VERSION ""

NS_ :

BS_:

BU_: WCM4 WCM3 WCM2 WCM VPM VLM VKM VICM VECM VDM VCU_RTOS_ETH VCU_ENTRY_ETH VCU_AGVM_ETH VCU UVM UPM TIM TEST_TOOL_1 TCP_ETH TCP TCM TCCM SRR_SRR_ETH SRR_SRR SRR_SLR_ETH SRR_SLR SRR_RR SRR_RF_ETH SRR_RF SRR_LR_CR SRR_LF_ETH SRR_LF SIB SDM SCL SBZA_R SBZA_L SBM SAM_RR SAM_RF SAM_LR SAM_LF SAM_BH SADS RadioLow_ETH RadioLow RSI_RTOS_ETH RSI RDCM PTM PLCM PFCM PDR_ETH PDR PCM PA ODS2 ODS NVM MTCM_R MTCM_L MSM_RR MSM_P MSM_LR MSM_D MSB2 MSB1 MRCM_R MRCM_L MFC LRR_RR_ETH LRR_LR_ETH LRR_CF_ETH LRR LRL_CF_ETH LIB_48V LIB1 IPC_INT IPC_GP IPC ICS_Info ICCM HVAC_FP_R HVAC_FP_F HUD_CAN HDLM FPI_RTOS_ETH FPI FOPM FCM_LC FCM EPSb EPS_1 EPSRAb EPSRAa EPS EOCM_HC_Superset EOCM_HCP2 EOCM ELM ECP_X1 ECP_S2 ECP_S ECP_MC ECP_H3 ECP_H2 ECP_H1 ECP_E ECM EBCM DMS DEFC DCM CSM_ETH CSM_AV CSM CGM_OTA_ETH CGM BSM_MH BSM_HEV BSM BCM ARS ARB APA AOS AMP ALC AHS AHL_AFL ADIMb ADIMa ACP2_MCU

BO_ 219 FCODP_BrstGrp_Prtctd_Consecuti10: 64 ACP2_MCU
 SG_ FCODPB8P_FVLBTk8CrvAuth : 3|16@0- (9.77e-07,0) [-0.0320143|0.0320134] "1/m" EOCM,EOCM_HCP2,EOCM_HC_Superset,HDLM
 SG_ FCODPB8P_FVLBTk8ClrAuth : 5|2@0+ (1,0) [0|3] "" EOCM,EOCM_HCP2,EOCM_HC_Superset,HDLM
 SG_ FCODPB8P_BrstID : 7|2@0+ (1,0) [0|3] "" EOCM,EOCM_HCP2,EOCM_HC_Superset,HDLM
 SG_ FCODPB8P_FVLBTk8CrvDrvtAuth : 19|16@0- (3.73e-09,0) [-0.000122225|0.000122221] "1/m^2" EOCM,EOCM_HCP2,EOCM_HC_Superset,HDLM
 SG_ FCODPB8P_FVLBTk8FPSABCQOvrAuth : 35|7@0+ (1,0) [0|127] "%" EOCM,EOCM_HCP2,EOCM_HC_Superset,HDLM
 SG_ FCODPB8P_FVLBTk8FPSAQAuth : 44|7@0+ (1,0) [0|127] "%" EOCM,EOCM_HCP2,EOCM_HC_Superset,HDLM
 SG_ FCODPB8P_FVLBTk8FPSBQAuth : 53|7@0+ (1,0) [0|127] "%" EOCM,EOCM_HCP2,EOCM_HC_Superset,HDLM
 SG_ FCODPB8P_FVLBTk8FPSCQAuth : 62|7@0+ (1,0) [0|127] "%" EOCM,EOCM_HCP2,EOCM_HC_Superset,HDLM
 SG_ FCODPB8P_FVLBTk8HdgAuth : 71|10@0- (0.000977,0) [-0.500224|0.499247] "" EOCM,EOCM_HCP2,EOCM_HC_Superset,HDLM
 SG_ FCODPB8P_FVLBTk8OfstAuth : 77|13@0- (0.003906,0) [-15.999|15.9951] "m" EOCM,EOCM_HCP2,EOCM_HC_Superset,HDLM
 SG_ FCODPB8P_FVLBTk8PstnTypAuth : 80|4@0+ (1,0) [0|12] "" EOCM,EOCM_HCP2,EOCM_HC_Superset,HDLM
 SG_ FCODPB8P_FVLBTk8TypAuth : 90|3@0+ (1,0) [0|7] "" EOCM,EOCM_HCP2,EOCM_HC_Superset,HDLM
 SG_ FCODPB8P_FVLBTk8QltyAuth : 92|2@0+ (1,0) [0|3] "" EOCM,EOCM_HCP2,EOCM_HC_Superset,HDLM
 SG_ FCODPB8P_FVLBTk8VSLgDistAuth : 96|7@0+ (1,0) [0|127] "m" EOCM,EOCM_HCP2,EOCM_HC_Superset,HDLM
 SG_ FCODPB8P_FVLBTk8VRLgDistAuth : 103|7@0+ (1,0) [0|127] "m" EOCM,EOCM_HCP2,EOCM_HC_Superset,HDLM
 SG_ FCODPB8P_FVLBTk8WdthAuth : 105|6@0+ (0.01,0) [0|0.63] "m" EOCM,EOCM_HCP2,EOCM_HC_Superset,HDLM
 SG_ FCODPB8P_FVVOTk8CICOPotAuth : 113|6@0+ (2,0) [0|126] "%" EOCM,EOCM_HCP2,EOCM_HC_Superset,HDLM
 SG_ FCODPB8P_FVVOTk8BrkLgtStsAuth : 115|2@0+ (1,0) [0|3] "" EOCM,EOCM_HCP2,EOCM_HC_Superset,HDLM
 SG_ FCODPB8P_FVVOTk8DynPrpAuth : 121|3@0+ (1,0) [0|6] "" EOCM,EOCM_HCP2,EOCM_HC_Superset,HDLM
 SG_ FCODPB8P_FVVOTk8CnfdStsAuth : 123|2@0+ (1,0) [0|3] "" EOCM,EOCM_HCP2,EOCM_HC_Superset,HDLM
 SG_ FCODPB8P_FVVOTk8HdgAngAuth : 133|11@0- (0.002,0) [-2.048|2.046] "rad" EOCM,EOCM_HCP2,EOCM_HC_Superset,HDLM
 SG_ FCODPB8P_FVVOTk8DynPrpStsAuth : 134|1@0+ (1,0) [0|1] "" EOCM,EOCM_HCP2,EOCM_HC_Superset,HDLM
 SG_ FCODPB8P_FVVOTk8HdgAngCAuth : 138|13@0- (0.002,0) [-8.192|8.19] "rad" EOCM,EOCM_HCP2,EOCM_HC_Superset,HDLM
 SG_ FCODPB8P_FVVOTk8IDAuth : 157|6@0+ (1,0) [0|63] "" EOCM,EOCM_HCP2,EOCM_HC_Superset,HDLM
 SG_ FCODPB8P_FVVOTk8PoILAAuth : 162|9@0- (0.125,0) [-32|31.875] "m/s^2" EOCM,EOCM_HCP2,EOCM_HC_Superset,HDLM
 SG_ FCODPB8P_FVVOTk8MStsAuth : 164|2@0+ (1,0) [0|3] "" EOCM,EOCM_HCP2,EOCM_HC_Superset,HDLM
 SG_ FCODPB8P_FVVOTk8LnAsmtAuth : 167|3@0+ (1,0) [0|5] "" EOCM,EOCM_HCP2,EOCM_HC_Superset,HDLM
 SG_ FCODPB8P_FVVOTk8PoILgAAuth : 169|9@0- (0.125,0) [-32|31.875] "m/s^2" EOCM,EOCM_HCP2,EOCM_HC_Superset,HDLM
 SG_ FCODPB8P_FVVOTk8PoILgPsAuth : 176|11@0+ (0.125,0) [0|255.875] "m" EOCM,EOCM_HCP2,EOCM_HC_Superset,HDLM
 SG_ FCODPB8P_FVVOTk8PoILgPsCAuth : 197|15@0+ (0.01,0) [0|327.67] "m^2" EOCM,EOCM_HCP2,EOCM_HC_Superset,HDLM
 SG_ FCODPB8P_FVVOTk8PoILgVAuth : 214|11@0- (0.125,0) [-128|127.875] "m/s" EOCM,EOCM_HCP2,EOCM_HC_Superset,HDLM
 SG_ FCODPB8P_FVVOTk8PoILgVCAuth : 219|10@0+ (0.125,0) [0|127.875] "(m/s)^2" EOCM,EOCM_HCP2,EOCM_HC_Superset,HDLM
 SG_ FCODPB8P_FVVOTk8PoILPsAuth : 225|10@0- (0.125,0) [-64|63.875] "m" EOCM,EOCM_HCP2,EOCM_HC_Superset,HDLM
 SG_ FCODPB8P_FVVOTk8PoILPsCAuth : 247|14@0+ (0.01,0) [0|163.83] "m^2" EOCM,EOCM_HCP2,EOCM_HC_Superset,HDLM
 SG_ FCODPB8P_FVVOTk8PoILVAuth : 249|9@0- (0.125,0) [-32|31.875] "m/s" EOCM,EOCM_HCP2,EOCM_HC_Superset,HDLM
 SG_ FCODPB8P_FVVOTk8PoILVCAuth : 256|10@0+ (0.125,0) [0|127.875] "(m/s)^2" EOCM,EOCM_HCP2,EOCM_HC_Superset,HDLM
 SG_ FCODPB8P_FVVOTk8PoIWAuth : 278|7@0+ (0.125,0) [0|15.875] "m" EOCM,EOCM_HCP2,EOCM_HC_Superset,HDLM
 SG_ FCODPB8P_FVVOTk9BrkLgtStsAuth : 280|2@0+ (1,0) [0|3] "" EOCM,EOCM_HCP2,EOCM_HC_Superset,HDLM
 SG_ FCODPB8P_FVVOTk8TypCnfdAuth : 282|2@0+ (1,0) [0|3] "" EOCM,EOCM_HCP2,EOCM_HC_Superset,HDLM
 SG_ FCODPB8P_FVVOTk8TypAuth : 284|2@0+ (1,0) [0|3] "" EOCM,EOCM_HCP2,EOCM_HC_Superset,HDLM
 SG_ FCODPB8P_FVVOTk8TSLgtStsAuth : 287|3@0+ (1,0) [0|4] "" EOCM,EOCM_HCP2,EOCM_HC_Superset,HDLM
 SG_ FCODPB8P_FVVOTk9CnfdStsAuth : 288|2@0+ (1,0) [0|3] "" EOCM,EOCM_HCP2,EOCM_HC_Superset,HDLM
 SG_ FCODPB8P_FVVOTk9CICOPotAuth : 294|6@0+ (2,0) [0|126] "%" EOCM,EOCM_HCP2,EOCM_HC_Superset,HDLM
 SG_ FCODPB8P_FVVOTk9HdgAngAuth : 298|11@0- (0.002,0) [-2.048|2.046] "rad" EOCM,EOCM_HCP2,EOCM_HC_Superset,HDLM
 SG_ FCODPB8P_FVVOTk9DynPrpStsAuth : 299|1@0+ (1,0) [0|1] "" EOCM,EOCM_HCP2,EOCM_HC_Superset,HDLM
 SG_ FCODPB8P_FVVOTk9DynPrpAuth : 302|3@0+ (1,0) [0|6] "" EOCM,EOCM_HCP2,EOCM_HC_Superset,HDLM
 SG_ FCODPB8P_FVVOTk9HdgAngCAuth : 319|13@0- (0.002,0) [-8.192|8.19] "rad" EOCM,EOCM_HCP2,EOCM_HC_Superset,HDLM
 SG_ FCODPB8P_FVVOTk9IDAuth : 322|6@0+ (1,0) [0|63] "" EOCM,EOCM_HCP2,EOCM_HC_Superset,HDLM
 SG_ FCODPB8P_FVVOTk9MStsAuth : 329|2@0+ (1,0) [0|3] "" EOCM,EOCM_HCP2,EOCM_HC_Superset,HDLM
 SG_ FCODPB8P_FVVOTk9LnAsmtAuth : 332|3@0+ (1,0) [0|5] "" EOCM,EOCM_HCP2,EOCM_HC_Superset,HDLM
 SG_ FCODPB8P_FVVOTk9PoILAAuth : 343|9@0- (0.125,0) [-32|31.875] "m/s^2" EOCM,EOCM_HCP2,EOCM_HC_Superset,HDLM
 SG_ FCODPB8P_FVVOTk9PoILgAAuth : 350|9@0- (0.125,0) [-32|31.875] "m/s^2" EOCM,EOCM_HCP2,EOCM_HC_Superset,HDLM
 SG_ FCODPB8P_FVVOTk9PoILgPsAuth : 357|11@0+ (0.125,0) [0|255.875] "m" EOCM,EOCM_HCP2,EOCM_HC_Superset,HDLM
 SG_ FCODPB8P_FVVOTk9PoILgPsCAuth : 362|15@0+ (0.01,0) [0|327.67] "m^2" EOCM,EOCM_HCP2,EOCM_HC_Superset,HDLM
 SG_ FCODPB8P_FVVOTk9PoILgVAuth : 379|11@0- (0.125,0) [-128|127.875] "m/s" EOCM,EOCM_HCP2,EOCM_HC_Superset,HDLM
 SG_ FCODPB8P_FVVOTk9PoILgVCAuth : 384|10@0+ (0.125,0) [0|127.875] "(m/s)^2" EOCM,EOCM_HCP2,EOCM_HC_Superset,HDLM
 SG_ FCODPB8P_FVVOTk9PoILPsAuth : 406|10@0- (0.125,0) [-64|63.875] "m" EOCM,EOCM_HCP2,EOCM_HC_Superset,HDLM
 SG_ FCODPB8P_FVVOTk9PoILPsCAuth : 412|14@0+ (0.01,0) [0|163.83] "m^2" EOCM,EOCM_HCP2,EOCM_HC_Superset,HDLM
 SG_ FCODPB8P_FVVOTk9PoILVAuth : 430|9@0- (0.125,0) [-32|31.875] "m/s" EOCM,EOCM_HCP2,EOCM_HC_Superset,HDLM
 SG_ FCODPB8P_FVVOTk9PoILVCAuth : 437|10@0+ (0.125,0) [0|127.875] "(m/s)^2" EOCM,EOCM_HCP2,EOCM_HC_Superset,HDLM
 SG_ FCODPB8P_FVVOTk9PoIWAuth : 443|7@0+ (0.125,0) [0|15.875] "m" EOCM,EOCM_HCP2,EOCM_HC_Superset,HDLM
 SG_ FCODPB8P_FVVOTk9TypAuth : 449|2@0+ (1,0) [0|3] "" EOCM,EOCM_HCP2,EOCM_HC_Superset,HDLM
 SG_ FCODPB8P_FVVOTk9TSLgtStsAuth : 452|3@0+ (1,0) [0|4] "" EOCM,EOCM_HCP2,EOCM_HC_Superset,HDLM
 SG_ FCODPB8P_Filler : 457|28@0+ (1,0) [0|2.68435e+008] "" EOCM,EOCM_HCP2,EOCM_HC_Superset,HDLM
 SG_ FrwdVsnVehObjTk8DatIntegCkd : 459|2@0+ (1,0) [0|2] "" EOCM,EOCM_HCP2,EOCM_HC_Superset,HDLM
 SG_ FrwdVsnLnBdryTk8DatIntegCkd : 461|2@0+ (1,0) [0|2] "" EOCM,EOCM_HCP2,EOCM_HC_Superset,HDLM
 SG_ FCODPB8P_FVVOTk9TypCnfdAuth : 463|2@0+ (1,0) [0|3] "" EOCM,EOCM_HCP2,EOCM_HC_Superset,HDLM
 SG_ FCODPB8P_FillerExtnd : 493|19@0+ (1,0) [0|524287] "" EOCM,EOCM_HCP2,EOCM_HC_Superset,HDLM

BO_ 237 FCODP_BrstGrp_Prtctd_Consecuti11: 48 ACP2_MCU
 SG_ FCODPB9P_FVCIPthVehAlrtNwAuth : 0|1@0+ (1,0) [0|1] "" EOCM,EOCM_HCP2,EOCM_HC_Superset,HDLM
 SG_ FCODPB9P_FVCIPthVehAhdNwAuth : 1|1@0+ (1,0) [0|1] "" EOCM,EOCM_HCP2,EOCM_HC_Superset,HDLM
 SG_ FCODPB9P_FrwdDistIndDgrdAuth : 2|1@0+ (1,0) [0|1] "" EOCM,EOCM_HCP2,EOCM_HC_Superset,HDLM
 SG_ FCODPB9P_FrwdClsnAlrtDgrdAuth : 3|1@0+ (1,0) [0|1] "" EOCM,EOCM_HCP2,EOCM_HC_Superset,HDLM
 SG_ FCODPB9P_ClsnImntBrkgDgrdAuth : 4|1@0+ (1,0) [0|1] "" EOCM,EOCM_HCP2,EOCM_HC_Superset,HDLM
 SG_ FCODPB9P_AdpCruzCtlDgrdAuth : 5|1@0+ (1,0) [0|1] "" EOCM,EOCM_HCP2,EOCM_HC_Superset,HDLM
 SG_ FCODPB9P_BrstID : 7|2@0+ (1,0) [0|3] "" EOCM,EOCM_HCP2,EOCM_HC_Superset,HDLM
 SG_ FCODPB9P_FVL1DrivableCnfdAuth : 11|7@0+ (1,0) [0|127] "%" EOCM,EOCM_HCP2,EOCM_HC_Superset,HDLM
 SG_ FCODPB9P_FVHTPNtfyNwAuth : 12|1@0+ (1,0) [0|1] "" EOCM,EOCM_HCP2,EOCM_HC_Superset,HDLM
 SG_ FCODPB9P_FVHTPBrkNwAuth : 13|1@0+ (1,0) [0|1] "" EOCM,EOCM_HCP2,EOCM_HC_Superset,HDLM
 SG_ FCODPB9P_FVHTPAlrtNwAuth : 14|1@0+ (1,0) [0|1] "" EOCM,EOCM_HCP2,EOCM_HC_Superset,HDLM
 SG_ FCODPB9P_FVCIPthVehBrkNwAuth : 15|1@0+ (1,0) [0|1] "" EOCM,EOCM_HCP2,EOCM_HC_Superset,HDLM
 SG_ FCODPB9P_FVL2DrivableCnfdAuth : 20|7@0+ (1,0) [0|127] "%" EOCM,EOCM_HCP2,EOCM_HC_Superset,HDLM
 SG_ FCODPB9P_FVL3DrivableCnfdAuth : 29|7@0+ (1,0) [0|127] "%" EOCM,EOCM_HCP2,EOCM_HC_Superset,HDLM
 SG_ FCODPB9P_FVL4DrivableCnfdAuth : 38|7@0+ (1,0) [0|127] "%" EOCM,EOCM_HCP2,EOCM_HC_Superset,HDLM
 SG_ FCODPB9P_FVLFTk1FPCrvCoefAuth : 40|16@0- (9.77e-07,0) [-0.0320143|0.0320134] "1/m" EOCM,EOCM_HCP2,EOCM_HC_Superset,HDLM
 SG_ FCODPB9P_FVL5DrivableCnfdAuth : 47|7@0+ (1,0) [0|127] "%" EOCM,EOCM_HCP2,EOCM_HC_Superset,HDLM
 SG_ FCODPB9P_FVLFTk1FPCrvDrvtCAuth : 56|16@0- (3.73e-09,0) [-0.000122225|0.000122221] "1/m^2" EOCM,EOCM_HCP2,EOCM_HC_Superset,HDLM
 SG_ FCODPB9P_FVLFTk1FPHdgCoefAuth : 72|10@0- (0.000977,0) [-0.500224|0.499247] "rad" EOCM,EOCM_HCP2,EOCM_HC_Superset,HDLM
 SG_ FCODPB9P_FVLFTk1FPOfstCoefAuth : 94|12@0- (0.003906,0) [-7.99949|7.99558] "m" EOCM,EOCM_HCP2,EOCM_HC_Superset,HDLM
 SG_ FCODPB9P_FVLFTk1FPSegQltyAuth : 98|7@0+ (1,0) [0|127] "%" EOCM,EOCM_HCP2,EOCM_HC_Superset,HDLM
 SG_ FCODPB9P_FVLFTk1FPVRLgDistAuth : 107|7@0+ (1,0) [0|127] "m" EOCM,EOCM_HCP2,EOCM_HC_Superset,HDLM
 SG_ FCODPB9P_FVLFTk1FPVSLgDistAuth : 116|7@0+ (1,0) [0|127] "m" EOCM,EOCM_HCP2,EOCM_HC_Superset,HDLM
 SG_ FCODPB9P_FVLFTk2FPCrvCoefAuth : 123|16@0- (9.77e-07,0) [-0.0320143|0.0320134] "1/m" EOCM,EOCM_HCP2,EOCM_HC_Superset,HDLM
 SG_ FCODPB9P_FVLFTk1TypAuth : 125|2@0+ (1,0) [0|3] "" EOCM,EOCM_HCP2,EOCM_HC_Superset,HDLM
 SG_ FCODPB9P_FVLFTk2FPCrvDrvtCAuth : 139|16@0- (3.73e-09,0) [-0.000122225|0.000122221] "1/m^2" EOCM,EOCM_HCP2,EOCM_HC_Superset,HDLM
 SG_ FCODPB9P_FVLFTk2FPHdgCoefAuth : 155|10@0- (0.000977,0) [-0.500224|0.499247] "rad" EOCM,EOCM_HCP2,EOCM_HC_Superset,HDLM
 SG_ FCODPB9P_FVLFTk2FPOfstCoefAuth : 161|12@0- (0.003906,0) [-7.99949|7.99558] "m" EOCM,EOCM_HCP2,EOCM_HC_Superset,HDLM
 SG_ FCODPB9P_FVLFTk2FPSegQltyAuth : 181|7@0+ (1,0) [0|127] "%" EOCM,EOCM_HCP2,EOCM_HC_Superset,HDLM
 SG_ FCODPB9P_FVLFTk2FPVRLgDistAuth : 190|7@0+ (1,0) [0|127] "m" EOCM,EOCM_HCP2,EOCM_HC_Superset,HDLM
 SG_ FCODPB9P_FVLFTk2TypAuth : 192|2@0+ (1,0) [0|3] "" EOCM,EOCM_HCP2,EOCM_HC_Superset,HDLM
 SG_ FCODPB9P_FVLFTk2FPVSLgDistAuth : 199|7@0+ (1,0) [0|127] "m" EOCM,EOCM_HCP2,EOCM_HC_Superset,HDLM
 SG_ FCODPB9P_FVLFTk3FPCrvCoefAuth : 206|16@0- (9.77e-07,0) [-0.0320143|0.0320134] "1/m" EOCM,EOCM_HCP2,EOCM_HC_Superset,HDLM
 SG_ FCODPB9P_FVLFTk3FPCrvDrvtCAuth : 222|16@0- (3.73e-09,0) [-0.000122225|0.000122221] "1/m^2" EOCM,EOCM_HCP2,EOCM_HC_Superset,HDLM
 SG_ FCODPB9P_FVLFTk3FPHdgCoefAuth : 238|10@0- (0.000977,0) [-0.500224|0.499247] "rad" EOCM,EOCM_HCP2,EOCM_HC_Superset,HDLM
 SG_ FCODPB9P_FVLFTk3FPOfstCoefAuth : 244|12@0- (0.003906,0) [-7.99949|7.99558] "m" EOCM,EOCM_HCP2,EOCM_HC_Superset,HDLM
 SG_ FCODPB9P_FVLFTk3FPSegQltyAuth : 248|7@0+ (1,0) [0|127] "%" EOCM,EOCM_HCP2,EOCM_HC_Superset,HDLM
 SG_ FCODPB9P_FVLFTk3FPVRLgDistAuth : 257|7@0+ (1,0) [0|127] "m" EOCM,EOCM_HCP2,EOCM_HC_Superset,HDLM
 SG_ FCODPB9P_FVLFTk3FPVSLgDistAuth : 266|7@0+ (1,0) [0|127] "m" EOCM,EOCM_HCP2,EOCM_HC_Superset,HDLM
 SG_ FCODPB9P_FVLFTk4FPCrvCoefAuth : 273|16@0- (9.77e-07,0) [-0.0320143|0.0320134] "1/m" EOCM,EOCM_HCP2,EOCM_HC_Superset,HDLM
 SG_ FCODPB9P_FVLFTk3TypAuth : 275|2@0+ (1,0) [0|3] "" EOCM,EOCM_HCP2,EOCM_HC_Superset,HDLM
 SG_ FCODPB9P_FVLFTk4FPCrvDrvtCAuth : 289|16@0- (3.73e-09,0) [-0.000122225|0.000122221] "1/m^2" EOCM,EOCM_HCP2,EOCM_HC_Superset,HDLM
 SG_ FCODPB9P_FVLFTk4FPHdgCoefAuth : 305|10@0- (0.000977,0) [-0.500224|0.499247] "rad" EOCM,EOCM_HCP2,EOCM_HC_Superset,HDLM
 SG_ FCODPB9P_FVLFTk4FPOfstCoefAuth : 327|12@0- (0.003906,0) [-7.99949|7.99558] "m" EOCM,EOCM_HCP2,EOCM_HC_Superset,HDLM
 SG_ FCODPB9P_FVLFTk4FPSegQltyAuth : 331|7@0+ (1,0) [0|127] "%" EOCM,EOCM_HCP2,EOCM_HC_Superset,HDLM
 SG_ FCODPB9P_FVLFTk4FPVRLgDistAuth : 340|7@0+ (1,0) [0|127] "m" EOCM,EOCM_HCP2,EOCM_HC_Superset,HDLM
 SG_ FCODPB9P_FVLFTk4FPVSLgDistAuth : 349|7@0+ (1,0) [0|127] "m" EOCM,EOCM_HCP2,EOCM_HC_Superset,HDLM
 SG_ FCODPB9P_PedtrnClsnBrkgDgrdAuth : 352|1@0+ (1,0) [0|1] "" EOCM,EOCM_HCP2,EOCM_HC_Superset,HDLM
 SG_ FCODPB9P_PedtrnClsnAlrtDgrdAuth : 353|1@0+ (1,0) [0|1] "" EOCM,EOCM_HCP2,EOCM_HC_Superset,HDLM
 SG_ FCODPB9P_LnKeepAsstDgrdAuth : 354|1@0+ (1,0) [0|1] "" EOCM,EOCM_HCP2,EOCM_HC_Superset,HDLM
 SG_ FCODPB9P_LnCntrDgrdAuth : 355|1@0+ (1,0) [0|1] "" EOCM,EOCM_HCP2,EOCM_HC_Superset,HDLM
 SG_ FCODPB9P_IntsctClsnMtgnDgrdAuth : 356|1@0+ (1,0) [0|1] "" EOCM,EOCM_HCP2,EOCM_HC_Superset,HDLM
 SG_ FCODPB9P_FVLFTk4TypAuth : 358|2@0+ (1,0) [0|3] "" EOCM,EOCM_HCP2,EOCM_HC_Superset,HDLM
 SG_ FCODPB9P_Filler : 360|17@0+ (1,0) [0|131071] "" EOCM,EOCM_HCP2,EOCM_HC_Superset,HDLM
 SG_ FrwdVsnVehObjTk9DatIntegCkd : 362|2@0+ (1,0) [0|2] "" EOCM,EOCM_HCP2,EOCM_HC_Superset,HDLM
 SG_ FrwdVsnLnBdryTk9DatIntegCkd : 364|2@0+ (1,0) [0|2] "" EOCM,EOCM_HCP2,EOCM_HC_Superset,HDLM
 SG_ FCODPB9P_FVHTPPrfllNwAuth : 365|1@0+ (1,0) [0|1] "" EOCM,EOCM_HCP2,EOCM_HC_Superset,HDLM
 SG_ FCODPB9P_FVCIPthVehPrfllNwAuth : 366|1@0+ (1,0) [0|1] "" EOCM,EOCM_HCP2,EOCM_HC_Superset,HDLM
 SG_ FCODPB9P_PedtrnNtfnDgrdAuth : 367|1@0+ (1,0) [0|1] "" EOCM,EOCM_HCP2,EOCM_HC_Superset,HDLM

BO_ 218 FCODP_BrstGrp_Prtctd_Consecuti12: 64 ACP2_MCU
 SG_ FCODPB10P_FVVOTk10PoI2LgPsAuth : 3|11@0+ (0.125,0) [0|255.875] "m" EOCM,EOCM_HCP2,EOCM_HC_Superset,HDLM
 SG_ FCODPB10P_FVVOTk10PoI1PsVisAuth : 5|2@0+ (1,0) [0|2] "" EOCM,EOCM_HCP2,EOCM_HC_Superset,HDLM
 SG_ FCODPB10P_BrstID : 7|2@0+ (1,0) [0|3] "" EOCM,EOCM_HCP2,EOCM_HC_Superset,HDLM
 SG_ FCODPB10P_FVVOTk10PoI2LPsAuth : 8|10@0+ (0.125,-64) [-64|63.875] "m" EOCM,EOCM_HCP2,EOCM_HC_Superset,HDLM
 SG_ FCODPB10P_FVVOTk10PoI3LgPsAuth : 28|11@0+ (0.125,0) [0|255.875] "m" EOCM,EOCM_HCP2,EOCM_HC_Superset,HDLM
 SG_ FCODPB10P_FVVOTk10PoI2PsVisAuth : 30|2@0+ (1,0) [0|2] "" EOCM,EOCM_HCP2,EOCM_HC_Superset,HDLM
 SG_ FCODPB10P_FVVOTk10PoI3LPsAuth : 33|10@0+ (0.125,-64) [-64|63.875] "m" EOCM,EOCM_HCP2,EOCM_HC_Superset,HDLM
 SG_ FCODPB10P_FVVOTk1PoI2LgPsAuth : 51|11@0+ (0.125,0) [0|255.875] "m" EOCM,EOCM_HCP2,EOCM_HC_Superset,HDLM
 SG_ FCODPB10P_FVVOTk1PoI1PsVisAuth : 53|2@0+ (1,0) [0|2] "" EOCM,EOCM_HCP2,EOCM_HC_Superset,HDLM
 SG_ FCODPB10P_FVVOTk10PoI3PsVisAuth : 55|2@0+ (1,0) [0|2] "" EOCM,EOCM_HCP2,EOCM_HC_Superset,HDLM
 SG_ FCODPB10P_FVVOTk1PoI2LPsAuth : 56|10@0+ (0.125,-64) [-64|63.875] "m" EOCM,EOCM_HCP2,EOCM_HC_Superset,HDLM
 SG_ FCODPB10P_FVVOTk1PoI3LgPsAuth : 76|11@0+ (0.125,0) [0|255.875] "m" EOCM,EOCM_HCP2,EOCM_HC_Superset,HDLM
 SG_ FCODPB10P_FVVOTk1PoI2PsVisAuth : 78|2@0+ (1,0) [0|2] "" EOCM,EOCM_HCP2,EOCM_HC_Superset,HDLM
 SG_ FCODPB10P_FVVOTk1PoI3LPsAuth : 81|10@0+ (0.125,-64) [-64|63.875] "m" EOCM,EOCM_HCP2,EOCM_HC_Superset,HDLM
 SG_ FCODPB10P_FVVOTk2PoI2LgPsAuth : 99|11@0+ (0.125,0) [0|255.875] "m" EOCM,EOCM_HCP2,EOCM_HC_Superset,HDLM
 SG_ FCODPB10P_FVVOTk2PoI1PsVisAuth : 101|2@0+ (1,0) [0|2] "" EOCM,EOCM_HCP2,EOCM_HC_Superset,HDLM
 SG_ FCODPB10P_FVVOTk1PoI3PsVisAuth : 103|2@0+ (1,0) [0|2] "" EOCM,EOCM_HCP2,EOCM_HC_Superset,HDLM
 SG_ FCODPB10P_FVVOTk2PoI2LPsAuth : 104|10@0+ (0.125,-64) [-64|63.875] "m" EOCM,EOCM_HCP2,EOCM_HC_Superset,HDLM
 SG_ FCODPB10P_FVVOTk2PoI3LgPsAuth : 124|11@0+ (0.125,0) [0|255.875] "m" EOCM,EOCM_HCP2,EOCM_HC_Superset,HDLM
 SG_ FCODPB10P_FVVOTk2PoI2PsVisAuth : 126|2@0+ (1,0) [0|2] "" EOCM,EOCM_HCP2,EOCM_HC_Superset,HDLM
 SG_ FCODPB10P_FVVOTk2PoI3LPsAuth : 129|10@0+ (0.125,-64) [-64|63.875] "m" EOCM,EOCM_HCP2,EOCM_HC_Superset,HDLM
 SG_ FCODPB10P_FVVOTk3PoI2LgPsAuth : 147|11@0+ (0.125,0) [0|255.875] "m" EOCM,EOCM_HCP2,EOCM_HC_Superset,HDLM
 SG_ FCODPB10P_FVVOTk3PoI1PsVisAuth : 149|2@0+ (1,0) [0|2] "" EOCM,EOCM_HCP2,EOCM_HC_Superset,HDLM
 SG_ FCODPB10P_FVVOTk2PoI3PsVisAuth : 151|2@0+ (1,0) [0|2] "" EOCM,EOCM_HCP2,EOCM_HC_Superset,HDLM
 SG_ FCODPB10P_FVVOTk3PoI2LPsAuth : 152|10@0+ (0.125,-64) [-64|63.875] "m" EOCM,EOCM_HCP2,EOCM_HC_Superset,HDLM
 SG_ FCODPB10P_FVVOTk3PoI3LgPsAuth : 172|11@0+ (0.125,0) [0|255.875] "m" EOCM,EOCM_HCP2,EOCM_HC_Superset,HDLM
 SG_ FCODPB10P_FVVOTk3PoI2PsVisAuth : 174|2@0+ (1,0) [0|2] "" EOCM,EOCM_HCP2,EOCM_HC_Superset,HDLM
 SG_ FCODPB10P_FVVOTk3PoI3LPsAuth : 177|10@0+ (0.125,-64) [-64|63.875] "m" EOCM,EOCM_HCP2,EOCM_HC_Superset,HDLM
 SG_ FCODPB10P_FVVOTk4PoI2LgPsAuth : 195|11@0+ (0.125,0) [0|255.875] "m" EOCM,EOCM_HCP2,EOCM_HC_Superset,HDLM
 SG_ FCODPB10P_FVVOTk4PoI1PsVisAuth : 197|2@0+ (1,0) [0|2] "" EOCM,EOCM_HCP2,EOCM_HC_Superset,HDLM
 SG_ FCODPB10P_FVVOTk3PoI3PsVisAuth : 199|2@0+ (1,0) [0|2] "" EOCM,EOCM_HCP2,EOCM_HC_Superset,HDLM
 SG_ FCODPB10P_FVVOTk4PoI2LPsAuth : 200|10@0+ (0.125,-64) [-64|63.875] "m" EOCM,EOCM_HCP2,EOCM_HC_Superset,HDLM
 SG_ FCODPB10P_FVVOTk4PoI3LgPsAuth : 220|11@0+ (0.125,0) [0|255.875] "m" EOCM,EOCM_HCP2,EOCM_HC_Superset,HDLM
 SG_ FCODPB10P_FVVOTk4PoI2PsVisAuth : 222|2@0+ (1,0) [0|2] "" EOCM,EOCM_HCP2,EOCM_HC_Superset,HDLM
 SG_ FCODPB10P_FVVOTk4PoI3LPsAuth : 225|10@0+ (0.125,-64) [-64|63.875] "m" EOCM,EOCM_HCP2,EOCM_HC_Superset,HDLM
 SG_ FCODPB10P_FVVOTk5PoI2LgPsAuth : 243|11@0+ (0.125,0) [0|255.875] "m" EOCM,EOCM_HCP2,EOCM_HC_Superset,HDLM
 SG_ FCODPB10P_FVVOTk5PoI1PsVisAuth : 245|2@0+ (1,0) [0|2] "" EOCM,EOCM_HCP2,EOCM_HC_Superset,HDLM
 SG_ FCODPB10P_FVVOTk4PoI3PsVisAuth : 247|2@0+ (1,0) [0|2] "" EOCM,EOCM_HCP2,EOCM_HC_Superset,HDLM
 SG_ FCODPB10P_FVVOTk5PoI2LPsAuth : 248|10@0+ (0.125,-64) [-64|63.875] "m" EOCM,EOCM_HCP2,EOCM_HC_Superset,HDLM
 SG_ FCODPB10P_FVVOTk5PoI3LgPsAuth : 268|11@0+ (0.125,0) [0|255.875] "m" EOCM,EOCM_HCP2,EOCM_HC_Superset,HDLM
 SG_ FCODPB10P_FVVOTk5PoI2PsVisAuth : 270|2@0+ (1,0) [0|2] "" EOCM,EOCM_HCP2,EOCM_HC_Superset,HDLM
 SG_ FCODPB10P_FVVOTk5PoI3LPsAuth : 273|10@0+ (0.125,-64) [-64|63.875] "m" EOCM,EOCM_HCP2,EOCM_HC_Superset,HDLM
 SG_ FCODPB10P_FVVOTk6PoI2LgPsAuth : 291|11@0+ (0.125,0) [0|255.875] "m" EOCM,EOCM_HCP2,EOCM_HC_Superset,HDLM
 SG_ FCODPB10P_FVVOTk6PoI1PsVisAuth : 293|2@0+ (1,0) [0|2] "" EOCM,EOCM_HCP2,EOCM_HC_Superset,HDLM
 SG_ FCODPB10P_FVVOTk5PoI3PsVisAuth : 295|2@0+ (1,0) [0|2] "" EOCM,EOCM_HCP2,EOCM_HC_Superset,HDLM
 SG_ FCODPB10P_FVVOTk6PoI2LPsAuth : 296|10@0+ (0.125,-64) [-64|63.875] "m" EOCM,EOCM_HCP2,EOCM_HC_Superset,HDLM
 SG_ FCODPB10P_FVVOTk6PoI3LgPsAuth : 316|11@0+ (0.125,0) [0|255.875] "m" EOCM,EOCM_HCP2,EOCM_HC_Superset,HDLM
 SG_ FCODPB10P_FVVOTk6PoI2PsVisAuth : 318|2@0+ (1,0) [0|2] "" EOCM,EOCM_HCP2,EOCM_HC_Superset,HDLM
 SG_ FCODPB10P_FVVOTk6PoI3LPsAuth : 321|10@0+ (0.125,-64) [-64|63.875] "m" EOCM,EOCM_HCP2,EOCM_HC_Superset,HDLM
 SG_ FCODPB10P_FVVOTk7PoI2LgPsAuth : 339|11@0+ (0.125,0) [0|255.875] "m" EOCM,EOCM_HCP2,EOCM_HC_Superset,HDLM
 SG_ FCODPB10P_FVVOTk7PoI1PsVisAuth : 341|2@0+ (1,0) [0|2] "" EOCM,EOCM_HCP2,EOCM_HC_Superset,HDLM
 SG_ FCODPB10P_FVVOTk6PoI3PsVisAuth : 343|2@0+ (1,0) [0|2] "" EOCM,EOCM_HCP2,EOCM_HC_Superset,HDLM
 SG_ FCODPB10P_FVVOTk7PoI2LPsAuth : 344|10@0+ (0.125,-64) [-64|63.875] "m" EOCM,EOCM_HCP2,EOCM_HC_Superset,HDLM
 SG_ FCODPB10P_FVVOTk7PoI3LgPsAuth : 364|11@0+ (0.125,0) [0|255.875] "m" EOCM,EOCM_HCP2,EOCM_HC_Superset,HDLM
 SG_ FCODPB10P_FVVOTk7PoI2PsVisAuth : 366|2@0+ (1,0) [0|2] "" EOCM,EOCM_HCP2,EOCM_HC_Superset,HDLM
 SG_ FCODPB10P_FVVOTk7PoI3LPsAuth : 369|10@0+ (0.125,-64) [-64|63.875] "m" EOCM,EOCM_HCP2,EOCM_HC_Superset,HDLM
 SG_ FCODPB10P_FVVOTk8PoI2LgPsAuth : 387|11@0+ (0.125,0) [0|255.875] "m" EOCM,EOCM_HCP2,EOCM_HC_Superset,HDLM
 SG_ FCODPB10P_FVVOTk8PoI1PsVisAuth : 389|2@0+ (1,0) [0|2] "" EOCM,EOCM_HCP2,EOCM_HC_Superset,HDLM
 SG_ FCODPB10P_FVVOTk7PoI3PsVisAuth : 391|2@0+ (1,0) [0|2] "" EOCM,EOCM_HCP2,EOCM_HC_Superset,HDLM
 SG_ FCODPB10P_FVVOTk8PoI2LPsAuth : 392|10@0+ (0.125,-64) [-64|63.875] "m" EOCM,EOCM_HCP2,EOCM_HC_Superset,HDLM
 SG_ FCODPB10P_FVVOTk8PoI3LgPsAuth : 412|11@0+ (0.125,0) [0|255.875] "m" EOCM,EOCM_HCP2,EOCM_HC_Superset,HDLM
 SG_ FCODPB10P_FVVOTk8PoI2PsVisAuth : 414|2@0+ (1,0) [0|2] "" EOCM,EOCM_HCP2,EOCM_HC_Superset,HDLM
 SG_ FCODPB10P_FVVOTk8PoI3LPsAuth : 417|10@0+ (0.125,-64) [-64|63.875] "m" EOCM,EOCM_HCP2,EOCM_HC_Superset,HDLM
 SG_ FCODPB10P_FVVOTk9PoI2LgPsAuth : 435|11@0+ (0.125,0) [0|255.875] "m" EOCM,EOCM_HCP2,EOCM_HC_Superset,HDLM
 SG_ FCODPB10P_FVVOTk9PoI1PsVisAuth : 437|2@0+ (1,0) [0|2] "" EOCM,EOCM_HCP2,EOCM_HC_Superset,HDLM
 SG_ FCODPB10P_FVVOTk8PoI3PsVisAuth : 439|2@0+ (1,0) [0|2] "" EOCM,EOCM_HCP2,EOCM_HC_Superset,HDLM
 SG_ FCODPB10P_FVVOTk9PoI2LPsAuth : 440|10@0+ (0.125,-64) [-64|63.875] "m" EOCM,EOCM_HCP2,EOCM_HC_Superset,HDLM
 SG_ FCODPB10P_FVVOTk9PoI3LgPsAuth : 460|11@0+ (0.125,0) [0|255.875] "m" EOCM,EOCM_HCP2,EOCM_HC_Superset,HDLM
 SG_ FCODPB10P_FVVOTk9PoI2PsVisAuth : 462|2@0+ (1,0) [0|2] "" EOCM,EOCM_HCP2,EOCM_HC_Superset,HDLM
 SG_ FCODPB10P_FVVOTk9PoI3LPsAuth : 465|10@0+ (0.125,-64) [-64|63.875] "m" EOCM,EOCM_HCP2,EOCM_HC_Superset,HDLM
 SG_ FCODPB10P_Filler : 481|26@0+ (1,0) [0|6.71089e+007] "" EOCM,EOCM_HCP2,EOCM_HC_Superset,HDLM
 SG_ FrwdVsnVehObjTk10DatIntegCkd : 483|2@0+ (1,0) [0|2] "" EOCM,EOCM_HCP2,EOCM_HC_Superset,HDLM
 SG_ FrwdVsnLnBdryTk10DatIntegCkd : 485|2@0+ (1,0) [0|2] "" EOCM,EOCM_HCP2,EOCM_HC_Superset,HDLM
 SG_ FCODPB10P_FVVOTk9PoI3PsVisAuth : 487|2@0+ (1,0) [0|2] "" EOCM,EOCM_HCP2,EOCM_HC_Superset,HDLM

BO_ 233 FCODP_BrstGrp_Prtctd_First_Frame: 64 ACP2_MCU
 SG_ FCODPB1P_MAC : 7|32@0+ (1,0) [0|4.29497e+009] "" EOCM,EOCM_HCP2,EOCM_HC_Superset,HDLM
 SG_ FCODPB1P_FCnt : 39|5@0+ (1,0) [0|31] "" EOCM,EOCM_HCP2,EOCM_HC_Superset,HDLM
 SG_ FCODPB1P_FVLBTk1CrvAuth : 43|16@0- (9.77e-07,0) [-0.0320143|0.0320134] "1/m" EOCM,EOCM_HCP2,EOCM_HC_Superset,HDLM
 SG_ FCODPB1P_FVLBTk1ClrAuth : 45|2@0+ (1,0) [0|3] "" EOCM,EOCM_HCP2,EOCM_HC_Superset,HDLM
 SG_ FCODPB1P_BrstID : 47|2@0+ (1,0) [0|3] "" EOCM,EOCM_HCP2,EOCM_HC_Superset,HDLM
 SG_ FCODPB1P_FVLBTk1CrvDrvtAuth : 59|16@0- (3.73e-09,0) [-0.000122225|0.000122221] "1/m^2" EOCM,EOCM_HCP2,EOCM_HC_Superset,HDLM
 SG_ FCODPB1P_FVLBTk1FPSABCQOvrAuth : 75|7@0+ (1,0) [0|127] "%" EOCM,EOCM_HCP2,EOCM_HC_Superset,HDLM
 SG_ FCODPB1P_FVLBTk1FPSAQAuth : 84|7@0+ (1,0) [0|127] "%" EOCM,EOCM_HCP2,EOCM_HC_Superset,HDLM
 SG_ FCODPB1P_FVLBTk1FPSBQAuth : 93|7@0+ (1,0) [0|127] "%" EOCM,EOCM_HCP2,EOCM_HC_Superset,HDLM
 SG_ FCODPB1P_FVLBTk1FPSCQAuth : 102|7@0+ (1,0) [0|127] "%" EOCM,EOCM_HCP2,EOCM_HC_Superset,HDLM
 SG_ FCODPB1P_FVLBTk1HdgAuth : 111|10@0- (0.000977,0) [-0.500224|0.499247] "" EOCM,EOCM_HCP2,EOCM_HC_Superset,HDLM
 SG_ FCODPB1P_FVLBTk1OfstAuth : 117|13@0- (0.003906,0) [-15.999|15.9951] "m" EOCM,EOCM_HCP2,EOCM_HC_Superset,HDLM
 SG_ FCODPB1P_FVLBTk1PstnTypAuth : 120|4@0+ (1,0) [0|12] "" EOCM,EOCM_HCP2,EOCM_HC_Superset,HDLM
 SG_ FCODPB1P_FVLBTk1TypAuth : 130|3@0+ (1,0) [0|7] "" EOCM,EOCM_HCP2,EOCM_HC_Superset,HDLM
 SG_ FCODPB1P_FVLBTk1QltyAuth : 132|2@0+ (1,0) [0|3] "" EOCM,EOCM_HCP2,EOCM_HC_Superset,HDLM
 SG_ FCODPB1P_FVLBTk1VSLgDistAuth : 136|7@0+ (1,0) [0|127] "m" EOCM,EOCM_HCP2,EOCM_HC_Superset,HDLM
 SG_ FCODPB1P_FVLBTk1VRLgDistAuth : 143|7@0+ (1,0) [0|127] "m" EOCM,EOCM_HCP2,EOCM_HC_Superset,HDLM
 SG_ FCODPB1P_FVLBTk1WdthAuth : 145|6@0+ (0.01,0) [0|0.63] "m" EOCM,EOCM_HCP2,EOCM_HC_Superset,HDLM
 SG_ FCODPB1P_FVPOTk1DynPrpAuth : 153|3@0+ (1,0) [0|4] "" EOCM,EOCM_HCP2,EOCM_HC_Superset,HDLM
 SG_ FCODPB1P_FVPOTk1CnfdStsAuth : 155|2@0+ (1,0) [0|3] "" EOCM,EOCM_HCP2,EOCM_HC_Superset,HDLM
 SG_ FCODPB1P_FVPOTk1InPthPotAuth : 160|6@0+ (2,0) [0|126] "%" EOCM,EOCM_HCP2,EOCM_HC_Superset,HDLM
 SG_ FCODPB1P_FVPOTk1IDAuth : 166|6@0+ (1,0) [0|63] "" EOCM,EOCM_HCP2,EOCM_HC_Superset,HDLM
 SG_ FCODPB1P_FVPOTk1PoILAAuth : 168|9@0- (0.125,0) [-32|31.875] "m/s^2" EOCM,EOCM_HCP2,EOCM_HC_Superset,HDLM
 SG_ FCODPB1P_FVPOTk1MStsAuth : 170|2@0+ (1,0) [0|3] "" EOCM,EOCM_HCP2,EOCM_HC_Superset,HDLM
 SG_ FCODPB1P_FVPOTk1PoILgAAuth : 191|9@0- (0.125,0) [-32|31.875] "m/s^2" EOCM,EOCM_HCP2,EOCM_HC_Superset,HDLM
 SG_ FCODPB1P_FVPOTk1PoILgPsAuth : 198|11@0+ (0.125,0) [0|255.875] "m" EOCM,EOCM_HCP2,EOCM_HC_Superset,HDLM
 SG_ FCODPB1P_FVPOTk1PoILgVAuth : 203|10@0- (0.125,0) [-64|63.875] "m/s" EOCM,EOCM_HCP2,EOCM_HC_Superset,HDLM
 SG_ FCODPB1P_FVPOTk1PoILPsAuth : 209|10@0- (0.125,0) [-64|63.875] "m" EOCM,EOCM_HCP2,EOCM_HC_Superset,HDLM
 SG_ FCODPB1P_FVPOTk1PoILVAuth : 231|9@0- (0.125,0) [-32|31.875] "m/s" EOCM,EOCM_HCP2,EOCM_HC_Superset,HDLM
 SG_ FCODPB1P_FVVOTk1CICOPotAuth : 232|6@0+ (2,0) [0|126] "%" EOCM,EOCM_HCP2,EOCM_HC_Superset,HDLM
 SG_ FCODPB1P_FVVOTk1BrkLgtStsAuth : 234|2@0+ (1,0) [0|3] "" EOCM,EOCM_HCP2,EOCM_HC_Superset,HDLM
 SG_ FCODPB1P_FVPOTk1TypCnfdAuth : 236|2@0+ (1,0) [0|3] "" EOCM,EOCM_HCP2,EOCM_HC_Superset,HDLM
 SG_ FCODPB1P_FVPOTk1TypAuth : 238|2@0+ (1,0) [0|2] "" EOCM,EOCM_HCP2,EOCM_HC_Superset,HDLM
 SG_ FCODPB1P_FVVOTk1DynPrpAuth : 240|3@0+ (1,0) [0|6] "" EOCM,EOCM_HCP2,EOCM_HC_Superset,HDLM
 SG_ FCODPB1P_FVVOTk1CnfdStsAuth : 242|2@0+ (1,0) [0|3] "" EOCM,EOCM_HCP2,EOCM_HC_Superset,HDLM
 SG_ FCODPB1P_FVVOTk1HdgAngAuth : 252|11@0- (0.002,0) [-2.048|2.046] "rad" EOCM,EOCM_HCP2,EOCM_HC_Superset,HDLM
 SG_ FCODPB1P_FVVOTk1DynPrpStsAuth : 253|1@0+ (1,0) [0|1] "" EOCM,EOCM_HCP2,EOCM_HC_Superset,HDLM
 SG_ FCODPB1P_FVVOTk1HdgAngCAuth : 257|13@0- (0.002,0) [-8.192|8.19] "rad" EOCM,EOCM_HCP2,EOCM_HC_Superset,HDLM
 SG_ FCODPB1P_FVVOTk1IDAuth : 276|6@0+ (1,0) [0|63] "" EOCM,EOCM_HCP2,EOCM_HC_Superset,HDLM
 SG_ FCODPB1P_FVVOTk1PoILAAuth : 281|9@0- (0.125,0) [-32|31.875] "m/s^2" EOCM,EOCM_HCP2,EOCM_HC_Superset,HDLM
 SG_ FCODPB1P_FVVOTk1MStsAuth : 283|2@0+ (1,0) [0|3] "" EOCM,EOCM_HCP2,EOCM_HC_Superset,HDLM
 SG_ FCODPB1P_FVVOTk1LnAsmtAuth : 286|3@0+ (1,0) [0|5] "" EOCM,EOCM_HCP2,EOCM_HC_Superset,HDLM
 SG_ FCODPB1P_FVVOTk1PoILgAAuth : 288|9@0- (0.125,0) [-32|31.875] "m/s^2" EOCM,EOCM_HCP2,EOCM_HC_Superset,HDLM
 SG_ FCODPB1P_FVVOTk1PoILgPsAuth : 311|11@0+ (0.125,0) [0|255.875] "m" EOCM,EOCM_HCP2,EOCM_HC_Superset,HDLM
 SG_ FCODPB1P_FVVOTk1PoILgPsCAuth : 316|15@0+ (0.01,0) [0|327.67] "m^2" EOCM,EOCM_HCP2,EOCM_HC_Superset,HDLM
 SG_ FCODPB1P_FVVOTk1PoILgVAuth : 333|11@0- (0.125,0) [-128|127.875] "m/s" EOCM,EOCM_HCP2,EOCM_HC_Superset,HDLM
 SG_ FCODPB1P_FVVOTk1PoILgVCAuth : 338|10@0+ (0.125,0) [0|127.875] "(m/s)^2" EOCM,EOCM_HCP2,EOCM_HC_Superset,HDLM
 SG_ FCODPB1P_FVVOTk1PoILPsAuth : 344|10@0- (0.125,0) [-64|63.875] "m" EOCM,EOCM_HCP2,EOCM_HC_Superset,HDLM
 SG_ FCODPB1P_FVVOTk1PoILPsCAuth : 366|14@0+ (0.01,0) [0|163.83] "m^2" EOCM,EOCM_HCP2,EOCM_HC_Superset,HDLM
 SG_ FCODPB1P_FVVOTk1PoILVAuth : 368|9@0- (0.125,0) [-32|31.875] "m/s" EOCM,EOCM_HCP2,EOCM_HC_Superset,HDLM
 SG_ FCODPB1P_FVVOTk1PoILVCAuth : 391|10@0+ (0.125,0) [0|127.875] "(m/s)^2" EOCM,EOCM_HCP2,EOCM_HC_Superset,HDLM
 SG_ FCODPB1P_FVVOTk1PoIWAuth : 397|7@0+ (0.125,0) [0|15.875] "m" EOCM,EOCM_HCP2,EOCM_HC_Superset,HDLM
 SG_ FCODPB1P_FVVOTk1TypCnfdAuth : 401|2@0+ (1,0) [0|3] "" EOCM,EOCM_HCP2,EOCM_HC_Superset,HDLM
 SG_ FCODPB1P_FVVOTk1TypAuth : 403|2@0+ (1,0) [0|3] "" EOCM,EOCM_HCP2,EOCM_HC_Superset,HDLM
 SG_ FCODPB1P_FVVOTk1TSLgtStsAuth : 406|3@0+ (1,0) [0|4] "" EOCM,EOCM_HCP2,EOCM_HC_Superset,HDLM
 SG_ FCODPB1P_FVVOTk10VehLnCrsTmAuth : 413|9@0- (0.05,0) [-12.8|12.75] "s" EOCM,EOCM_HCP2,EOCM_HC_Superset,HDLM
 SG_ FCODPB1P_ARC : 415|2@0+ (1,0) [0|3] "" EOCM,EOCM_HCP2,EOCM_HC_Superset,HDLM
 SG_ FCODPB1P_FVVOTk1VehLnCrsTmAuth : 420|9@0- (0.05,0) [-12.8|12.75] "s" EOCM,EOCM_HCP2,EOCM_HC_Superset,HDLM
 SG_ FCODPB1P_FVVOTk2VehLnCrsTmAuth : 427|9@0- (0.05,0) [-12.8|12.75] "s" EOCM,EOCM_HCP2,EOCM_HC_Superset,HDLM
 SG_ FCODPB1P_FVVOTk3VehLnCrsTmAuth : 434|9@0- (0.05,0) [-12.8|12.75] "s" EOCM,EOCM_HCP2,EOCM_HC_Superset,HDLM
 SG_ FCODPB1P_FVVOTk4VehLnCrsTmAuth : 441|9@0- (0.05,0) [-12.8|12.75] "s" EOCM,EOCM_HCP2,EOCM_HC_Superset,HDLM
 SG_ FCODPB1P_FVVOTk5VehLnCrsTmAuth : 448|9@0- (0.05,0) [-12.8|12.75] "s" EOCM,EOCM_HCP2,EOCM_HC_Superset,HDLM
 SG_ FCODPB1P_FVVOTk6VehLnCrsTmAuth : 471|9@0- (0.05,0) [-12.8|12.75] "s" EOCM,EOCM_HCP2,EOCM_HC_Superset,HDLM
 SG_ FCODPB1P_FVVOTk7VehLnCrsTmAuth : 478|9@0- (0.05,0) [-12.8|12.75] "s" EOCM,EOCM_HCP2,EOCM_HC_Superset,HDLM
 SG_ FCODPB1P_FVVOTk8VehLnCrsTmAuth : 485|9@0- (0.05,0) [-12.8|12.75] "s" EOCM,EOCM_HCP2,EOCM_HC_Superset,HDLM
 SG_ FCODPB1P_FVVOTk9VehLnCrsTmAuth : 492|9@0- (0.05,0) [-12.8|12.75] "s" EOCM,EOCM_HCP2,EOCM_HC_Superset,HDLM
 SG_ FrwdVsnPedtrnObjTk1DatIntegCkd : 497|2@0+ (1,0) [0|2] "" EOCM,EOCM_HCP2,EOCM_HC_Superset,HDLM
 SG_ FrwdVsnLnBdryTk1DatIntegCkd : 499|2@0+ (1,0) [0|2] "" EOCM,EOCM_HCP2,EOCM_HC_Superset,HDLM
 SG_ FCODPB1P_Filler : 509|6@0+ (1,0) [0|63] "" EOCM,EOCM_HCP2,EOCM_HC_Superset,HDLM
 SG_ FrwdVsnVehObjTk1DatIntegCkd : 511|2@0+ (1,0) [0|2] "" EOCM,EOCM_HCP2,EOCM_HC_Superset,HDLM

BO_ 240 FCODP_BrstGrp_Prtctd_Last_Frame_: 20 ACP2_MCU
 SG_ FCODPB15P_CnstrObj10LngDistAuth : 5|10@0+ (0.125,0) [0|127.875] "m" EOCM,EOCM_HCP2,EOCM_HC_Superset,HDLM
 SG_ FCODPB15P_BrstID : 7|2@0+ (1,0) [0|3] "" EOCM,EOCM_HCP2,EOCM_HC_Superset,HDLM
 SG_ FCODPB15P_CnstrObj11LngDistAuth : 11|10@0+ (0.125,0) [0|127.875] "m" EOCM,EOCM_HCP2,EOCM_HC_Superset,HDLM
 SG_ FCODPB15P_CnstrObj12LngDistAuth : 17|10@0+ (0.125,0) [0|127.875] "m" EOCM,EOCM_HCP2,EOCM_HC_Superset,HDLM
 SG_ FCODPB15P_CnstrObj13LngDistAuth : 39|10@0+ (0.125,0) [0|127.875] "m" EOCM,EOCM_HCP2,EOCM_HC_Superset,HDLM
 SG_ FCODPB15P_CnstrObj14LngDistAuth : 45|10@0+ (0.125,0) [0|127.875] "m" EOCM,EOCM_HCP2,EOCM_HC_Superset,HDLM
 SG_ FCODPB15P_CnstrObj15LngDistAuth : 51|10@0+ (0.125,0) [0|127.875] "m" EOCM,EOCM_HCP2,EOCM_HC_Superset,HDLM
 SG_ FCODPB15P_CnstrObj1LngDistAuth : 57|10@0+ (0.125,0) [0|127.875] "m" EOCM,EOCM_HCP2,EOCM_HC_Superset,HDLM
 SG_ FCODPB15P_CnstrObj2LngDistAuth : 79|10@0+ (0.125,0) [0|127.875] "m" EOCM,EOCM_HCP2,EOCM_HC_Superset,HDLM
 SG_ FCODPB15P_CnstrObj3LngDistAuth : 85|10@0+ (0.125,0) [0|127.875] "m" EOCM,EOCM_HCP2,EOCM_HC_Superset,HDLM
 SG_ FCODPB15P_CnstrObj4LngDistAuth : 91|10@0+ (0.125,0) [0|127.875] "m" EOCM,EOCM_HCP2,EOCM_HC_Superset,HDLM
 SG_ FCODPB15P_CnstrObj5LngDistAuth : 97|10@0+ (0.125,0) [0|127.875] "m" EOCM,EOCM_HCP2,EOCM_HC_Superset,HDLM
 SG_ FCODPB15P_CnstrObj6LngDistAuth : 119|10@0+ (0.125,0) [0|127.875] "m" EOCM,EOCM_HCP2,EOCM_HC_Superset,HDLM
 SG_ FCODPB15P_CnstrObj7LngDistAuth : 125|10@0+ (0.125,0) [0|127.875] "m" EOCM,EOCM_HCP2,EOCM_HC_Superset,HDLM
 SG_ FCODPB15P_CnstrObj8LngDistAuth : 131|10@0+ (0.125,0) [0|127.875] "m" EOCM,EOCM_HCP2,EOCM_HC_Superset,HDLM
 SG_ FCODPB15P_CnstrObj9LngDistAuth : 137|10@0+ (0.125,0) [0|127.875] "m" EOCM,EOCM_HCP2,EOCM_HC_Superset,HDLM
 SG_ FCODPB15P_Filler : 159|8@0+ (1,0) [0|255] "" EOCM,EOCM_HCP2,EOCM_HC_Superset,HDLM

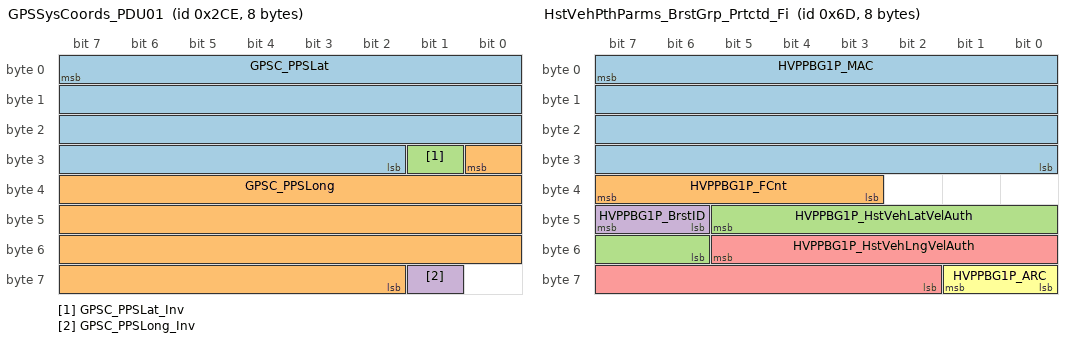
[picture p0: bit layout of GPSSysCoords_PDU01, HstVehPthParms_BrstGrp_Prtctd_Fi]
BO_ 718 GPSSysCoords_PDU01: 8 CGM
 SG_ GPSC_PPSLat : 7|30@0- (1,0) [-5.36871e+008|5.36871e+008] "ms arc" FCM_LC
 SG_ GPSC_PPSLong : 24|31@0- (1,0) [-1.07374e+009|1.07374e+009] "ms arc" FCM_LC
 SG_ GPSC_PPSLat_Inv : 25|1@0+ (1,0) [0|1] "" FCM_LC
 SG_ GPSC_PPSLong_Inv : 57|1@0+ (1,0) [0|1] "" FCM_LC

BO_ 2147745810 HDLM_CAN8_ClscCANHrtBtActv_PDU: 1 HDLM
 SG_ HDLM_CAN8_ClscCANHrtBtActv : 7|1@0+ (1,0) [0|1] "" CGM

BO_ 914 HstVehPathParms_PCSM_PDU: 8 CGM
 SG_ HstVehPathParms_PCSM : 0|64@1+ (1,0) [0|1.84467e+019] "" FCM_LC,HDLM,LRR,SRR_LF,SRR_LR_CR,SRR_RF,SRR_RR,SRR_SLR,SRR_SRR,UPM

BO_ 87 HstVehPathParms_Prtctd_PDU: 32 CGM
 SG_ HVPPP_MAC : 7|32@0+ (1,0) [0|4.29497e+009] "" FCM_LC,HDLM,LRR,SRR_LF,SRR_LR_CR,SRR_RF,SRR_RR,SRR_SLR,SRR_SRR,UPM
 SG_ HVPPP_FCnt : 39|5@0+ (1,0) [0|31] "" FCM_LC,HDLM,LRR,SRR_LF,SRR_LR_CR,SRR_RF,SRR_RR,SRR_SLR,SRR_SRR,UPM
 SG_ HVPPP_HstVehLatVelAuth : 46|8@0+ (0.05,-6.4) [-6.4|6.35] "m/s" FCM_LC,HDLM,LRR,SRR_LF,SRR_LR_CR,SRR_RF,SRR_RR,SRR_SLR,SRR_SRR,UPM
 SG_ HVPPP_FrwdVsnModeCmdAuth : 47|1@0+ (1,0) [0|1] "" FCM_LC,HDLM,LRR,SRR_LF,SRR_LR_CR,SRR_RF,SRR_RR,SRR_SLR,SRR_SRR,UPM
 SG_ HVPPP_HstVehLngVelAuth : 53|12@0+ (0.0625,-128) [-128|127.938] "m/s" FCM_LC,HDLM,LRR,SRR_LF,SRR_LR_CR,SRR_RF,SRR_RR,SRR_SLR,SRR_SRR,UPM
 SG_ HVPPP_HstVehLatVelAuth_Inv : 54|1@0+ (1,0) [0|1] "" FCM_LC,HDLM,LRR,SRR_LF,SRR_LR_CR,SRR_RF,SRR_RR,SRR_SLR,SRR_SRR,UPM
 SG_ HVPPP_HstVehPathCrvAuth : 56|16@0- (1e-05,0) [-0.32768|0.32767] "1/m" FCM_LC,HDLM,LRR,SRR_LF,SRR_LR_CR,SRR_RF,SRR_RR,SRR_SLR,SRR_SRR,UPM
 SG_ HVPPP_HstVehLngVelAuth_Inv : 57|1@0+ (1,0) [0|1] "" FCM_LC,HDLM,LRR,SRR_LF,SRR_LR_CR,SRR_RF,SRR_RR,SRR_SLR,SRR_SRR,UPM
 SG_ HVPPP_HstVehPathCrvDrvtAuth : 72|15@0+ (0.001,-16) [-16|16.767] "1/m-s" FCM_LC,HDLM,LRR,SRR_LF,SRR_LR_CR,SRR_RF,SRR_RR,SRR_SLR,SRR_SRR,UPM
 SG_ HVPPP_HstVehPathModeAuth : 89|2@0+ (1,0) [0|2] "" FCM_LC,HDLM,LRR,SRR_LF,SRR_LR_CR,SRR_RF,SRR_RR,SRR_SLR,SRR_SRR,UPM
 SG_ HVPPP_HstVehSdslAngAuth : 103|12@0+ (0.0625,-128) [-128|127.938] "deg/s" FCM_LC,HDLM,LRR,SRR_LF,SRR_LR_CR,SRR_RF,SRR_RR,SRR_SLR,SRR_SRR,UPM
 SG_ HVPPP_HstVehTrnCntrLatOfstAuth : 107|14@0+ (1,-8192) [-8192|8191] "m" FCM_LC,HDLM,LRR,SRR_LF,SRR_LR_CR,SRR_RF,SRR_RR,SRR_SLR,SRR_SRR,UPM
 SG_ HVPPP_HstVehTrnCntrLngOfstAuth : 125|8@0+ (0.1,-12.8) [-12.8|12.7] "m" FCM_LC,HDLM,LRR,SRR_LF,SRR_LR_CR,SRR_RF,SRR_RR,SRR_SLR,SRR_SRR,UPM
 SG_ HVPPP_HstVehVelAuth : 131|12@0+ (0.0625,-128) [-128|127.938] "m/s" FCM_LC,HDLM,LRR,SRR_LF,SRR_LR_CR,SRR_RF,SRR_RR,SRR_SLR,SRR_SRR,UPM
 SG_ HVPPP_HstVehTrvlDirAuth : 133|2@0+ (1,0) [0|3] "" FCM_LC,HDLM,LRR,SRR_LF,SRR_LR_CR,SRR_RF,SRR_RR,SRR_SLR,SRR_SRR,UPM
 SG_ HVPPP_HstVehYawRateAuth : 150|12@0+ (0.0625,-128) [-128|127.938] "deg/s" FCM_LC,HDLM,LRR,SRR_LF,SRR_LR_CR,SRR_RF,SRR_RR,SRR_SLR,SRR_SRR,UPM
 SG_ HVPPP_HstVehVelAuth_Inv : 151|1@0+ (1,0) [0|1] "" FCM_LC,HDLM,LRR,SRR_LF,SRR_LR_CR,SRR_RF,SRR_RR,SRR_SLR,SRR_SRR,UPM
 SG_ HVPPP_LngRngRadarModeCmdAuth : 153|2@0+ (1,0) [0|2] "" FCM_LC,HDLM,LRR,SRR_LF,SRR_LR_CR,SRR_RF,SRR_RR,SRR_SLR,SRR_SRR,UPM
 SG_ HVPPP_HstVehYawRateAuth_Inv : 154|1@0+ (1,0) [0|1] "" FCM_LC,HDLM,LRR,SRR_LF,SRR_LR_CR,SRR_RF,SRR_RR,SRR_SLR,SRR_SRR,UPM
 SG_ HVPPP_ObjSnsrTmSyncMstrClckAuth : 167|32@0+ (1,0) [0|4.29497e+009] "ms" FCM_LC,HDLM,LRR,SRR_LF,SRR_LR_CR,SRR_RF,SRR_RR,SRR_SLR,SRR_SRR,UPM
 SG_ HVPPP_ARC : 193|2@0+ (1,0) [0|3] "" FCM_LC,HDLM,LRR,SRR_LF,SRR_LR_CR,SRR_RF,SRR_RR,SRR_SLR,SRR_SRR,UPM
 SG_ HVPPP_ShrtRngRadarModeCmdAuth : 195|2@0+ (1,0) [0|2] "" FCM_LC,HDLM,LRR,SRR_LF,SRR_LR_CR,SRR_RF,SRR_RR,SRR_SLR,SRR_SRR,UPM
 SG_ HVPPP_ObjsRetndRrwdSnsrsAuth : 197|2@0+ (1,0) [0|2] "" FCM_LC,HDLM,LRR,SRR_LF,SRR_LR_CR,SRR_RF,SRR_RR,SRR_SLR,SRR_SRR,UPM
 SG_ HVPPP_ObjsRetndFrwdSnsrsAuth : 199|2@0+ (1,0) [0|2] "" FCM_LC,HDLM,LRR,SRR_LF,SRR_LR_CR,SRR_RF,SRR_RR,SRR_SLR,SRR_SRR,UPM
 SG_ HstVehRideHghtOfst : 201|9@0- (1,0) [-256|255] "mm" FCM_LC,HDLM,LRR,SRR_LF,SRR_LR_CR,SRR_RF,SRR_RR,SRR_SLR,SRR_SRR,UPM
 SG_ DrvrMonSysModeCmd : 203|2@0+ (1,0) [0|2] "" FCM_LC,HDLM,LRR,SRR_LF,SRR_LR_CR,SRR_RF,SRR_RR,SRR_SLR,SRR_SRR,UPM
 SG_ LnFllwgFtrStatAuth : 207|4@0+ (1,0) [0|10] "" FCM_LC,HDLM,LRR,SRR_LF,SRR_LR_CR,SRR_RF,SRR_RR,SRR_SLR,SRR_SRR,UPM
 SG_ HstVehRideHghtOfst_Inv : 208|1@0+ (1,0) [0|1] "" FCM_LC,HDLM,LRR,SRR_LF,SRR_LR_CR,SRR_RF,SRR_RR,SRR_SLR,SRR_SRR,UPM
 SG_ HstVehFrtRdWhlAng : 222|10@0- (0.004363,0) [-2.23386|2.22949] "Rad" FCM_LC,HDLM,LRR,SRR_LF,SRR_LR_CR,SRR_RF,SRR_RR,SRR_SLR,SRR_SRR,UPM
 SG_ HstVehRideHghtOfstSts : 223|1@0+ (1,0) [0|1] "" FCM_LC,HDLM,LRR,SRR_LF,SRR_LR_CR,SRR_RF,SRR_RR,SRR_SLR,SRR_SRR,UPM
 SG_ HVPPP_Filler : 225|6@0+ (1,0) [0|63] "" FCM_LC,HDLM,LRR,SRR_LF,SRR_LR_CR,SRR_RF,SRR_RR,SRR_SLR,SRR_SRR,UPM
 SG_ GeofncngRstrctdZnStsGtd : 227|2@0+ (1,0) [0|2] "" FCM_LC,HDLM,LRR,SRR_LF,SRR_LR_CR,SRR_RF,SRR_RR,SRR_SLR,SRR_SRR,UPM
 SG_ HstVehFrtRdWhlAng_Inv : 228|1@0+ (1,0) [0|1] "" FCM_LC,HDLM,LRR,SRR_LF,SRR_LR_CR,SRR_RF,SRR_RR,SRR_SLR,SRR_SRR,UPM
 SG_ HVPPP_FillerExtnd : 235|20@0+ (1,0) [0|1.04858e+006] "" FCM_LC,HDLM,LRR,SRR_LF,SRR_LR_CR,SRR_RF,SRR_RR,SRR_SLR,SRR_SRR,UPM

BO_ 687 HstVehPthParms_BrstGrp_PCSM_PDU: 8 ACP2_MCU
 SG_ HstVehPthParms_BrstGrp1_PCSM : 0|64@1+ (1,0) [0|1.84467e+019] "" Vector__XXX

BO_ 109 HstVehPthParms_BrstGrp_Prtctd_Fi: 8 ACP2_MCU
 SG_ HVPPBG1P_MAC : 7|32@0+ (1,0) [0|4.29497e+009] "" Vector__XXX
 SG_ HVPPBG1P_FCnt : 39|5@0+ (1,0) [0|31] "" Vector__XXX
 SG_ HVPPBG1P_HstVehLatVelAuth : 45|8@0- (0.05,0) [-6.4|6.35] "m/s" Vector__XXX
 SG_ HVPPBG1P_BrstID : 47|2@0+ (1,0) [0|3] "" Vector__XXX
 SG_ HVPPBG1P_HstVehLngVelAuth : 53|12@0- (0.0625,0) [-128|127.938] "m/s" Vector__XXX
 SG_ HVPPBG1P_ARC : 57|2@0+ (1,0) [0|3] "" Vector__XXX

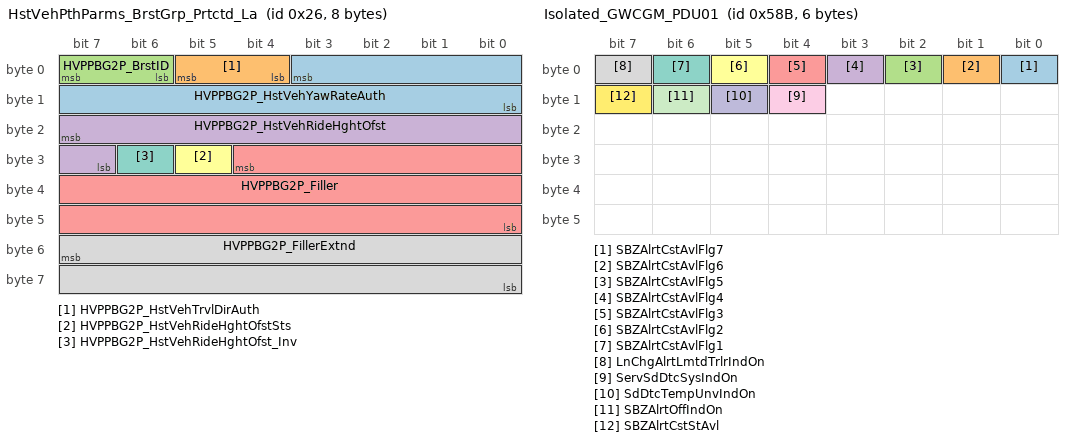
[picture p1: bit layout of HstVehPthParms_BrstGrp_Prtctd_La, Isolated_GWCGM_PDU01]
BO_ 38 HstVehPthParms_BrstGrp_Prtctd_La: 8 ACP2_MCU
 SG_ HVPPBG2P_HstVehYawRateAuth : 3|12@0- (0.0625,0) [-128|127.938] "deg/s" Vector__XXX
 SG_ HVPPBG2P_HstVehTrvlDirAuth : 5|2@0+ (1,0) [0|3] "" Vector__XXX
 SG_ HVPPBG2P_BrstID : 7|2@0+ (1,0) [0|3] "" Vector__XXX
 SG_ HVPPBG2P_HstVehRideHghtOfst : 23|9@0- (1,0) [-256|255] "mm" Vector__XXX
 SG_ HVPPBG2P_Filler : 28|21@0+ (1,0) [0|2.09715e+006] "" Vector__XXX
 SG_ HVPPBG2P_HstVehRideHghtOfstSts : 29|1@0+ (1,0) [0|1] "" Vector__XXX
 SG_ HVPPBG2P_HstVehRideHghtOfst_Inv : 30|1@0+ (1,0) [0|1] "" Vector__XXX
 SG_ HVPPBG2P_FillerExtnd : 55|16@0+ (1,0) [0|65535] "" Vector__XXX

BO_ 1419 Isolated_GWCGM_PDU01: 6 SRR_SLR
 SG_ SBZAlrtCstAvlFlg7 : 0|1@0+ (1,0) [0|1] "" Vector__XXX
 SG_ SBZAlrtCstAvlFlg6 : 1|1@0+ (1,0) [0|1] "" Vector__XXX
 SG_ SBZAlrtCstAvlFlg5 : 2|1@0+ (1,0) [0|1] "" Vector__XXX
 SG_ SBZAlrtCstAvlFlg4 : 3|1@0+ (1,0) [0|1] "" Vector__XXX
 SG_ SBZAlrtCstAvlFlg3 : 4|1@0+ (1,0) [0|1] "" Vector__XXX
 SG_ SBZAlrtCstAvlFlg2 : 5|1@0+ (1,0) [0|1] "" Vector__XXX
 SG_ SBZAlrtCstAvlFlg1 : 6|1@0+ (1,0) [0|1] "" Vector__XXX
 SG_ LnChgAlrtLmtdTrlrIndOn : 7|1@0+ (1,0) [0|1] "" Vector__XXX
 SG_ ServSdDtcSysIndOn : 12|1@0+ (1,0) [0|1] "" Vector__XXX
 SG_ SdDtcTempUnvIndOn : 13|1@0+ (1,0) [0|1] "" Vector__XXX
 SG_ SBZAlrtOffIndOn : 14|1@0+ (1,0) [0|1] "" Vector__XXX
 SG_ SBZAlrtCstStAvl : 15|1@0+ (1,0) [0|1] "" Vector__XXX

BO_ 1408 Isolated_GWCGM_PDU04: 6 ACP2_MCU
 SG_ TrffcLgtAsstWrnChmEvntStat : 1|2@0+ (1,0) [0|3] "" Vector__XXX
 SG_ TrffcLgtAsstCstCurrSetVal : 4|3@0+ (1,0) [0|7] "" Vector__XXX
 SG_ GlrFrHgBmRspTypCstCurSetVal : 7|3@0+ (1,0) [0|7] "" Vector__XXX
 SG_ GlrFrHgBmRspTypCstAvlFlg7 : 8|1@0+ (1,0) [0|1] "" Vector__XXX
 SG_ GlrFrHgBmRspTypCstAvlFlg6 : 9|1@0+ (1,0) [0|1] "" Vector__XXX
 SG_ GlrFrHgBmRspTypCstAvlFlg5 : 10|1@0+ (1,0) [0|1] "" Vector__XXX
 SG_ GlrFrHgBmRspTypCstAvlFlg4 : 11|1@0+ (1,0) [0|1] "" Vector__XXX
 SG_ GlrFrHgBmRspTypCstAvlFlg3 : 12|1@0+ (1,0) [0|1] "" Vector__XXX
 SG_ GlrFrHgBmRspTypCstAvlFlg2 : 13|1@0+ (1,0) [0|1] "" Vector__XXX
 SG_ GlrFrHgBmRspTypCstAvlFlg1 : 14|1@0+ (1,0) [0|1] "" Vector__XXX
 SG_ AutoHgBmCtrlIO : 15|1@0+ (1,0) [0|1] "" Vector__XXX
 SG_ TrffcLgtAsstCstAvlFlg7 : 16|1@0+ (1,0) [0|1] "" Vector__XXX
 SG_ TrffcLgtAsstCstAvlFlg6 : 17|1@0+ (1,0) [0|1] "" Vector__XXX
 SG_ TrffcLgtAsstCstAvlFlg5 : 18|1@0+ (1,0) [0|1] "" Vector__XXX
 SG_ TrffcLgtAsstCstAvlFlg4 : 19|1@0+ (1,0) [0|1] "" Vector__XXX
 SG_ TrffcLgtAsstCstAvlFlg3 : 20|1@0+ (1,0) [0|1] "" Vector__XXX
 SG_ TrffcLgtAsstCstAvlFlg2 : 21|1@0+ (1,0) [0|1] "" Vector__XXX
 SG_ TrffcLgtAsstCstAvlFlg1 : 22|1@0+ (1,0) [0|1] "" Vector__XXX
 SG_ GlrFrHgBmRspTypCstStAvl : 23|1@0+ (1,0) [0|1] "" Vector__XXX
 SG_ TrffcLgtAsstCstSetAval : 31|1@0+ (1,0) [0|1] "" Vector__XXX

BO_ 1423 Isolated_GWCGM_PDU05: 8 ACP2_MCU
 SG_ TSMCurrSpdLim : 7|8@0+ (1,0) [0|255] "" EOCM,EOCM_HCP2,EOCM_HC_Superset
 SG_ TSMEurDispSgn2Mn : 9|6@0+ (1,0) [0|54] "" Vector__XXX
 SG_ TSMEurDispSgn1Mn : 15|6@0+ (1,0) [0|54] "" Vector__XXX
 SG_ TSMUSAndCADispSgn1Mn : 19|6@0+ (1,0) [0|45] "" Vector__XXX
 SG_ TSMUSAndCADispSgn2Mn : 29|6@0+ (1,0) [0|45] "" Vector__XXX
 SG_ TSMEurDispSgn2AddOn : 35|4@0+ (1,0) [0|15] "" Vector__XXX
 SG_ TSMEurDispSgn1AddOn : 39|4@0+ (1,0) [0|15] "" Vector__XXX
 SG_ FrwdVsFlDtcnIndOn : 40|1@0+ (1,0) [0|1] "" Vector__XXX
 SG_ FrwdVsAdvWthrIndOn : 41|1@0+ (1,0) [0|1] "" Vector__XXX
 SG_ TSMUSAndCADispSgn2AddOn : 44|3@0+ (1,0) [0|5] "" Vector__XXX
 SG_ TSMUSAndCADispSgn1AddOn : 47|3@0+ (1,0) [0|5] "" Vector__XXX
 SG_ TrffcLgtAsstHUDWrnIndOn : 48|1@0+ (1,0) [0|1] "" Vector__XXX
 SG_ TrffcLgtAsstClstrWrnIndOn : 49|1@0+ (1,0) [0|1] "" Vector__XXX
 SG_ TSMSgnNtfnIndOn : 50|1@0+ (1,0) [0|1] "" Vector__XXX
 SG_ TSMPDAMnSgnFlshgReq : 51|1@0+ (1,0) [0|1] "" Vector__XXX
 SG_ TSMNoEntryIndOn : 52|1@0+ (1,0) [0|1] "" Vector__XXX
 SG_ TSMIcePsblIndOn : 53|1@0+ (1,0) [0|1] "" Vector__XXX
 SG_ TSMAddTrfSgnAvIndOn : 54|1@0+ (1,0) [0|1] "" Vector__XXX
 SG_ FrwdVsFllBlckIndOn : 55|1@0+ (1,0) [0|1] "" Vector__XXX
 SG_ TrffcLgtAsstRLADWrnIndOn : 63|1@0+ (1,0) [0|1] "" Vector__XXX

BO_ 1420 Isolated_GWCGM_PDU06: 6 SRR_SLR
 SG_ SBZALCAVisIndStatLt : 7|2@0+ (1,0) [0|2] "" Vector__XXX

BO_ 1421 Isolated_GWCGM_PDU07: 6 SRR_SRR
 SG_ SBZALCAVisIndStatRt : 7|2@0+ (1,0) [0|2] "" Vector__XXX

BO_ 1409 Isolated_GWCGM_PDU09: 6 ACP2_MCU
 SG_ TLAHSR_HptcStRqstSeqNmb : 1|2@0+ (1,0) [0|3] "counts" Vector__XXX
 SG_ TLAHSR_HptcStRqstPls : 7|6@0+ (1,0) [0|63] "pulses" Vector__XXX

BO_ 1418 Isolated_GWCGM_PDU10: 6 ACP2_MCU
 SG_ AutoHgBmActReq : 7|1@0+ (1,0) [0|1] "" Vector__XXX

BO_ 681 Isolated_GWCGM_PDU11: 4 CGM
 SG_ LtLnChgThrtAprchSpd : 7|8@0- (1,0) [-128|127] "Kph" ACP2_MCU,FCM_LC
 SG_ LtFstAprchgVehObjDtd : 15|1@0+ (1,0) [0|1] "" ACP2_MCU,EOCM,EOCM_HC_Superset,FCM_LC,SRR_SLR

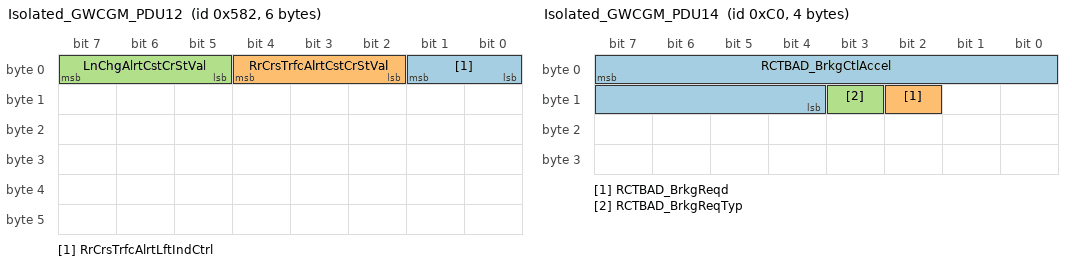
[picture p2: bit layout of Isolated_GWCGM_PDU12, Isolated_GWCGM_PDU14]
BO_ 1410 Isolated_GWCGM_PDU12: 6 SRR_SLR
 SG_ RrCrsTrfcAlrtLftIndCtrl : 1|2@0+ (1,0) [0|2] "" Vector__XXX
 SG_ RrCrsTrfcAlrtCstCrStVal : 4|3@0+ (1,0) [0|7] "" SRR_SRR
 SG_ LnChgAlrtCstCrStVal : 7|3@0+ (1,0) [0|7] "" SRR_LR_CR,SRR_RR,SRR_SRR

BO_ 1428 Isolated_GWCGM_PDU13: 6 CGM
 SG_ LtSdVehObjDtd : 5|1@0+ (1,0) [0|1] "" FCM_LC
 SG_ SBZALCAOvrllOplSts : 7|2@0+ (1,0) [0|2] "" SRR_SRR

BO_ 192 Isolated_GWCGM_PDU14: 4 SRR_SLR
 SG_ RCTBAD_BrkgCtlAccel : 7|12@0- (0.01,0) [-20.48|20.47] "m/s2" CGM
 SG_ RCTBAD_BrkgReqd : 10|1@0+ (1,0) [0|1] "" CGM
 SG_ RCTBAD_BrkgReqTyp : 11|1@0+ (1,0) [0|1] "" CGM

BO_ 1411 Isolated_GWCGM_PDU15: 8 SRR_SLR
 SG_ SBZAlrtCstCrStVal : 1|3@0+ (1,0) [0|7] "" CGM,SRR_LR_CR,SRR_RR,SRR_SRR
 SG_ ByclDtnCstCurrSetVal : 4|3@0+ (1,0) [0|2] "" CGM,SRR_SRR
 SG_ ByclDtnArbdIndStat : 7|3@0+ (1,0) [0|7] "" CGM
 SG_ ByclDtnCstAvlFlg1 : 8|1@0+ (1,0) [0|1] "" CGM
 SG_ RrCrsTrfcAlrtLtSdChmEvntStat : 10|2@0+ (1,0) [0|2] "" CGM
 SG_ ByclDtnArbdLvl2ChmEvntStat : 12|2@0+ (1,0) [0|2] "" CGM
 SG_ ByclDtnArbdLvl1ChmEvntStat : 14|2@0+ (1,0) [0|2] "" CGM
 SG_ LnChgAlrtCstAvlFlg1 : 16|1@0+ (1,0) [0|1] "" CGM
 SG_ ByclDtnCstSetAval : 17|1@0+ (1,0) [0|1] "" CGM
 SG_ ByclDtnCstAvlFlg7 : 18|1@0+ (1,0) [0|1] "" CGM
 SG_ ByclDtnCstAvlFlg6 : 19|1@0+ (1,0) [0|1] "" CGM
 SG_ ByclDtnCstAvlFlg5 : 20|1@0+ (1,0) [0|1] "" CGM
 SG_ ByclDtnCstAvlFlg4 : 21|1@0+ (1,0) [0|1] "" CGM
 SG_ ByclDtnCstAvlFlg3 : 22|1@0+ (1,0) [0|1] "" CGM
 SG_ ByclDtnCstAvlFlg2 : 23|1@0+ (1,0) [0|1] "" CGM
 SG_ LnChgAlrtSysOffIndOn : 24|1@0+ (1,0) [0|1] "" CGM
 SG_ LnChgAlrtCstStAvl : 25|1@0+ (1,0) [0|1] "" CGM
 SG_ LnChgAlrtCstAvlFlg7 : 26|1@0+ (1,0) [0|1] "" CGM
 SG_ LnChgAlrtCstAvlFlg6 : 27|1@0+ (1,0) [0|1] "" CGM
 SG_ LnChgAlrtCstAvlFlg5 : 28|1@0+ (1,0) [0|1] "" CGM
 SG_ LnChgAlrtCstAvlFlg4 : 29|1@0+ (1,0) [0|1] "" CGM
 SG_ LnChgAlrtCstAvlFlg3 : 30|1@0+ (1,0) [0|1] "" CGM
 SG_ LnChgAlrtCstAvlFlg2 : 31|1@0+ (1,0) [0|1] "" CGM
 SG_ RrCrsTrfcAlrtCstStAvl : 32|1@0+ (1,0) [0|1] "" CGM
 SG_ RrCrsTrfcAlrtCstAvlFlg7 : 33|1@0+ (1,0) [0|1] "" CGM
 SG_ RrCrsTrfcAlrtCstAvlFlg6 : 34|1@0+ (1,0) [0|1] "" CGM
 SG_ RrCrsTrfcAlrtCstAvlFlg5 : 35|1@0+ (1,0) [0|1] "" CGM
 SG_ RrCrsTrfcAlrtCstAvlFlg4 : 36|1@0+ (1,0) [0|1] "" CGM
 SG_ RrCrsTrfcAlrtCstAvlFlg3 : 37|1@0+ (1,0) [0|1] "" CGM
 SG_ RrCrsTrfcAlrtCstAvlFlg2 : 38|1@0+ (1,0) [0|1] "" CGM
 SG_ RrCrsTrfcAlrtCstAvlFlg1 : 39|1@0+ (1,0) [0|1] "" CGM
 SG_ RrCrsTrfcBrkgAutoBrkgRelIndOn : 45|1@0+ (1,0) [0|1] "" CGM
 SG_ RrCrsTrfcAutoBrkgOffIndOn : 46|1@0+ (1,0) [0|1] "" CGM
 SG_ RrCrsTrfcAlrtOffIndOn : 47|1@0+ (1,0) [0|1] "" CGM

BO_ 719 Isolated_GWCGM_PDU16: 4 CGM
 SG_ RtLnChgThrtAprchSpd : 7|8@0- (1,0) [-128|127] "Kph" ACP2_MCU,FCM_LC
 SG_ RtFstAprchgVehObjDtd : 15|1@0+ (1,0) [0|1] "" ACP2_MCU,EOCM,EOCM_HC_Superset,FCM_LC,SRR_SRR

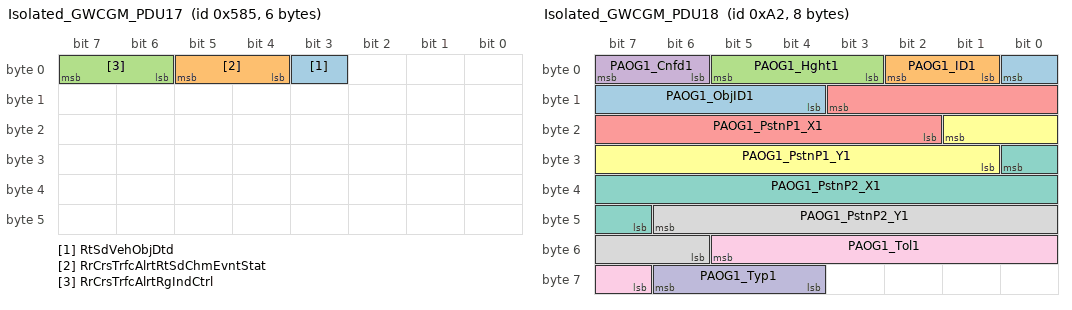
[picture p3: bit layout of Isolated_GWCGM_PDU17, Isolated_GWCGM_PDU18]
BO_ 1413 Isolated_GWCGM_PDU17: 6 CGM
 SG_ RtSdVehObjDtd : 3|1@0+ (1,0) [0|1] "" FCM_LC
 SG_ RrCrsTrfcAlrtRtSdChmEvntStat : 5|2@0+ (1,0) [0|2] "" Vector__XXX
 SG_ RrCrsTrfcAlrtRgIndCtrl : 7|2@0+ (1,0) [0|2] "" Vector__XXX

BO_ 162 Isolated_GWCGM_PDU18: 8 CGM
 SG_ PAOG1_ObjID1 : 0|5@0+ (1,0) [0|31] "" ACP2_MCU
 SG_ PAOG1_ID1 : 2|2@0+ (1,0) [0|3] "" ACP2_MCU
 SG_ PAOG1_Hght1 : 5|3@0+ (1,0) [0|3] "" ACP2_MCU
 SG_ PAOG1_Cnfd1 : 7|2@0+ (1,0) [0|3] "" ACP2_MCU
 SG_ PAOG1_PstnP1_X1 : 11|10@0+ (1,-1023) [-1023|0] "cm" ACP2_MCU
 SG_ PAOG1_PstnP1_Y1 : 17|9@0- (1,0) [-256|255] "cm" ACP2_MCU
 SG_ PAOG1_PstnP2_X1 : 24|10@0+ (1,-1023) [-1023|0] "cm" ACP2_MCU
 SG_ PAOG1_PstnP2_Y1 : 46|9@0- (1,0) [-256|255] "cm" ACP2_MCU
 SG_ PAOG1_Tol1 : 53|7@0+ (1,0) [0|127] "cm" ACP2_MCU
 SG_ PAOG1_Typ1 : 62|3@0+ (1,0) [0|6] "" ACP2_MCU

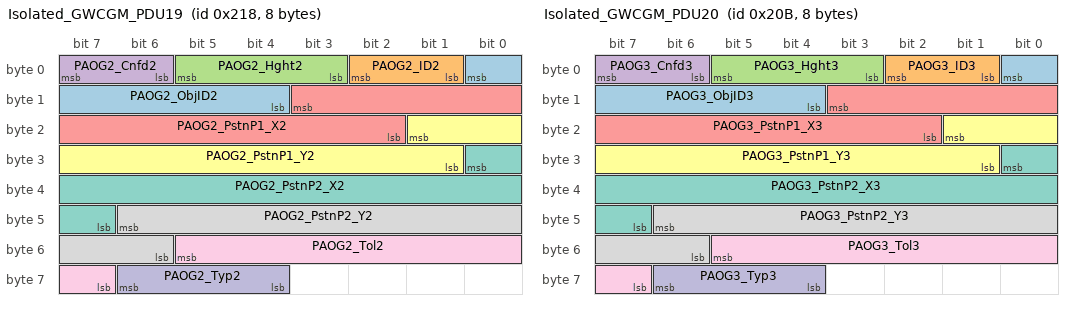
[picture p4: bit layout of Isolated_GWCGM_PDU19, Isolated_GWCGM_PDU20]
BO_ 536 Isolated_GWCGM_PDU19: 8 CGM
 SG_ PAOG2_ObjID2 : 0|5@0+ (1,0) [0|31] "" ACP2_MCU
 SG_ PAOG2_ID2 : 2|2@0+ (1,0) [0|3] "" ACP2_MCU
 SG_ PAOG2_Hght2 : 5|3@0+ (1,0) [0|3] "" ACP2_MCU
 SG_ PAOG2_Cnfd2 : 7|2@0+ (1,0) [0|3] "" ACP2_MCU
 SG_ PAOG2_PstnP1_X2 : 11|10@0+ (1,-1023) [-1023|0] "cm" ACP2_MCU
 SG_ PAOG2_PstnP1_Y2 : 17|9@0- (1,0) [-256|255] "cm" ACP2_MCU
 SG_ PAOG2_PstnP2_X2 : 24|10@0+ (1,-1023) [-1023|0] "cm" ACP2_MCU
 SG_ PAOG2_PstnP2_Y2 : 46|9@0- (1,0) [-256|255] "cm" ACP2_MCU
 SG_ PAOG2_Tol2 : 53|7@0+ (1,0) [0|127] "cm" ACP2_MCU
 SG_ PAOG2_Typ2 : 62|3@0+ (1,0) [0|6] "" ACP2_MCU

BO_ 523 Isolated_GWCGM_PDU20: 8 CGM
 SG_ PAOG3_ObjID3 : 0|5@0+ (1,0) [0|31] "" ACP2_MCU
 SG_ PAOG3_ID3 : 2|2@0+ (1,0) [0|3] "" ACP2_MCU
 SG_ PAOG3_Hght3 : 5|3@0+ (1,0) [0|3] "" ACP2_MCU
 SG_ PAOG3_Cnfd3 : 7|2@0+ (1,0) [0|3] "" ACP2_MCU
 SG_ PAOG3_PstnP1_X3 : 11|10@0+ (1,-1023) [-1023|0] "cm" ACP2_MCU
 SG_ PAOG3_PstnP1_Y3 : 17|9@0- (1,0) [-256|255] "cm" ACP2_MCU
 SG_ PAOG3_PstnP2_X3 : 24|10@0+ (1,-1023) [-1023|0] "cm" ACP2_MCU
 SG_ PAOG3_PstnP2_Y3 : 46|9@0- (1,0) [-256|255] "cm" ACP2_MCU
 SG_ PAOG3_Tol3 : 53|7@0+ (1,0) [0|127] "cm" ACP2_MCU
 SG_ PAOG3_Typ3 : 62|3@0+ (1,0) [0|6] "" ACP2_MCU

BO_ 657 LRRODP_BrstGrp_PCSM_PDU: 8 LRR
 SG_ LRRODP_BrstGrp1_PCSM : 0|64@1+ (1,0) [0|1.84467e+019] "" ACP2_MCU,EOCM,EOCM_HCP2,EOCM_HC_Superset

BO_ 241 LRRODP_BrstGrp_Prtctd_Consecutiv: 64 LRR
 SG_ LRRODPB2P_POTk2IDAuth : 0|7@0+ (1,0) [0|127] "" ACP2_MCU,EOCM,EOCM_HCP2,EOCM_HC_Superset
 SG_ LRRODPB2P_POTk2DynPrpAuth : 3|3@0+ (1,0) [0|4] "" ACP2_MCU,EOCM,EOCM_HCP2,EOCM_HC_Superset
 SG_ LRRODPB2P_POTk2CnfdStsAuth : 5|2@0+ (1,0) [0|3] "" ACP2_MCU,EOCM,EOCM_HCP2,EOCM_HC_Superset
 SG_ LRRODPB2P_BrstID : 7|2@0+ (1,0) [0|3] "" ACP2_MCU,EOCM,EOCM_HCP2,EOCM_HC_Superset
 SG_ LRRODPB2P_POTk2InPthPotAuth : 9|6@0+ (2,0) [0|126] "%" ACP2_MCU,EOCM,EOCM_HCP2,EOCM_HC_Superset
 SG_ LRRODPB2P_POTk2PoILAAuth : 17|9@0- (0.125,0) [-32|31.875] "m/s^2" ACP2_MCU,EOCM,EOCM_HCP2,EOCM_HC_Superset
 SG_ LRRODPB2P_POTk2MStsAuth : 19|2@0+ (1,0) [0|3] "" ACP2_MCU,EOCM,EOCM_HCP2,EOCM_HC_Superset
 SG_ LRRODPB2P_POTk2PoILgAAuth : 24|9@0- (0.125,0) [-32|31.875] "m/s^2" ACP2_MCU,EOCM,EOCM_HCP2,EOCM_HC_Superset
 SG_ LRRODPB2P_POTk2PoILgPsAuth : 47|11@0+ (0.125,0) [0|255.875] "m" ACP2_MCU,EOCM,EOCM_HCP2,EOCM_HC_Superset
 SG_ LRRODPB2P_POTk2PoILgVAuth : 52|10@0- (0.125,0) [-64|63.875] "m/s" ACP2_MCU,EOCM,EOCM_HCP2,EOCM_HC_Superset
 SG_ LRRODPB2P_POTk2PoILPsAuth : 58|10@0- (0.125,0) [-64|63.875] "m" ACP2_MCU,EOCM,EOCM_HCP2,EOCM_HC_Superset
 SG_ LRRODPB2P_POTk2PoILVAuth : 64|9@0- (0.125,0) [-32|31.875] "m/s" ACP2_MCU,EOCM,EOCM_HCP2,EOCM_HC_Superset
 SG_ LRRODPB2P_VOTk3CICOPotAuth : 83|6@0+ (2,0) [0|126] "%" ACP2_MCU,EOCM,EOCM_HCP2,EOCM_HC_Superset
 SG_ LRRODPB2P_POTk2TypCnfdAuth : 85|2@0+ (1,0) [0|3] "" ACP2_MCU,EOCM,EOCM_HCP2,EOCM_HC_Superset
 SG_ LRRODPB2P_POTk2TypAuth : 87|2@0+ (1,0) [0|2] "" ACP2_MCU,EOCM,EOCM_HCP2,EOCM_HC_Superset
 SG_ LRRODPB2P_VOTk3DynPrpStsAuth : 88|1@0+ (1,0) [0|1] "" ACP2_MCU,EOCM,EOCM_HCP2,EOCM_HC_Superset
 SG_ LRRODPB2P_VOTk3DynPrpAuth : 91|3@0+ (1,0) [0|4] "" ACP2_MCU,EOCM,EOCM_HCP2,EOCM_HC_Superset
 SG_ LRRODPB2P_VOTk3CnfdStsAuth : 93|2@0+ (1,0) [0|3] "" ACP2_MCU,EOCM,EOCM_HCP2,EOCM_HC_Superset
 SG_ LRRODPB2P_VOTk3MStsAuth : 96|2@0+ (1,0) [0|3] "" ACP2_MCU,EOCM,EOCM_HCP2,EOCM_HC_Superset
 SG_ LRRODPB2P_VOTk3IDAuth : 103|7@0+ (1,0) [0|127] "" ACP2_MCU,EOCM,EOCM_HCP2,EOCM_HC_Superset
 SG_ LRRODPB2P_VOTk3PoILAAuth : 110|9@0- (0.125,0) [-32|31.875] "m/s^2" ACP2_MCU,EOCM,EOCM_HCP2,EOCM_HC_Superset
 SG_ LRRODPB2P_VOTk3PoILgAAuth : 117|9@0- (0.125,0) [-32|31.875] "m/s^2" ACP2_MCU,EOCM,EOCM_HCP2,EOCM_HC_Superset
 SG_ LRRODPB2P_VOTk3PoILgPsAuth : 124|11@0+ (0.125,0) [0|255.875] "m" ACP2_MCU,EOCM,EOCM_HCP2,EOCM_HC_Superset
 SG_ LRRODPB2P_VOTk3PoILgPsCAuth : 129|15@0+ (0.01,0) [0|327.67] "m^2" ACP2_MCU,EOCM,EOCM_HCP2,EOCM_HC_Superset
 SG_ LRRODPB2P_VOTk3PoILgthAuth : 146|11@0+ (0.125,0) [0|255.875] "m" ACP2_MCU,EOCM,EOCM_HCP2,EOCM_HC_Superset
 SG_ LRRODPB2P_VOTk3PoILgVAuth : 167|11@0- (0.125,0) [-128|127.875] "m/s" ACP2_MCU,EOCM,EOCM_HCP2,EOCM_HC_Superset
 SG_ LRRODPB2P_VOTk3PoILgVCAuth : 172|10@0+ (0.125,0) [0|127.875] "(m/s)^2" ACP2_MCU,EOCM,EOCM_HCP2,EOCM_HC_Superset
 SG_ LRRODPB2P_VOTk3PoILPsAuth : 178|10@0- (0.125,0) [-64|63.875] "m" ACP2_MCU,EOCM,EOCM_HCP2,EOCM_HC_Superset
 SG_ LRRODPB2P_VOTk3PoILPsCAuth : 184|14@0+ (0.01,0) [0|163.83] "m^2" ACP2_MCU,EOCM,EOCM_HCP2,EOCM_HC_Superset
 SG_ LRRODPB2P_VOTk3PoILVAuth : 202|9@0- (0.125,0) [-32|31.875] "m/s" ACP2_MCU,EOCM,EOCM_HCP2,EOCM_HC_Superset
 SG_ LRRODPB2P_VOTk3PoILVCAuth : 209|10@0+ (0.125,0) [0|127.875] "(m/s)^2" ACP2_MCU,EOCM,EOCM_HCP2,EOCM_HC_Superset
 SG_ LRRODPB2P_VOTk4CICOPotAuth : 229|6@0+ (2,0) [0|126] "%" ACP2_MCU,EOCM,EOCM_HCP2,EOCM_HC_Superset
 SG_ LRRODPB2P_VOTk3TypCnfdAuth : 231|2@0+ (1,0) [0|3] "" ACP2_MCU,EOCM,EOCM_HCP2,EOCM_HC_Superset
 SG_ LRRODPB2P_VOTk4IDAuth : 233|7@0+ (1,0) [0|127] "" ACP2_MCU,EOCM,EOCM_HCP2,EOCM_HC_Superset
 SG_ LRRODPB2P_VOTk4DynPrpStsAuth : 234|1@0+ (1,0) [0|1] "" ACP2_MCU,EOCM,EOCM_HCP2,EOCM_HC_Superset
 SG_ LRRODPB2P_VOTk4DynPrpAuth : 237|3@0+ (1,0) [0|4] "" ACP2_MCU,EOCM,EOCM_HCP2,EOCM_HC_Superset
 SG_ LRRODPB2P_VOTk4CnfdStsAuth : 239|2@0+ (1,0) [0|3] "" ACP2_MCU,EOCM,EOCM_HCP2,EOCM_HC_Superset
 SG_ LRRODPB2P_VOTk4PoILAAuth : 240|9@0- (0.125,0) [-32|31.875] "m/s^2" ACP2_MCU,EOCM,EOCM_HCP2,EOCM_HC_Superset
 SG_ LRRODPB2P_VOTk4MStsAuth : 242|2@0+ (1,0) [0|3] "" ACP2_MCU,EOCM,EOCM_HCP2,EOCM_HC_Superset
 SG_ LRRODPB2P_VOTk4PoILgAAuth : 263|9@0- (0.125,0) [-32|31.875] "m/s^2" ACP2_MCU,EOCM,EOCM_HCP2,EOCM_HC_Superset
 SG_ LRRODPB2P_VOTk4PoILgPsAuth : 270|11@0+ (0.125,0) [0|255.875] "m" ACP2_MCU,EOCM,EOCM_HCP2,EOCM_HC_Superset
 SG_ LRRODPB2P_VOTk4PoILgPsCAuth : 275|15@0+ (0.01,0) [0|327.67] "m^2" ACP2_MCU,EOCM,EOCM_HCP2,EOCM_HC_Superset
 SG_ LRRODPB2P_VOTk4PoILgthAuth : 292|11@0+ (0.125,0) [0|255.875] "m" ACP2_MCU,EOCM,EOCM_HCP2,EOCM_HC_Superset
 SG_ LRRODPB2P_VOTk4PoILgVAuth : 297|11@0- (0.125,0) [-128|127.875] "m/s" ACP2_MCU,EOCM,EOCM_HCP2,EOCM_HC_Superset
 SG_ LRRODPB2P_VOTk4PoILgVCAuth : 318|10@0+ (0.125,0) [0|127.875] "(m/s)^2" ACP2_MCU,EOCM,EOCM_HCP2,EOCM_HC_Superset
 SG_ LRRODPB2P_VOTk4PoILPsAuth : 324|10@0- (0.125,0) [-64|63.875] "m" ACP2_MCU,EOCM,EOCM_HCP2,EOCM_HC_Superset
 SG_ LRRODPB2P_VOTk4PoILPsCAuth : 330|14@0+ (0.01,0) [0|163.83] "m^2" ACP2_MCU,EOCM,EOCM_HCP2,EOCM_HC_Superset
 SG_ LRRODPB2P_VOTk4PoILVAuth : 348|9@0- (0.125,0) [-32|31.875] "m/s" ACP2_MCU,EOCM,EOCM_HCP2,EOCM_HC_Superset
 SG_ LRRODPB2P_VOTk4PoILVCAuth : 355|10@0+ (0.125,0) [0|127.875] "(m/s)^2" ACP2_MCU,EOCM,EOCM_HCP2,EOCM_HC_Superset
 SG_ LRRODPB2P_VOTk4TypCnfdAuth : 361|2@0+ (1,0) [0|3] "" ACP2_MCU,EOCM,EOCM_HCP2,EOCM_HC_Superset
 SG_ LRRODPB2P_VOTk5CnfdStsAuth : 369|2@0+ (1,0) [0|3] "" ACP2_MCU,EOCM,EOCM_HCP2,EOCM_HC_Superset
 SG_ LRRODPB2P_VOTk5CICOPotAuth : 375|6@0+ (2,0) [0|126] "%" ACP2_MCU,EOCM,EOCM_HCP2,EOCM_HC_Superset
 SG_ LRRODPB2P_VOTk5IDAuth : 379|7@0+ (1,0) [0|127] "" ACP2_MCU,EOCM,EOCM_HCP2,EOCM_HC_Superset
 SG_ LRRODPB2P_VOTk5DynPrpStsAuth : 380|1@0+ (1,0) [0|1] "" ACP2_MCU,EOCM,EOCM_HCP2,EOCM_HC_Superset
 SG_ LRRODPB2P_VOTk5DynPrpAuth : 383|3@0+ (1,0) [0|4] "" ACP2_MCU,EOCM,EOCM_HCP2,EOCM_HC_Superset
 SG_ LRRODPB2P_VOTk5LgthdthAuth : 388|11@0+ (0.125,0) [0|255.875] "m" ACP2_MCU,EOCM,EOCM_HCP2,EOCM_HC_Superset
 SG_ LRRODPB2P_VOTk5MStsAuth : 393|2@0+ (1,0) [0|3] "" ACP2_MCU,EOCM,EOCM_HCP2,EOCM_HC_Superset
 SG_ LRRODPB2P_VOTk5PoILAAuth : 407|9@0- (0.125,0) [-32|31.875] "m/s^2" ACP2_MCU,EOCM,EOCM_HCP2,EOCM_HC_Superset
 SG_ LRRODPB2P_VOTk5PoILgAAuth : 414|9@0- (0.125,0) [-32|31.875] "m/s^2" ACP2_MCU,EOCM,EOCM_HCP2,EOCM_HC_Superset
 SG_ LRRODPB2P_VOTk5PoILgPsAuth : 421|11@0+ (0.125,0) [0|255.875] "m" ACP2_MCU,EOCM,EOCM_HCP2,EOCM_HC_Superset
 SG_ LRRODPB2P_VOTk5PoILgPsCAuth : 426|15@0+ (0.01,0) [0|327.67] "m^2" ACP2_MCU,EOCM,EOCM_HCP2,EOCM_HC_Superset
 SG_ LRRODPB2P_VOTk5PoILgVAuth : 443|11@0- (0.125,0) [-128|127.875] "m/s" ACP2_MCU,EOCM,EOCM_HCP2,EOCM_HC_Superset
 SG_ LRRODPB2P_VOTk5PoILgVCAuth : 448|10@0+ (0.125,0) [0|127.875] "(m/s)^2" ACP2_MCU,EOCM,EOCM_HCP2,EOCM_HC_Superset
 SG_ LRRODPB2P_VOTk5PoILPsAuth : 470|10@0- (0.125,0) [-64|63.875] "m" ACP2_MCU,EOCM,EOCM_HCP2,EOCM_HC_Superset
 SG_ LRRODPB2P_VOTk5PoILPsCAuth : 476|14@0+ (0.01,0) [0|163.83] "m^2" ACP2_MCU,EOCM,EOCM_HCP2,EOCM_HC_Superset
 SG_ LRRODPB2P_VOTk5PoILVAuth : 494|9@0- (0.125,0) [-32|31.875] "m/s" ACP2_MCU,EOCM,EOCM_HCP2,EOCM_HC_Superset
 SG_ LRRODPB2P_VOTk5PoILVCAuth : 501|10@0+ (0.125,0) [0|127.875] "(m/s)^2" ACP2_MCU,EOCM,EOCM_HCP2,EOCM_HC_Superset
 SG_ LRRODPB2P_Filler : 505|2@0+ (1,0) [0|3] "" ACP2_MCU,EOCM,EOCM_HCP2,EOCM_HC_Superset
 SG_ LRRODPB2P_VOTk5TypCnfdAuth : 507|2@0+ (1,0) [0|3] "" ACP2_MCU,EOCM,EOCM_HCP2,EOCM_HC_Superset

BA_DEF_ SG_  "SignalType" STRING ;
BA_DEF_ SG_  "SignalLongName" STRING ;
BA_DEF_ BO_  "GenMsgCycleTime" INT 0 10000;
BA_DEF_ BO_  "GenMsgSendType" ENUM "cyclicX","spontanX","cyclicIfActiveX","spontanWithDelay","cyclicAndSpontanX","cyclicAndSpontanWithDelay","spontanWithRepetition","cyclicIfActiveAndSpontanWD";
BA_DEF_ BO_  "VFrameFormat" ENUM  "StandardCAN","ExtendedCAN","reserved","reserved","reserved","reserved","reserved","reserved","reserved","reserved","reserved","reserved","reserved","reserved","StandardCAN_FD","ExtendedCAN_FD";
BA_DEF_DEF_  "SignalType" "";
BA_DEF_DEF_  "SignalLongName" "";
BA_DEF_DEF_  "GenMsgCycleTime" 0;
BA_DEF_DEF_  "GenMsgSendType" "cyclicX";
BA_DEF_DEF_  "VFrameFormat" "StandardCAN";
BA_ "VFrameFormat" BO_ 219 14;
BA_ "VFrameFormat" BO_ 237 14;
BA_ "VFrameFormat" BO_ 218 14;
BA_ "VFrameFormat" BO_ 233 14;
BA_ "VFrameFormat" BO_ 240 14;
BA_ "GenMsgCycleTime" BO_ 718 100;
BA_ "VFrameFormat" BO_ 718 14;
BA_ "GenMsgCycleTime" BO_ 2147745810 1000;
BA_ "VFrameFormat" BO_ 914 14;
BA_ "GenMsgCycleTime" BO_ 87 10;
BA_ "VFrameFormat" BO_ 87 14;
BA_ "VFrameFormat" BO_ 687 14;
BA_ "GenMsgCycleTime" BO_ 109 20;
BA_ "VFrameFormat" BO_ 109 14;
BA_ "GenMsgCycleTime" BO_ 38 20;
BA_ "VFrameFormat" BO_ 38 14;
BA_ "GenMsgCycleTime" BO_ 1419 1000;
BA_ "VFrameFormat" BO_ 1419 14;
BA_ "GenMsgCycleTime" BO_ 1408 1000;
BA_ "VFrameFormat" BO_ 1408 14;
BA_ "GenMsgCycleTime" BO_ 1423 1000;
BA_ "VFrameFormat" BO_ 1423 14;
BA_ "GenMsgCycleTime" BO_ 1420 1000;
BA_ "VFrameFormat" BO_ 1420 14;
BA_ "GenMsgCycleTime" BO_ 1421 1000;
BA_ "VFrameFormat" BO_ 1421 14;
BA_ "GenMsgCycleTime" BO_ 1409 1000;
BA_ "VFrameFormat" BO_ 1409 14;
BA_ "GenMsgCycleTime" BO_ 1418 1000;
BA_ "VFrameFormat" BO_ 1418 14;
BA_ "GenMsgCycleTime" BO_ 681 100;
BA_ "VFrameFormat" BO_ 681 14;
BA_ "GenMsgCycleTime" BO_ 1410 1000;
BA_ "VFrameFormat" BO_ 1410 14;
BA_ "GenMsgCycleTime" BO_ 1428 1000;
BA_ "VFrameFormat" BO_ 1428 14;
BA_ "GenMsgCycleTime" BO_ 192 50;
BA_ "VFrameFormat" BO_ 192 14;
BA_ "GenMsgCycleTime" BO_ 1411 1000;
BA_ "VFrameFormat" BO_ 1411 14;
BA_ "GenMsgCycleTime" BO_ 719 100;
BA_ "VFrameFormat" BO_ 719 14;
BA_ "GenMsgCycleTime" BO_ 1413 1000;
BA_ "VFrameFormat" BO_ 1413 14;
BA_ "GenMsgCycleTime" BO_ 162 50;
BA_ "VFrameFormat" BO_ 162 14;
BA_ "GenMsgCycleTime" BO_ 536 50;
BA_ "VFrameFormat" BO_ 536 14;
BA_ "GenMsgCycleTime" BO_ 523 50;
BA_ "VFrameFormat" BO_ 523 14;
BA_ "VFrameFormat" BO_ 657 14;
BA_ "VFrameFormat" BO_ 241 14;
BA_ "SignalLongName" SG_ 219 FCODPB8P_FVLBTk8CrvAuth "Front Camera Object Detection and Processing Burst 8 Protected : Forward Vision Lane Boundary Track 8 Curvature Authenticated";
BA_ "SignalType" SG_ 219 FCODPB8P_FVLBTk8ClrAuth "ENM";
BA_ "SignalLongName" SG_ 219 FCODPB8P_FVLBTk8ClrAuth "Front Camera Object Detection and Processing Burst 8 Protected : Forward Vision Lane Boundary Track 8 Color Authenticated";
BA_ "SignalLongName" SG_ 219 FCODPB8P_BrstID "Front Camera Object Detection and Processing Burst 8 Protected : Burst ID";
BA_ "SignalLongName" SG_ 219 FCODPB8P_FVLBTk8CrvDrvtAuth "Front Camera Object Detection and Processing Burst 8 Protected : Forward Vision Lane Boundary Track 8 Curvature Derivative Authenticated";
BA_ "SignalLongName" SG_ 219 FCODPB8P_FVLBTk8FPSABCQOvrAuth "Front Camera Object Detection and Processing Burst 8 Protected : Forward Vision Lane Boundary Track 8 First Polynomial Segment ABC Quality Overall Authenticated";
BA_ "SignalLongName" SG_ 219 FCODPB8P_FVLBTk8FPSAQAuth "Front Camera Object Detection and Processing Burst 8 Protected : Forward Vision Lane Boundary Track 8 First Polynomial Segment A Quality Authenticated";
BA_ "SignalLongName" SG_ 219 FCODPB8P_FVLBTk8FPSBQAuth "Front Camera Object Detection and Processing Burst 8 Protected : Forward Vision Lane Boundary Track 8 First Polynomial Segment B Quality Authenticated";
BA_ "SignalLongName" SG_ 219 FCODPB8P_FVLBTk8FPSCQAuth "Front Camera Object Detection and Processing Burst 8 Protected : Forward Vision Lane Boundary Track 8 First Polynomial Segment C Quality Authenticated";
BA_ "SignalLongName" SG_ 219 FCODPB8P_FVLBTk8HdgAuth "Front Camera Object Detection and Processing Burst 8 Protected : Forward Vision Lane Boundary Track 8 Heading Authenticated";
BA_ "SignalLongName" SG_ 219 FCODPB8P_FVLBTk8OfstAuth "Front Camera Object Detection and Processing Burst 8 Protected : Forward Vision Lane Boundary Track 8 Offset Authenticated";
BA_ "SignalType" SG_ 219 FCODPB8P_FVLBTk8PstnTypAuth "ENM";
BA_ "SignalLongName" SG_ 219 FCODPB8P_FVLBTk8PstnTypAuth "Front Camera Object Detection and Processing Burst 8 Protected : Forward Vision Lane Boundary Track 8 Position Type Authenticated";
BA_ "SignalType" SG_ 219 FCODPB8P_FVLBTk8TypAuth "ENM";
BA_ "SignalLongName" SG_ 219 FCODPB8P_FVLBTk8TypAuth "Front Camera Object Detection and Processing Burst 8 Protected : Forward Vision Lane Boundary Track 8 Type Authenticated";
BA_ "SignalType" SG_ 219 FCODPB8P_FVLBTk8QltyAuth "ENM";
BA_ "SignalLongName" SG_ 219 FCODPB8P_FVLBTk8QltyAuth "Front Camera Object Detection and Processing Burst 8 Protected : Forward Vision Lane Boundary Track 8 Quality Authenticated";
BA_ "SignalLongName" SG_ 219 FCODPB8P_FVLBTk8VSLgDistAuth "Front Camera Object Detection and Processing Burst 8 Protected : Forward Vision Lane Boundary Track 8 View Start Longitudinal Distance Authenticated";
BA_ "SignalLongName" SG_ 219 FCODPB8P_FVLBTk8VRLgDistAuth "Front Camera Object Detection and Processing Burst 8 Protected : Forward Vision Lane Boundary Track 8 View Range Longitudinal Distance Authenticated";
BA_ "SignalLongName" SG_ 219 FCODPB8P_FVLBTk8WdthAuth "Front Camera Object Detection and Processing Burst 8 Protected : Forward Vision Lane Boundary Track 8 Width Authenticated";
BA_ "SignalLongName" SG_ 219 FCODPB8P_FVVOTk8CICOPotAuth "Front Camera Object Detection and Processing Burst 8 Protected : Forward Vision Vehicle Object Track 8 Cut In Cut Out Potential Authenticated";
BA_ "SignalType" SG_ 219 FCODPB8P_FVVOTk8BrkLgtStsAuth "ENM";
BA_ "SignalLongName" SG_ 219 FCODPB8P_FVVOTk8BrkLgtStsAuth "Front Camera Object Detection and Processing Burst 8 Protected : Forward Vision Vehicle Object Track 8 Brake Light Status Authenticated";
BA_ "SignalType" SG_ 219 FCODPB8P_FVVOTk8DynPrpAuth "ENM";
BA_ "SignalLongName" SG_ 219 FCODPB8P_FVVOTk8DynPrpAuth "Front Camera Object Detection and Processing Burst 8 Protected : Forward Vision Vehicle Object Track 8 Dynamic Property Authenticated";
BA_ "SignalType" SG_ 219 FCODPB8P_FVVOTk8CnfdStsAuth "ENM";
BA_ "SignalLongName" SG_ 219 FCODPB8P_FVVOTk8CnfdStsAuth "Front Camera Object Detection and Processing Burst 8 Protected : Forward Vision Vehicle Object Track 8 Confidence Status Authenticated";
BA_ "SignalLongName" SG_ 219 FCODPB8P_FVVOTk8HdgAngAuth "Front Camera Object Detection and Processing Burst 8 Protected : Forward Vision Vehicle Object Track 8 Heading Angle Authenticated";
BA_ "SignalType" SG_ 219 FCODPB8P_FVVOTk8DynPrpStsAuth "ENM";
BA_ "SignalLongName" SG_ 219 FCODPB8P_FVVOTk8DynPrpStsAuth "Front Camera Object Detection and Processing Burst 8 Protected : Forward Vision Vehicle Object Track 8 Dynamic Property Status Authenticated";
BA_ "SignalLongName" SG_ 219 FCODPB8P_FVVOTk8HdgAngCAuth "Front Camera Object Detection and Processing Burst 8 Protected : Forward Vision Vehicle Object Track 8 Heading Angle Covariance Authenticated";
BA_ "SignalLongName" SG_ 219 FCODPB8P_FVVOTk8IDAuth "Front Camera Object Detection and Processing Burst 8 Protected : Forward Vision Vehicle Object Track 8 ID Authenticated";
BA_ "SignalLongName" SG_ 219 FCODPB8P_FVVOTk8PoILAAuth "Front Camera Object Detection and Processing Burst 8 Protected : Forward Vision Vehicle Object Track 8 Point of Interest Lateral Acceleration Authenticated";
BA_ "SignalType" SG_ 219 FCODPB8P_FVVOTk8MStsAuth "ENM";
BA_ "SignalLongName" SG_ 219 FCODPB8P_FVVOTk8MStsAuth "Front Camera Object Detection and Processing Burst 8 Protected : Forward Vision Vehicle Object Track 8 Measurement Status Authenticated";
BA_ "SignalType" SG_ 219 FCODPB8P_FVVOTk8LnAsmtAuth "ENM";
BA_ "SignalLongName" SG_ 219 FCODPB8P_FVVOTk8LnAsmtAuth "Front Camera Object Detection and Processing Burst 8 Protected : Forward Vision Vehicle Object Track 8 Lane Assignment Authenticated";
BA_ "SignalLongName" SG_ 219 FCODPB8P_FVVOTk8PoILgAAuth "Front Camera Object Detection and Processing Burst 8 Protected : Forward Vision Vehicle Object Track 8 Point of Interest Longitudinal Acceleration Authenticated";
BA_ "SignalLongName" SG_ 219 FCODPB8P_FVVOTk8PoILgPsAuth "Front Camera Object Detection and Processing Burst 8 Protected : Forward Vision Vehicle Object Track 8 Point of Interest Longitudinal Position Authenticated";
BA_ "SignalLongName" SG_ 219 FCODPB8P_FVVOTk8PoILgPsCAuth "Front Camera Object Detection and Processing Burst 8 Protected : Forward Vision Vehicle Object Track 8 Point of Interest Longitudinal Position Covariance Authenticated";
BA_ "SignalLongName" SG_ 219 FCODPB8P_FVVOTk8PoILgVAuth "Front Camera Object Detection and Processing Burst 8 Protected : Forward Vision Vehicle Object Track 8 Point of Interest Longitudinal Velocity Authenticated";
BA_ "SignalLongName" SG_ 219 FCODPB8P_FVVOTk8PoILgVCAuth "Front Camera Object Detection and Processing Burst 8 Protected : Forward Vision Vehicle Object Track 8 Point of Interest Longitudinal Velocity Covariance Authenticated";
BA_ "SignalLongName" SG_ 219 FCODPB8P_FVVOTk8PoILPsAuth "Front Camera Object Detection and Processing Burst 8 Protected : Forward Vision Vehicle Object Track 8 Point of Interest Lateral Position Authenticated";
BA_ "SignalLongName" SG_ 219 FCODPB8P_FVVOTk8PoILPsCAuth "Front Camera Object Detection and Processing Burst 8 Protected : Forward Vision Vehicle Object Track 8 Point of Interest Lateral Position Covariance Authenticated";
BA_ "SignalLongName" SG_ 219 FCODPB8P_FVVOTk8PoILVAuth "Front Camera Object Detection and Processing Burst 8 Protected : Forward Vision Vehicle Object Track 8 Point of Interest Lateral Velocity Authenticated";
BA_ "SignalLongName" SG_ 219 FCODPB8P_FVVOTk8PoILVCAuth "Front Camera Object Detection and Processing Burst 8 Protected : Forward Vision Vehicle Object Track 8 Point of Interest Lateral Velocity Covariance Authenticated";
BA_ "SignalLongName" SG_ 219 FCODPB8P_FVVOTk8PoIWAuth "Front Camera Object Detection and Processing Burst 8 Protected : Forward Vision Vehicle Object Track 8 Point of Interest Width Authenticated";
BA_ "SignalType" SG_ 219 FCODPB8P_FVVOTk9BrkLgtStsAuth "ENM";
BA_ "SignalLongName" SG_ 219 FCODPB8P_FVVOTk9BrkLgtStsAuth "Front Camera Object Detection and Processing Burst 8 Protected : Forward Vision Vehicle Object Track 9 Brake Light Status Authenticated";
BA_ "SignalType" SG_ 219 FCODPB8P_FVVOTk8TypCnfdAuth "ENM";
BA_ "SignalLongName" SG_ 219 FCODPB8P_FVVOTk8TypCnfdAuth "Front Camera Object Detection and Processing Burst 8 Protected : Forward Vision Vehicle Object Track 8 Type Confidence Authenticated";
BA_ "SignalType" SG_ 219 FCODPB8P_FVVOTk8TypAuth "ENM";
BA_ "SignalLongName" SG_ 219 FCODPB8P_FVVOTk8TypAuth "Front Camera Object Detection and Processing Burst 8 Protected : Forward Vision Vehicle Object Track 8 Type Authenticated";
BA_ "SignalType" SG_ 219 FCODPB8P_FVVOTk8TSLgtStsAuth "ENM";
BA_ "SignalLongName" SG_ 219 FCODPB8P_FVVOTk8TSLgtStsAuth "Front Camera Object Detection and Processing Burst 8 Protected : Forward Vision Vehicle Object Track 8 Turn Signal Light Status Authenticated";
BA_ "SignalType" SG_ 219 FCODPB8P_FVVOTk9CnfdStsAuth "ENM";
BA_ "SignalLongName" SG_ 219 FCODPB8P_FVVOTk9CnfdStsAuth "Front Camera Object Detection and Processing Burst 8 Protected : Forward Vision Vehicle Object Track 9 Confidence Status Authenticated";
BA_ "SignalLongName" SG_ 219 FCODPB8P_FVVOTk9CICOPotAuth "Front Camera Object Detection and Processing Burst 8 Protected : Forward Vision Vehicle Object Track 9 Cut In Cut Out Potential Authenticated";
BA_ "SignalLongName" SG_ 219 FCODPB8P_FVVOTk9HdgAngAuth "Front Camera Object Detection and Processing Burst 8 Protected : Forward Vision Vehicle Object Track 9 Heading Angle Authenticated";
BA_ "SignalType" SG_ 219 FCODPB8P_FVVOTk9DynPrpStsAuth "ENM";
BA_ "SignalLongName" SG_ 219 FCODPB8P_FVVOTk9DynPrpStsAuth "Front Camera Object Detection and Processing Burst 8 Protected : Forward Vision Vehicle Object Track 9 Dynamic Property Status Authenticated";
BA_ "SignalType" SG_ 219 FCODPB8P_FVVOTk9DynPrpAuth "ENM";
BA_ "SignalLongName" SG_ 219 FCODPB8P_FVVOTk9DynPrpAuth "Front Camera Object Detection and Processing Burst 8 Protected : Forward Vision Vehicle Object Track 9 Dynamic Property Authenticated";
BA_ "SignalLongName" SG_ 219 FCODPB8P_FVVOTk9HdgAngCAuth "Front Camera Object Detection and Processing Burst 8 Protected : Forward Vision Vehicle Object Track 9 Heading Angle Covariance Authenticated";
BA_ "SignalLongName" SG_ 219 FCODPB8P_FVVOTk9IDAuth "Front Camera Object Detection and Processing Burst 8 Protected : Forward Vision Vehicle Object Track 9 ID Authenticated";
BA_ "SignalType" SG_ 219 FCODPB8P_FVVOTk9MStsAuth "ENM";
BA_ "SignalLongName" SG_ 219 FCODPB8P_FVVOTk9MStsAuth "Front Camera Object Detection and Processing Burst 8 Protected : Forward Vision Vehicle Object Track 9 Measurement Status Authenticated";
BA_ "SignalType" SG_ 219 FCODPB8P_FVVOTk9LnAsmtAuth "ENM";
BA_ "SignalLongName" SG_ 219 FCODPB8P_FVVOTk9LnAsmtAuth "Front Camera Object Detection and Processing Burst 8 Protected : Forward Vision Vehicle Object Track 9 Lane Assignment Authenticated";
BA_ "SignalLongName" SG_ 219 FCODPB8P_FVVOTk9PoILAAuth "Front Camera Object Detection and Processing Burst 8 Protected : Forward Vision Vehicle Object Track 9 Point of Interest Lateral Acceleration Authenticated";
BA_ "SignalLongName" SG_ 219 FCODPB8P_FVVOTk9PoILgAAuth "Front Camera Object Detection and Processing Burst 8 Protected : Forward Vision Vehicle Object Track 9 Point of Interest Longitudinal Acceleration Authenticated";
BA_ "SignalLongName" SG_ 219 FCODPB8P_FVVOTk9PoILgPsAuth "Front Camera Object Detection and Processing Burst 8 Protected : Forward Vision Vehicle Object Track 9 Point of Interest Longitudinal Position Authenticated";
BA_ "SignalLongName" SG_ 219 FCODPB8P_FVVOTk9PoILgPsCAuth "Front Camera Object Detection and Processing Burst 8 Protected : Forward Vision Vehicle Object Track 9 Point of Interest Longitudinal Position Covariance Authenticated";
BA_ "SignalLongName" SG_ 219 FCODPB8P_FVVOTk9PoILgVAuth "Front Camera Object Detection and Processing Burst 8 Protected : Forward Vision Vehicle Object Track 9 Point of Interest Longitudinal Velocity Authenticated";
BA_ "SignalLongName" SG_ 219 FCODPB8P_FVVOTk9PoILgVCAuth "Front Camera Object Detection and Processing Burst 8 Protected : Forward Vision Vehicle Object Track 9 Point of Interest Longitudinal Velocity Covariance Authenticated";
BA_ "SignalLongName" SG_ 219 FCODPB8P_FVVOTk9PoILPsAuth "Front Camera Object Detection and Processing Burst 8 Protected : Forward Vision Vehicle Object Track 9 Point of Interest Lateral Position Authenticated";
BA_ "SignalLongName" SG_ 219 FCODPB8P_FVVOTk9PoILPsCAuth "Front Camera Object Detection and Processing Burst 8 Protected : Forward Vision Vehicle Object Track 9 Point of Interest Lateral Position Covariance Authenticated";
BA_ "SignalLongName" SG_ 219 FCODPB8P_FVVOTk9PoILVAuth "Front Camera Object Detection and Processing Burst 8 Protected : Forward Vision Vehicle Object Track 9 Point of Interest Lateral Velocity Authenticated";
BA_ "SignalLongName" SG_ 219 FCODPB8P_FVVOTk9PoILVCAuth "Front Camera Object Detection and Processing Burst 8 Protected : Forward Vision Vehicle Object Track 9 Point of Interest Lateral Velocity Covariance Authenticated";
BA_ "SignalLongName" SG_ 219 FCODPB8P_FVVOTk9PoIWAuth "Front Camera Object Detection and Processing Burst 8 Protected : Forward Vision Vehicle Object Track 9 Point of Interest Width Authenticated";
BA_ "SignalType" SG_ 219 FCODPB8P_FVVOTk9TypAuth "ENM";
BA_ "SignalLongName" SG_ 219 FCODPB8P_FVVOTk9TypAuth "Front Camera Object Detection and Processing Burst 8 Protected : Forward Vision Vehicle Object Track 9 Type Authenticated";
BA_ "SignalType" SG_ 219 FCODPB8P_FVVOTk9TSLgtStsAuth "ENM";
BA_ "SignalLongName" SG_ 219 FCODPB8P_FVVOTk9TSLgtStsAuth "Front Camera Object Detection and Processing Burst 8 Protected : Forward Vision Vehicle Object Track 9 Turn Signal Light Status Authenticated";
BA_ "SignalLongName" SG_ 219 FCODPB8P_Filler "Front Camera Object Detection and Processing Burst 8 Protected : Filler";
BA_ "SignalType" SG_ 219 FrwdVsnVehObjTk8DatIntegCkd "ENM";
BA_ "SignalLongName" SG_ 219 FrwdVsnVehObjTk8DatIntegCkd "Front Camera Object Detection and Processing Burst 8 Protected : Forward Vision Vehicle Object Track 8 Data Integrity Checked";
BA_ "SignalType" SG_ 219 FrwdVsnLnBdryTk8DatIntegCkd "ENM";
BA_ "SignalLongName" SG_ 219 FrwdVsnLnBdryTk8DatIntegCkd "Front Camera Object Detection and Processing Burst 8 Protected : Forward Vision Lane Boundary Track 8 Data Integrity Checked";
BA_ "SignalType" SG_ 219 FCODPB8P_FVVOTk9TypCnfdAuth "ENM";
BA_ "SignalLongName" SG_ 219 FCODPB8P_FVVOTk9TypCnfdAuth "Front Camera Object Detection and Processing Burst 8 Protected : Forward Vision Vehicle Object Track 9 Type Confidence Authenticated";
BA_ "SignalLongName" SG_ 219 FCODPB8P_FillerExtnd "Front Camera Object Detection and Processing Burst 8 Protected : Filler Extended";
BA_ "SignalType" SG_ 237 FCODPB9P_FVCIPthVehAlrtNwAuth "ENM";
BA_ "SignalLongName" SG_ 237 FCODPB9P_FVCIPthVehAlrtNwAuth "Front Camera Object Detection and Processing Burst 9 Protected : Forward Vision Closest In Path Vehicle Alert Now Authenticated";
BA_ "SignalType" SG_ 237 FCODPB9P_FVCIPthVehAhdNwAuth "ENM";
BA_ "SignalLongName" SG_ 237 FCODPB9P_FVCIPthVehAhdNwAuth "Front Camera Object Detection and Processing Burst 9 Protected : Forward Vision Closest In Path Vehicle Ahead Now Authenticated";
BA_ "SignalType" SG_ 237 FCODPB9P_FrwdDistIndDgrdAuth "ENM";
BA_ "SignalLongName" SG_ 237 FCODPB9P_FrwdDistIndDgrdAuth "Front Camera Object Detection and Processing Burst 9 Protected : Forward Distance Indication Degraded Authenticated";
BA_ "SignalType" SG_ 237 FCODPB9P_FrwdClsnAlrtDgrdAuth "ENM";
BA_ "SignalLongName" SG_ 237 FCODPB9P_FrwdClsnAlrtDgrdAuth "Front Camera Object Detection and Processing Burst 9 Protected : Forward Collision Alert Degraded Authenticated";
BA_ "SignalType" SG_ 237 FCODPB9P_ClsnImntBrkgDgrdAuth "ENM";
BA_ "SignalLongName" SG_ 237 FCODPB9P_ClsnImntBrkgDgrdAuth "Front Camera Object Detection and Processing Burst 9 Protected : Collision Imminent Braking Degraded Authenticated";
BA_ "SignalType" SG_ 237 FCODPB9P_AdpCruzCtlDgrdAuth "ENM";
BA_ "SignalLongName" SG_ 237 FCODPB9P_AdpCruzCtlDgrdAuth "Front Camera Object Detection and Processing Burst 9 Protected : Adaptive Cruise Control Degraded Authenticated";
BA_ "SignalLongName" SG_ 237 FCODPB9P_BrstID "Front Camera Object Detection and Processing Burst 9 Protected : Burst ID";
BA_ "SignalLongName" SG_ 237 FCODPB9P_FVL1DrivableCnfdAuth "Front Camera Object Detection and Processing Burst 9 Protected : Forward Vision Lane 1 Drivable Confidence Authenticated";
BA_ "SignalType" SG_ 237 FCODPB9P_FVHTPNtfyNwAuth "ENM";
BA_ "SignalLongName" SG_ 237 FCODPB9P_FVHTPNtfyNwAuth "Front Camera Object Detection and Processing Burst 9 Protected : Forward Vision Highest Threat Pedestrian Notify Now Authenticated";
BA_ "SignalType" SG_ 237 FCODPB9P_FVHTPBrkNwAuth "ENM";
BA_ "SignalLongName" SG_ 237 FCODPB9P_FVHTPBrkNwAuth "Front Camera Object Detection and Processing Burst 9 Protected : Forward Vision Highest Threat Pedestrian Brake Now Authenticated";
BA_ "SignalType" SG_ 237 FCODPB9P_FVHTPAlrtNwAuth "ENM";
BA_ "SignalLongName" SG_ 237 FCODPB9P_FVHTPAlrtNwAuth "Front Camera Object Detection and Processing Burst 9 Protected : Forward Vision Highest Threat Pedestrian Alert Now Authenticated";
BA_ "SignalType" SG_ 237 FCODPB9P_FVCIPthVehBrkNwAuth "ENM";
BA_ "SignalLongName" SG_ 237 FCODPB9P_FVCIPthVehBrkNwAuth "Front Camera Object Detection and Processing Burst 9 Protected : Forward Vision Closest In Path Vehicle Brake Now Authenticated";
BA_ "SignalLongName" SG_ 237 FCODPB9P_FVL2DrivableCnfdAuth "Front Camera Object Detection and Processing Burst 9 Protected : Forward Vision Lane 2 Drivable Confidence Authenticated";
BA_ "SignalLongName" SG_ 237 FCODPB9P_FVL3DrivableCnfdAuth "Front Camera Object Detection and Processing Burst 9 Protected : Forward Vision Lane 3 Drivable Confidence Authenticated";
BA_ "SignalLongName" SG_ 237 FCODPB9P_FVL4DrivableCnfdAuth "Front Camera Object Detection and Processing Burst 9 Protected : Forward Vision Lane 4 Drivable Confidence Authenticated";
BA_ "SignalLongName" SG_ 237 FCODPB9P_FVLFTk1FPCrvCoefAuth "Front Camera Object Detection and Processing Burst 9 Protected : Forward Vision Lane Fusion Track 1 First Polynomial Curvature Coefficient Authenticated";
BA_ "SignalLongName" SG_ 237 FCODPB9P_FVL5DrivableCnfdAuth "Front Camera Object Detection and Processing Burst 9 Protected : Forward Vision Lane 5 Drivable Confidence Authenticated";
BA_ "SignalLongName" SG_ 237 FCODPB9P_FVLFTk1FPCrvDrvtCAuth "Front Camera Object Detection and Processing Burst 9 Protected : Forward Vision Lane Fusion Track 1 First Polynomial Curvature Derivative Coefficient Authenticated";
BA_ "SignalLongName" SG_ 237 FCODPB9P_FVLFTk1FPHdgCoefAuth "Front Camera Object Detection and Processing Burst 9 Protected : Forward Vision Lane Fusion Track 1 First Polynomial Heading Coefficient Authenticated";
BA_ "SignalLongName" SG_ 237 FCODPB9P_FVLFTk1FPOfstCoefAuth "Front Camera Object Detection and Processing Burst 9 Protected : Forward Vision Lane Fusion Track 1 First Polynomial Offset Coefficient Authenticated";
BA_ "SignalLongName" SG_ 237 FCODPB9P_FVLFTk1FPSegQltyAuth "Front Camera Object Detection and Processing Burst 9 Protected : Forward Vision Lane Fusion Track 1 First Polynomial Segment Quality Authenticated";
BA_ "SignalLongName" SG_ 237 FCODPB9P_FVLFTk1FPVRLgDistAuth "Front Camera Object Detection and Processing Burst 9 Protected : Forward Vision Lane Fusion Track 1 First Polynomial View Range Longitudinal Distance Authenticated";
BA_ "SignalLongName" SG_ 237 FCODPB9P_FVLFTk1FPVSLgDistAuth "Front Camera Object Detection and Processing Burst 9 Protected : Forward Vision Lane Fusion Track 1 First Polynomial View Start Longitudinal Distance Authenticated";
BA_ "SignalLongName" SG_ 237 FCODPB9P_FVLFTk2FPCrvCoefAuth "Front Camera Object Detection and Processing Burst 9 Protected : Forward Vision Lane Fusion Track 2 First Polynomial Curvature Coefficient Authenticated";
BA_ "SignalType" SG_ 237 FCODPB9P_FVLFTk1TypAuth "ENM";
BA_ "SignalLongName" SG_ 237 FCODPB9P_FVLFTk1TypAuth "Front Camera Object Detection and Processing Burst 9 Protected : Forward Vision Lane Fusion Track 1 Type Authenticated";
BA_ "SignalLongName" SG_ 237 FCODPB9P_FVLFTk2FPCrvDrvtCAuth "Front Camera Object Detection and Processing Burst 9 Protected : Forward Vision Lane Fusion Track 2 First Polynomial Curvature Derivative Coefficient Authenticated";
BA_ "SignalLongName" SG_ 237 FCODPB9P_FVLFTk2FPHdgCoefAuth "Front Camera Object Detection and Processing Burst 9 Protected : Forward Vision Lane Fusion Track 2 First Polynomial Heading Coefficient Authenticated";
BA_ "SignalLongName" SG_ 237 FCODPB9P_FVLFTk2FPOfstCoefAuth "Front Camera Object Detection and Processing Burst 9 Protected : Forward Vision Lane Fusion Track 2 First Polynomial Offset Coefficient Authenticated";
BA_ "SignalLongName" SG_ 237 FCODPB9P_FVLFTk2FPSegQltyAuth "Front Camera Object Detection and Processing Burst 9 Protected : Forward Vision Lane Fusion Track 2 First Polynomial Segment Quality Authenticated";
BA_ "SignalLongName" SG_ 237 FCODPB9P_FVLFTk2FPVRLgDistAuth "Front Camera Object Detection and Processing Burst 9 Protected : Forward Vision Lane Fusion Track 2 First Polynomial View Range Longitudinal Distance Authenticated";
BA_ "SignalType" SG_ 237 FCODPB9P_FVLFTk2TypAuth "ENM";
BA_ "SignalLongName" SG_ 237 FCODPB9P_FVLFTk2TypAuth "Front Camera Object Detection and Processing Burst 9 Protected : Forward Vision Lane Fusion Track 2 Type Authenticated";
BA_ "SignalLongName" SG_ 237 FCODPB9P_FVLFTk2FPVSLgDistAuth "Front Camera Object Detection and Processing Burst 9 Protected : Forward Vision Lane Fusion Track 2 First Polynomial View Start Longitudinal Distance Authenticated";
BA_ "SignalLongName" SG_ 237 FCODPB9P_FVLFTk3FPCrvCoefAuth "Front Camera Object Detection and Processing Burst 9 Protected : Forward Vision Lane Fusion Track 3 First Polynomial Curvature Coefficient Authenticated";
BA_ "SignalLongName" SG_ 237 FCODPB9P_FVLFTk3FPCrvDrvtCAuth "Front Camera Object Detection and Processing Burst 9 Protected : Forward Vision Lane Fusion Track 3 First Polynomial Curvature Derivative Coefficient Authenticated";
BA_ "SignalLongName" SG_ 237 FCODPB9P_FVLFTk3FPHdgCoefAuth "Front Camera Object Detection and Processing Burst 9 Protected : Forward Vision Lane Fusion Track 3 First Polynomial Heading Coefficient Authenticated";
BA_ "SignalLongName" SG_ 237 FCODPB9P_FVLFTk3FPOfstCoefAuth "Front Camera Object Detection and Processing Burst 9 Protected : Forward Vision Lane Fusion Track 3 First Polynomial Offset Coefficient Authenticated";
BA_ "SignalLongName" SG_ 237 FCODPB9P_FVLFTk3FPSegQltyAuth "Front Camera Object Detection and Processing Burst 9 Protected : Forward Vision Lane Fusion Track 3 First Polynomial Segment Quality Authenticated";
BA_ "SignalLongName" SG_ 237 FCODPB9P_FVLFTk3FPVRLgDistAuth "Front Camera Object Detection and Processing Burst 9 Protected : Forward Vision Lane Fusion Track 3 First Polynomial View Range Longitudinal Distance Authenticated";
BA_ "SignalLongName" SG_ 237 FCODPB9P_FVLFTk3FPVSLgDistAuth "Front Camera Object Detection and Processing Burst 9 Protected : Forward Vision Lane Fusion Track 3 First Polynomial View Start Longitudinal Distance Authenticated";
BA_ "SignalLongName" SG_ 237 FCODPB9P_FVLFTk4FPCrvCoefAuth "Front Camera Object Detection and Processing Burst 9 Protected : Forward Vision Lane Fusion Track 4 First Polynomial Curvature Coefficient Authenticated";
BA_ "SignalType" SG_ 237 FCODPB9P_FVLFTk3TypAuth "ENM";
BA_ "SignalLongName" SG_ 237 FCODPB9P_FVLFTk3TypAuth "Front Camera Object Detection and Processing Burst 9 Protected : Forward Vision Lane Fusion Track 3 Type Authenticated";
BA_ "SignalLongName" SG_ 237 FCODPB9P_FVLFTk4FPCrvDrvtCAuth "Front Camera Object Detection and Processing Burst 9 Protected : Forward Vision Lane Fusion Track 4 First Polynomial Curvature Derivative Coefficient Authenticated";
BA_ "SignalLongName" SG_ 237 FCODPB9P_FVLFTk4FPHdgCoefAuth "Front Camera Object Detection and Processing Burst 9 Protected : Forward Vision Lane Fusion Track 4 First Polynomial Heading Coefficient Authenticated";
BA_ "SignalLongName" SG_ 237 FCODPB9P_FVLFTk4FPOfstCoefAuth "Front Camera Object Detection and Processing Burst 9 Protected : Forward Vision Lane Fusion Track 4 First Polynomial Offset Coefficient Authenticated";
BA_ "SignalLongName" SG_ 237 FCODPB9P_FVLFTk4FPSegQltyAuth "Front Camera Object Detection and Processing Burst 9 Protected : Forward Vision Lane Fusion Track 4 First Polynomial Segment Quality Authenticated";
BA_ "SignalLongName" SG_ 237 FCODPB9P_FVLFTk4FPVRLgDistAuth "Front Camera Object Detection and Processing Burst 9 Protected : Forward Vision Lane Fusion Track 4 First Polynomial View Range Longitudinal Distance Authenticated";
BA_ "SignalLongName" SG_ 237 FCODPB9P_FVLFTk4FPVSLgDistAuth "Front Camera Object Detection and Processing Burst 9 Protected : Forward Vision Lane Fusion Track 4 First Polynomial View Start Longitudinal Distance Authenticated";
BA_ "SignalType" SG_ 237 FCODPB9P_PedtrnClsnBrkgDgrdAuth "ENM";
BA_ "SignalLongName" SG_ 237 FCODPB9P_PedtrnClsnBrkgDgrdAuth "Front Camera Object Detection and Processing Burst 9 Protected : Pedestrian Collision Braking Degraded Authenticated";
BA_ "SignalType" SG_ 237 FCODPB9P_PedtrnClsnAlrtDgrdAuth "ENM";
BA_ "SignalLongName" SG_ 237 FCODPB9P_PedtrnClsnAlrtDgrdAuth "Front Camera Object Detection and Processing Burst 9 Protected : Pedestrian Collision Alert Degraded Authenticated";
BA_ "SignalType" SG_ 237 FCODPB9P_LnKeepAsstDgrdAuth "ENM";
BA_ "SignalLongName" SG_ 237 FCODPB9P_LnKeepAsstDgrdAuth "Front Camera Object Detection and Processing Burst 9 Protected : Lane Keep Assist Degraded Authenticated";
BA_ "SignalType" SG_ 237 FCODPB9P_LnCntrDgrdAuth "ENM";
BA_ "SignalLongName" SG_ 237 FCODPB9P_LnCntrDgrdAuth "Front Camera Object Detection and Processing Burst 9 Protected : Lane Centering Degraded Authenticated";
BA_ "SignalType" SG_ 237 FCODPB9P_IntsctClsnMtgnDgrdAuth "ENM";
BA_ "SignalLongName" SG_ 237 FCODPB9P_IntsctClsnMtgnDgrdAuth "Front Camera Object Detection and Processing Burst 9 Protected : Intersection Collision Mitigation Degraded Authenticated";
BA_ "SignalType" SG_ 237 FCODPB9P_FVLFTk4TypAuth "ENM";
BA_ "SignalLongName" SG_ 237 FCODPB9P_FVLFTk4TypAuth "Front Camera Object Detection and Processing Burst 9 Protected : Forward Vision Lane Fusion Track 4 Type Authenticated";
BA_ "SignalLongName" SG_ 237 FCODPB9P_Filler "Front Camera Object Detection and Processing Burst 9 Protected : Filler";
BA_ "SignalType" SG_ 237 FrwdVsnVehObjTk9DatIntegCkd "ENM";
BA_ "SignalLongName" SG_ 237 FrwdVsnVehObjTk9DatIntegCkd "Front Camera Object Detection and Processing Burst 9 Protected : Forward Vision Vehicle Object Track 9 Data Integrity Checked";
BA_ "SignalType" SG_ 237 FrwdVsnLnBdryTk9DatIntegCkd "ENM";
BA_ "SignalLongName" SG_ 237 FrwdVsnLnBdryTk9DatIntegCkd "Front Camera Object Detection and Processing Burst 9 Protected : Forward Vision Lane Boundary Track 9 Data Integrity Checked";
BA_ "SignalType" SG_ 237 FCODPB9P_FVHTPPrfllNwAuth "ENM";
BA_ "SignalLongName" SG_ 237 FCODPB9P_FVHTPPrfllNwAuth "Front Camera Object Detection and Processing Burst 9 Protected : Forward Vision Highest Threat Pedestrian Prefill Now Authenticated";
BA_ "SignalType" SG_ 237 FCODPB9P_FVCIPthVehPrfllNwAuth "ENM";
BA_ "SignalLongName" SG_ 237 FCODPB9P_FVCIPthVehPrfllNwAuth "Front Camera Object Detection and Processing Burst 9 Protected : Forward Vision Closest In Path Vehicle Prefill Now Authenticated";
BA_ "SignalType" SG_ 237 FCODPB9P_PedtrnNtfnDgrdAuth "ENM";
BA_ "SignalLongName" SG_ 237 FCODPB9P_PedtrnNtfnDgrdAuth "Front Camera Object Detection and Processing Burst 9 Protected : Pedestrian Notification Degraded Authenticated";
BA_ "SignalLongName" SG_ 218 FCODPB10P_FVVOTk10PoI2LgPsAuth "Front Camera Object Detection and Processing Burst 10 Protected : Forward Vision Vehicle Object Track 10 Point of Interest 2nd Longitudinal Position Authenticated";
BA_ "SignalType" SG_ 218 FCODPB10P_FVVOTk10PoI1PsVisAuth "ENM";
BA_ "SignalLongName" SG_ 218 FCODPB10P_FVVOTk10PoI1PsVisAuth "Front Camera Object Detection and Processing Burst 10 Protected : Forward Vision Vehicle Object Track 10 Point of Interest First Position Visibility Authenticated";
BA_ "SignalLongName" SG_ 218 FCODPB10P_BrstID "Front Camera Object Detection and Processing Burst 10 Protected : Burst ID";
BA_ "SignalLongName" SG_ 218 FCODPB10P_FVVOTk10PoI2LPsAuth "Front Camera Object Detection and Processing Burst 10 Protected : Forward Vision Vehicle Object Track 10 Point of Interest 2nd Lateral Position Authenticated";
BA_ "SignalLongName" SG_ 218 FCODPB10P_FVVOTk10PoI3LgPsAuth "Front Camera Object Detection and Processing Burst 10 Protected : Forward Vision Vehicle Object Track 10 Point of Interest 3rd Longitudinal Position Authenticated";
BA_ "SignalType" SG_ 218 FCODPB10P_FVVOTk10PoI2PsVisAuth "ENM";
BA_ "SignalLongName" SG_ 218 FCODPB10P_FVVOTk10PoI2PsVisAuth "Front Camera Object Detection and Processing Burst 10 Protected : Forward Vision Vehicle Object Track 10 Point of Interest 2nd Position Visibility Authenticated";
BA_ "SignalLongName" SG_ 218 FCODPB10P_FVVOTk10PoI3LPsAuth "Front Camera Object Detection and Processing Burst 10 Protected : Forward Vision Vehicle Object Track 10 Point of Interest 3rd Lateral Position Authenticated";
BA_ "SignalLongName" SG_ 218 FCODPB10P_FVVOTk1PoI2LgPsAuth "Front Camera Object Detection and Processing Burst 10 Protected : Forward Vision Vehicle Object Track 1 Point of Interest 2nd Longitudinal Position Authenticated";
BA_ "SignalType" SG_ 218 FCODPB10P_FVVOTk1PoI1PsVisAuth "ENM";
BA_ "SignalLongName" SG_ 218 FCODPB10P_FVVOTk1PoI1PsVisAuth "Front Camera Object Detection and Processing Burst 10 Protected : Forward Vision Vehicle Object Track 1 Point of Interest 1st Position Visibility Authenticated";
BA_ "SignalType" SG_ 218 FCODPB10P_FVVOTk10PoI3PsVisAuth "ENM";
BA_ "SignalLongName" SG_ 218 FCODPB10P_FVVOTk10PoI3PsVisAuth "Front Camera Object Detection and Processing Burst 10 Protected : Forward Vision Vehicle Object Track 10 Point of Interest 3rd Position Visibility Authenticated";
BA_ "SignalLongName" SG_ 218 FCODPB10P_FVVOTk1PoI2LPsAuth "Front Camera Object Detection and Processing Burst 10 Protected : Forward Vision Vehicle Object Track 1 Point of Interest 2nd Lateral Position Authenticated";
BA_ "SignalLongName" SG_ 218 FCODPB10P_FVVOTk1PoI3LgPsAuth "Front Camera Object Detection and Processing Burst 10 Protected : Forward Vision Vehicle Object Track 1 Point of Interest 3rd Longitudinal Position Authenticated";
BA_ "SignalType" SG_ 218 FCODPB10P_FVVOTk1PoI2PsVisAuth "ENM";
BA_ "SignalLongName" SG_ 218 FCODPB10P_FVVOTk1PoI2PsVisAuth "Front Camera Object Detection and Processing Burst 10 Protected : Forward Vision Vehicle Object Track 1 Point of Interest 2nd Position Visibility Authenticated";
BA_ "SignalLongName" SG_ 218 FCODPB10P_FVVOTk1PoI3LPsAuth "Front Camera Object Detection and Processing Burst 10 Protected : Forward Vision Vehicle Object Track 1 Point of Interest 3rd Lateral Position Authenticated";
BA_ "SignalLongName" SG_ 218 FCODPB10P_FVVOTk2PoI2LgPsAuth "Front Camera Object Detection and Processing Burst 10 Protected : Forward Vision Vehicle Object Track 2 Point of Interest 2nd Longitudinal Position Authenticated";
BA_ "SignalType" SG_ 218 FCODPB10P_FVVOTk2PoI1PsVisAuth "ENM";
BA_ "SignalLongName" SG_ 218 FCODPB10P_FVVOTk2PoI1PsVisAuth "Front Camera Object Detection and Processing Burst 10 Protected : Forward Vision Vehicle Object Track 2 Point of Interest 1st Position Visibility Authenticated";
BA_ "SignalType" SG_ 218 FCODPB10P_FVVOTk1PoI3PsVisAuth "ENM";
BA_ "SignalLongName" SG_ 218 FCODPB10P_FVVOTk1PoI3PsVisAuth "Front Camera Object Detection and Processing Burst 10 Protected : Forward Vision Vehicle Object Track 1 Point of Interest 3rd Position Visibility Authenticated";
BA_ "SignalLongName" SG_ 218 FCODPB10P_FVVOTk2PoI2LPsAuth "Front Camera Object Detection and Processing Burst 10 Protected : Forward Vision Vehicle Object Track 2 Point of Interest 2nd Lateral Position Authenticated";
BA_ "SignalLongName" SG_ 218 FCODPB10P_FVVOTk2PoI3LgPsAuth "Front Camera Object Detection and Processing Burst 10 Protected : Forward Vision Vehicle Object Track 2 Point of Interest 3rd Longitudinal Position Authenticated";
BA_ "SignalType" SG_ 218 FCODPB10P_FVVOTk2PoI2PsVisAuth "ENM";
BA_ "SignalLongName" SG_ 218 FCODPB10P_FVVOTk2PoI2PsVisAuth "Front Camera Object Detection and Processing Burst 10 Protected : Forward Vision Vehicle Object Track 2 Point of Interest 2nd Position Visibility Authenticated";
BA_ "SignalLongName" SG_ 218 FCODPB10P_FVVOTk2PoI3LPsAuth "Front Camera Object Detection and Processing Burst 10 Protected : Forward Vision Vehicle Object Track 2 Point of Interest 3rd Lateral Position Authenticated";
BA_ "SignalLongName" SG_ 218 FCODPB10P_FVVOTk3PoI2LgPsAuth "Front Camera Object Detection and Processing Burst 10 Protected : Forward Vision Vehicle Object Track 3 Point of Interest 2nd Longitudinal Position Authenticated";
BA_ "SignalType" SG_ 218 FCODPB10P_FVVOTk3PoI1PsVisAuth "ENM";
BA_ "SignalLongName" SG_ 218 FCODPB10P_FVVOTk3PoI1PsVisAuth "Front Camera Object Detection and Processing Burst 10 Protected : Forward Vision Vehicle Object Track 3 Point of Interest 1st Position Visibility Authenticated";
BA_ "SignalType" SG_ 218 FCODPB10P_FVVOTk2PoI3PsVisAuth "ENM";
BA_ "SignalLongName" SG_ 218 FCODPB10P_FVVOTk2PoI3PsVisAuth "Front Camera Object Detection and Processing Burst 10 Protected : Forward Vision Vehicle Object Track 2 Point of Interest 3rd Position Visibility Authenticated";
BA_ "SignalLongName" SG_ 218 FCODPB10P_FVVOTk3PoI2LPsAuth "Front Camera Object Detection and Processing Burst 10 Protected : Forward Vision Vehicle Object Track 3 Point of Interest 2nd Lateral Position Authenticated";
BA_ "SignalLongName" SG_ 218 FCODPB10P_FVVOTk3PoI3LgPsAuth "Front Camera Object Detection and Processing Burst 10 Protected : Forward Vision Vehicle Object Track 3 Point of Interest 3rd Longitudinal Position Authenticated";
BA_ "SignalType" SG_ 218 FCODPB10P_FVVOTk3PoI2PsVisAuth "ENM";
BA_ "SignalLongName" SG_ 218 FCODPB10P_FVVOTk3PoI2PsVisAuth "Front Camera Object Detection and Processing Burst 10 Protected : Forward Vision Vehicle Object Track 3 Point of Interest 2nd Position Visibility Authenticated";
BA_ "SignalLongName" SG_ 218 FCODPB10P_FVVOTk3PoI3LPsAuth "Front Camera Object Detection and Processing Burst 10 Protected : Forward Vision Vehicle Object Track 3 Point of Interest 3rd Lateral Position Authenticated";
BA_ "SignalLongName" SG_ 218 FCODPB10P_FVVOTk4PoI2LgPsAuth "Front Camera Object Detection and Processing Burst 10 Protected : Forward Vision Vehicle Object Track 4 Point of Interest 2nd Longitudinal Position Authenticated";
BA_ "SignalType" SG_ 218 FCODPB10P_FVVOTk4PoI1PsVisAuth "ENM";
BA_ "SignalLongName" SG_ 218 FCODPB10P_FVVOTk4PoI1PsVisAuth "Front Camera Object Detection and Processing Burst 10 Protected : Forward Vision Vehicle Object Track 4 Point of Interest 1st Position Visibility Authenticated";
BA_ "SignalType" SG_ 218 FCODPB10P_FVVOTk3PoI3PsVisAuth "ENM";
BA_ "SignalLongName" SG_ 218 FCODPB10P_FVVOTk3PoI3PsVisAuth "Front Camera Object Detection and Processing Burst 10 Protected : Forward Vision Vehicle Object Track 3 Point of Interest 3rd Position Visibility Authenticated";
BA_ "SignalLongName" SG_ 218 FCODPB10P_FVVOTk4PoI2LPsAuth "Front Camera Object Detection and Processing Burst 10 Protected : Forward Vision Vehicle Object Track 4 Point of Interest 2nd Lateral Position Authenticated";
BA_ "SignalLongName" SG_ 218 FCODPB10P_FVVOTk4PoI3LgPsAuth "Front Camera Object Detection and Processing Burst 10 Protected : Forward Vision Vehicle Object Track 4 Point of Interest 3rd Longitudinal Position Authenticated";
BA_ "SignalType" SG_ 218 FCODPB10P_FVVOTk4PoI2PsVisAuth "ENM";
BA_ "SignalLongName" SG_ 218 FCODPB10P_FVVOTk4PoI2PsVisAuth "Front Camera Object Detection and Processing Burst 10 Protected : Forward Vision Vehicle Object Track 4 Point of Interest 2nd Position Visibility Authenticated";
BA_ "SignalLongName" SG_ 218 FCODPB10P_FVVOTk4PoI3LPsAuth "Front Camera Object Detection and Processing Burst 10 Protected : Forward Vision Vehicle Object Track 4 Point of Interest 3rd Lateral Position Authenticated";
BA_ "SignalLongName" SG_ 218 FCODPB10P_FVVOTk5PoI2LgPsAuth "Front Camera Object Detection and Processing Burst 10 Protected : Forward Vision Vehicle Object Track 5 Point of Interest 2nd Longitudinal Position Authenticated";
BA_ "SignalType" SG_ 218 FCODPB10P_FVVOTk5PoI1PsVisAuth "ENM";
BA_ "SignalLongName" SG_ 218 FCODPB10P_FVVOTk5PoI1PsVisAuth "Front Camera Object Detection and Processing Burst 10 Protected : Forward Vision Vehicle Object Track 5 Point of Interest 1st Position Visibility Authenticated";
BA_ "SignalType" SG_ 218 FCODPB10P_FVVOTk4PoI3PsVisAuth "ENM";
BA_ "SignalLongName" SG_ 218 FCODPB10P_FVVOTk4PoI3PsVisAuth "Front Camera Object Detection and Processing Burst 10 Protected : Forward Vision Vehicle Object Track 4 Point of Interest 3rd Position Visibility Authenticated";
BA_ "SignalLongName" SG_ 218 FCODPB10P_FVVOTk5PoI2LPsAuth "Front Camera Object Detection and Processing Burst 10 Protected : Forward Vision Vehicle Object Track 5 Point of Interest 2nd Lateral Position Authenticated";
BA_ "SignalLongName" SG_ 218 FCODPB10P_FVVOTk5PoI3LgPsAuth "Front Camera Object Detection and Processing Burst 10 Protected : Forward Vision Vehicle Object Track 5 Point of Interest 3rd Longitudinal Position Authenticated";
BA_ "SignalType" SG_ 218 FCODPB10P_FVVOTk5PoI2PsVisAuth "ENM";
BA_ "SignalLongName" SG_ 218 FCODPB10P_FVVOTk5PoI2PsVisAuth "Front Camera Object Detection and Processing Burst 10 Protected : Forward Vision Vehicle Object Track 5 Point of Interest 2nd Position Visibility Authenticated";
BA_ "SignalLongName" SG_ 218 FCODPB10P_FVVOTk5PoI3LPsAuth "Front Camera Object Detection and Processing Burst 10 Protected : Forward Vision Vehicle Object Track 5 Point of Interest 3rd Lateral Position Authenticated";
BA_ "SignalLongName" SG_ 218 FCODPB10P_FVVOTk6PoI2LgPsAuth "Front Camera Object Detection and Processing Burst 10 Protected : Forward Vision Vehicle Object Track 6 Point of Interest 2nd Longitudinal Position Authenticated";
BA_ "SignalType" SG_ 218 FCODPB10P_FVVOTk6PoI1PsVisAuth "ENM";
BA_ "SignalLongName" SG_ 218 FCODPB10P_FVVOTk6PoI1PsVisAuth "Front Camera Object Detection and Processing Burst 10 Protected : Forward Vision Vehicle Object Track 6 Point of Interest 1st Position Visibility Authenticated";
BA_ "SignalType" SG_ 218 FCODPB10P_FVVOTk5PoI3PsVisAuth "ENM";
BA_ "SignalLongName" SG_ 218 FCODPB10P_FVVOTk5PoI3PsVisAuth "Front Camera Object Detection and Processing Burst 10 Protected : Forward Vision Vehicle Object Track 5 Point of Interest 3rd Position Visibility Authenticated";
BA_ "SignalLongName" SG_ 218 FCODPB10P_FVVOTk6PoI2LPsAuth "Front Camera Object Detection and Processing Burst 10 Protected : Forward Vision Vehicle Object Track 6 Point of Interest 2nd Lateral Position Authenticated";
BA_ "SignalLongName" SG_ 218 FCODPB10P_FVVOTk6PoI3LgPsAuth "Front Camera Object Detection and Processing Burst 10 Protected : Forward Vision Vehicle Object Track 6 Point of Interest 3rd Longitudinal Position Authenticated";
BA_ "SignalType" SG_ 218 FCODPB10P_FVVOTk6PoI2PsVisAuth "ENM";
BA_ "SignalLongName" SG_ 218 FCODPB10P_FVVOTk6PoI2PsVisAuth "Front Camera Object Detection and Processing Burst 10 Protected : Forward Vision Vehicle Object Track 6 Point of Interest 2nd Position Visibility Authenticated";
BA_ "SignalLongName" SG_ 218 FCODPB10P_FVVOTk6PoI3LPsAuth "Front Camera Object Detection and Processing Burst 10 Protected : Forward Vision Vehicle Object Track 6 Point of Interest 3rd Lateral Position Authenticated";
BA_ "SignalLongName" SG_ 218 FCODPB10P_FVVOTk7PoI2LgPsAuth "Front Camera Object Detection and Processing Burst 10 Protected : Forward Vision Vehicle Object Track 7 Point of Interest 2nd Longitudinal Position Authenticated";
BA_ "SignalType" SG_ 218 FCODPB10P_FVVOTk7PoI1PsVisAuth "ENM";
BA_ "SignalLongName" SG_ 218 FCODPB10P_FVVOTk7PoI1PsVisAuth "Front Camera Object Detection and Processing Burst 10 Protected : Forward Vision Vehicle Object Track 7 Point of Interest 1st Position Visibility Authenticated";
BA_ "SignalType" SG_ 218 FCODPB10P_FVVOTk6PoI3PsVisAuth "ENM";
BA_ "SignalLongName" SG_ 218 FCODPB10P_FVVOTk6PoI3PsVisAuth "Front Camera Object Detection and Processing Burst 10 Protected : Forward Vision Vehicle Object Track 6 Point of Interest 3rd Position Visibility Authenticated";
BA_ "SignalLongName" SG_ 218 FCODPB10P_FVVOTk7PoI2LPsAuth "Front Camera Object Detection and Processing Burst 10 Protected : Forward Vision Vehicle Object Track 7 Point of Interest 2nd Lateral Position Authenticated";
BA_ "SignalLongName" SG_ 218 FCODPB10P_FVVOTk7PoI3LgPsAuth "Front Camera Object Detection and Processing Burst 10 Protected : Forward Vision Vehicle Object Track 7 Point of Interest 3rd Longitudinal Position Authenticated";
BA_ "SignalType" SG_ 218 FCODPB10P_FVVOTk7PoI2PsVisAuth "ENM";
BA_ "SignalLongName" SG_ 218 FCODPB10P_FVVOTk7PoI2PsVisAuth "Front Camera Object Detection and Processing Burst 10 Protected : Forward Vision Vehicle Object Track 7 Point of Interest 2nd Position Visibility Authenticated";
BA_ "SignalLongName" SG_ 218 FCODPB10P_FVVOTk7PoI3LPsAuth "Front Camera Object Detection and Processing Burst 10 Protected : Forward Vision Vehicle Object Track 7 Point of Interest 3rd Lateral Position Authenticated";
BA_ "SignalLongName" SG_ 218 FCODPB10P_FVVOTk8PoI2LgPsAuth "Front Camera Object Detection and Processing Burst 10 Protected : Forward Vision Vehicle Object Track 8 Point of Interest 2nd Longitudinal Position Authenticated";
BA_ "SignalType" SG_ 218 FCODPB10P_FVVOTk8PoI1PsVisAuth "ENM";
BA_ "SignalLongName" SG_ 218 FCODPB10P_FVVOTk8PoI1PsVisAuth "Front Camera Object Detection and Processing Burst 10 Protected : Forward Vision Vehicle Object Track 8 Point of Interest 1st Position Visibility Authenticated";
BA_ "SignalType" SG_ 218 FCODPB10P_FVVOTk7PoI3PsVisAuth "ENM";
BA_ "SignalLongName" SG_ 218 FCODPB10P_FVVOTk7PoI3PsVisAuth "Front Camera Object Detection and Processing Burst 10 Protected : Forward Vision Vehicle Object Track 7 Point of Interest 3rd Position Visibility Authenticated";
BA_ "SignalLongName" SG_ 218 FCODPB10P_FVVOTk8PoI2LPsAuth "Front Camera Object Detection and Processing Burst 10 Protected : Forward Vision Vehicle Object Track 8 Point of Interest 2nd Lateral Position Authenticated";
BA_ "SignalLongName" SG_ 218 FCODPB10P_FVVOTk8PoI3LgPsAuth "Front Camera Object Detection and Processing Burst 10 Protected : Forward Vision Vehicle Object Track 8 Point of Interest 3rd Longitudinal Position Authenticated";
BA_ "SignalType" SG_ 218 FCODPB10P_FVVOTk8PoI2PsVisAuth "ENM";
BA_ "SignalLongName" SG_ 218 FCODPB10P_FVVOTk8PoI2PsVisAuth "Front Camera Object Detection and Processing Burst 10 Protected : Forward Vision Vehicle Object Track 8 Point of Interest 2nd Position Visibility Authenticated";
BA_ "SignalLongName" SG_ 218 FCODPB10P_FVVOTk8PoI3LPsAuth "Front Camera Object Detection and Processing Burst 10 Protected : Forward Vision Vehicle Object Track 8 Point of Interest 3rd Lateral Position Authenticated";
BA_ "SignalLongName" SG_ 218 FCODPB10P_FVVOTk9PoI2LgPsAuth "Front Camera Object Detection and Processing Burst 10 Protected : Forward Vision Vehicle Object Track 9 Point of Interest 2nd Longitudinal Position Authenticated";
BA_ "SignalType" SG_ 218 FCODPB10P_FVVOTk9PoI1PsVisAuth "ENM";
BA_ "SignalLongName" SG_ 218 FCODPB10P_FVVOTk9PoI1PsVisAuth "Front Camera Object Detection and Processing Burst 10 Protected : Forward Vision Vehicle Object Track 9 Point of Interest 1st Position Visibility Authenticated";
BA_ "SignalType" SG_ 218 FCODPB10P_FVVOTk8PoI3PsVisAuth "ENM";
BA_ "SignalLongName" SG_ 218 FCODPB10P_FVVOTk8PoI3PsVisAuth "Front Camera Object Detection and Processing Burst 10 Protected : Forward Vision Vehicle Object Track 8 Point of Interest 3rd Position Visibility Authenticated";
BA_ "SignalLongName" SG_ 218 FCODPB10P_FVVOTk9PoI2LPsAuth "Front Camera Object Detection and Processing Burst 10 Protected : Forward Vision Vehicle Object Track 9 Point of Interest 2nd Lateral Position Authenticated";
BA_ "SignalLongName" SG_ 218 FCODPB10P_FVVOTk9PoI3LgPsAuth "Front Camera Object Detection and Processing Burst 10 Protected : Forward Vision Vehicle Object Track 9 Point of Interest 3rd Longitudinal Position Authenticated";
BA_ "SignalType" SG_ 218 FCODPB10P_FVVOTk9PoI2PsVisAuth "ENM";
BA_ "SignalLongName" SG_ 218 FCODPB10P_FVVOTk9PoI2PsVisAuth "Front Camera Object Detection and Processing Burst 10 Protected : Forward Vision Vehicle Object Track 9 Point of Interest 2nd Position Visibility Authenticated";
BA_ "SignalLongName" SG_ 218 FCODPB10P_FVVOTk9PoI3LPsAuth "Front Camera Object Detection and Processing Burst 10 Protected : Forward Vision Vehicle Object Track 9 Point of Interest 3rd Lateral Position Authenticated";
BA_ "SignalLongName" SG_ 218 FCODPB10P_Filler "Front Camera Object Detection and Processing Burst 10 Protected : Filler";
BA_ "SignalType" SG_ 218 FrwdVsnVehObjTk10DatIntegCkd "ENM";
BA_ "SignalLongName" SG_ 218 FrwdVsnVehObjTk10DatIntegCkd "Front Camera Object Detection and Processing Burst 10 Protected : Forward Vision Vehicle Object Track 10 Data Integrity Checked";
BA_ "SignalType" SG_ 218 FrwdVsnLnBdryTk10DatIntegCkd "ENM";
BA_ "SignalLongName" SG_ 218 FrwdVsnLnBdryTk10DatIntegCkd "Front Camera Object Detection and Processing Burst 10 Protected : Forward Vision Lane Boundary Track 10 Data Integrity Checked";
BA_ "SignalType" SG_ 218 FCODPB10P_FVVOTk9PoI3PsVisAuth "ENM";
BA_ "SignalLongName" SG_ 218 FCODPB10P_FVVOTk9PoI3PsVisAuth "Front Camera Object Detection and Processing Burst 10 Protected : Forward Vision Vehicle Object Track 9 Point of Interest 3rd Position Visibility Authenticated";
BA_ "SignalLongName" SG_ 233 FCODPB1P_MAC "Front Camera Object Detection and Processing Burst 1 Protected : MAC";
BA_ "SignalLongName" SG_ 233 FCODPB1P_FCnt "Front Camera Object Detection and Processing Burst 1 Protected : Freshness Counter";
BA_ "SignalLongName" SG_ 233 FCODPB1P_FVLBTk1CrvAuth "Front Camera Object Detection and Processing Burst 1 Protected : Forward Vision Lane Boundary Track 1 Curvature Authenticated";
BA_ "SignalType" SG_ 233 FCODPB1P_FVLBTk1ClrAuth "ENM";
BA_ "SignalLongName" SG_ 233 FCODPB1P_FVLBTk1ClrAuth "Front Camera Object Detection and Processing Burst 1 Protected : Forward Vision Lane Boundary Track 1 Color Authenticated";
BA_ "SignalLongName" SG_ 233 FCODPB1P_BrstID "Front Camera Object Detection and Processing Burst 1 Protected : Burst ID";
BA_ "SignalLongName" SG_ 233 FCODPB1P_FVLBTk1CrvDrvtAuth "Front Camera Object Detection and Processing Burst 1 Protected : Forward Vision Lane Boundary Track 1 Curvature Derivative Authenticated";
BA_ "SignalLongName" SG_ 233 FCODPB1P_FVLBTk1FPSABCQOvrAuth "Front Camera Object Detection and Processing Burst 1 Protected : Forward Vision Lane Boundary Track 1 First Polynomial Segment ABC Quality Overall Authenticated";
BA_ "SignalLongName" SG_ 233 FCODPB1P_FVLBTk1FPSAQAuth "Front Camera Object Detection and Processing Burst 1 Protected : Forward Vision Lane Boundary Track 1 First Polynomial Segment A Quality Authenticated";
BA_ "SignalLongName" SG_ 233 FCODPB1P_FVLBTk1FPSBQAuth "Front Camera Object Detection and Processing Burst 1 Protected : Forward Vision Lane Boundary Track 1 First Polynomial Segment B Quality Authenticated";
BA_ "SignalLongName" SG_ 233 FCODPB1P_FVLBTk1FPSCQAuth "Front Camera Object Detection and Processing Burst 1 Protected : Forward Vision Lane Boundary Track 1 First Polynomial Segment C Quality Authenticated";
BA_ "SignalLongName" SG_ 233 FCODPB1P_FVLBTk1HdgAuth "Front Camera Object Detection and Processing Burst 1 Protected : Forward Vision Lane Boundary Track 1 Heading Authenticated";
BA_ "SignalLongName" SG_ 233 FCODPB1P_FVLBTk1OfstAuth "Front Camera Object Detection and Processing Burst 1 Protected : Forward Vision Lane Boundary Track 1 Offset Authenticated";
BA_ "SignalType" SG_ 233 FCODPB1P_FVLBTk1PstnTypAuth "ENM";
BA_ "SignalLongName" SG_ 233 FCODPB1P_FVLBTk1PstnTypAuth "Front Camera Object Detection and Processing Burst 1 Protected : Forward Vision Lane Boundary Track 1 Position Type Authenticated";
BA_ "SignalType" SG_ 233 FCODPB1P_FVLBTk1TypAuth "ENM";
BA_ "SignalLongName" SG_ 233 FCODPB1P_FVLBTk1TypAuth "Front Camera Object Detection and Processing Burst 1 Protected : Forward Vision Lane Boundary Track 1 Type Authenticated";
BA_ "SignalType" SG_ 233 FCODPB1P_FVLBTk1QltyAuth "ENM";
BA_ "SignalLongName" SG_ 233 FCODPB1P_FVLBTk1QltyAuth "Front Camera Object Detection and Processing Burst 1 Protected : Forward Vision Lane Boundary Track 1 Quality Authenticated";
BA_ "SignalLongName" SG_ 233 FCODPB1P_FVLBTk1VSLgDistAuth "Front Camera Object Detection and Processing Burst 1 Protected : Forward Vision Lane Boundary Track 1 View Start Longitudinal Distance Authenticated";
BA_ "SignalLongName" SG_ 233 FCODPB1P_FVLBTk1VRLgDistAuth "Front Camera Object Detection and Processing Burst 1 Protected : Forward Vision Lane Boundary Track 1 View Range Longitudinal Distance Authenticated";
BA_ "SignalLongName" SG_ 233 FCODPB1P_FVLBTk1WdthAuth "Front Camera Object Detection and Processing Burst 1 Protected : Forward Vision Lane Boundary Track 1 Width Authenticated";
BA_ "SignalType" SG_ 233 FCODPB1P_FVPOTk1DynPrpAuth "ENM";
BA_ "SignalLongName" SG_ 233 FCODPB1P_FVPOTk1DynPrpAuth "Front Camera Object Detection and Processing Burst 1 Protected : Forward Vision Pedestrian Object Track 1 Dynamic Property Authenticated";
BA_ "SignalType" SG_ 233 FCODPB1P_FVPOTk1CnfdStsAuth "ENM";
BA_ "SignalLongName" SG_ 233 FCODPB1P_FVPOTk1CnfdStsAuth "Front Camera Object Detection and Processing Burst 1 Protected : Forward Vision Pedestrian Object Track 1 Confidence Status Authenticated";
BA_ "SignalLongName" SG_ 233 FCODPB1P_FVPOTk1InPthPotAuth "Front Camera Object Detection and Processing Burst 1 Protected : Forward Vision Pedestrian Object Track 1 In Path Potential Authenticated";
BA_ "SignalLongName" SG_ 233 FCODPB1P_FVPOTk1IDAuth "Front Camera Object Detection and Processing Burst 1 Protected : Forward Vision Pedestrian Object Track 1 ID Authenticated";
BA_ "SignalLongName" SG_ 233 FCODPB1P_FVPOTk1PoILAAuth "Front Camera Object Detection and Processing Burst 1 Protected : Forward Vision Pedestrian Object Track 1 Point of Interest Lateral Acceleration Authenticated";
BA_ "SignalType" SG_ 233 FCODPB1P_FVPOTk1MStsAuth "ENM";
BA_ "SignalLongName" SG_ 233 FCODPB1P_FVPOTk1MStsAuth "Front Camera Object Detection and Processing Burst 1 Protected : Forward Vision Pedestrian Object Track 1 Measurement Status Authenticated";
BA_ "SignalLongName" SG_ 233 FCODPB1P_FVPOTk1PoILgAAuth "Front Camera Object Detection and Processing Burst 1 Protected : Forward Vision Pedestrian Object Track 1 Point of Interest Longitudinal Acceleration Authenticated";
BA_ "SignalLongName" SG_ 233 FCODPB1P_FVPOTk1PoILgPsAuth "Front Camera Object Detection and Processing Burst 1 Protected : Forward Vision Pedestrian Object Track 1 Point of Interest Longitudinal Position Authenticated";
BA_ "SignalLongName" SG_ 233 FCODPB1P_FVPOTk1PoILgVAuth "Front Camera Object Detection and Processing Burst 1 Protected : Forward Vision Pedestrian Object Track 1 Point of Interest Longitudinal Velocity Authenticated";
BA_ "SignalLongName" SG_ 233 FCODPB1P_FVPOTk1PoILPsAuth "Front Camera Object Detection and Processing Burst 1 Protected : Forward Vision Pedestrian Object Track 1 Point of Interest Lateral Position Authenticated";
BA_ "SignalLongName" SG_ 233 FCODPB1P_FVPOTk1PoILVAuth "Front Camera Object Detection and Processing Burst 1 Protected : Forward Vision Pedestrian Object Track 1 Point of Interest Lateral Velocity Authenticated";
BA_ "SignalLongName" SG_ 233 FCODPB1P_FVVOTk1CICOPotAuth "Front Camera Object Detection and Processing Burst 1 Protected : Forward Vision Vehicle Object Track 1 Cut In Cut Out Potential Authenticated";
BA_ "SignalType" SG_ 233 FCODPB1P_FVVOTk1BrkLgtStsAuth "ENM";
BA_ "SignalLongName" SG_ 233 FCODPB1P_FVVOTk1BrkLgtStsAuth "Front Camera Object Detection and Processing Burst 1 Protected : Forward Vision Vehicle Object Track 1 Brake Light Status Authenticated";
BA_ "SignalType" SG_ 233 FCODPB1P_FVPOTk1TypCnfdAuth "ENM";
BA_ "SignalLongName" SG_ 233 FCODPB1P_FVPOTk1TypCnfdAuth "Front Camera Object Detection and Processing Burst 1 Protected : Forward Vision Pedestrian Object Track 1 Type Confidence Authenticated";
BA_ "SignalType" SG_ 233 FCODPB1P_FVPOTk1TypAuth "ENM";
BA_ "SignalLongName" SG_ 233 FCODPB1P_FVPOTk1TypAuth "Front Camera Object Detection and Processing Burst 1 Protected : Forward Vision Pedestrian Object Track 1 Type Authenticated";
BA_ "SignalType" SG_ 233 FCODPB1P_FVVOTk1DynPrpAuth "ENM";
BA_ "SignalLongName" SG_ 233 FCODPB1P_FVVOTk1DynPrpAuth "Front Camera Object Detection and Processing Burst 1 Protected : Forward Vision Vehicle Object Track 1 Dynamic Property Authenticated";
BA_ "SignalType" SG_ 233 FCODPB1P_FVVOTk1CnfdStsAuth "ENM";
BA_ "SignalLongName" SG_ 233 FCODPB1P_FVVOTk1CnfdStsAuth "Front Camera Object Detection and Processing Burst 1 Protected : Forward Vision Vehicle Object Track 1 Confidence Status Authenticated";
BA_ "SignalLongName" SG_ 233 FCODPB1P_FVVOTk1HdgAngAuth "Front Camera Object Detection and Processing Burst 1 Protected : Forward Vision Vehicle Object Track 1 Heading Angle Authenticated";
BA_ "SignalType" SG_ 233 FCODPB1P_FVVOTk1DynPrpStsAuth "ENM";
BA_ "SignalLongName" SG_ 233 FCODPB1P_FVVOTk1DynPrpStsAuth "Front Camera Object Detection and Processing Burst 1 Protected : Forward Vision Vehicle Object Track 1 Dynamic Property Status Authenticated";
BA_ "SignalLongName" SG_ 233 FCODPB1P_FVVOTk1HdgAngCAuth "Front Camera Object Detection and Processing Burst 1 Protected : Forward Vision Vehicle Object Track 1 Heading Angle Covariance Authenticated";
BA_ "SignalLongName" SG_ 233 FCODPB1P_FVVOTk1IDAuth "Front Camera Object Detection and Processing Burst 1 Protected : Forward Vision Vehicle Object Track 1 ID Authenticated";
BA_ "SignalLongName" SG_ 233 FCODPB1P_FVVOTk1PoILAAuth "Front Camera Object Detection and Processing Burst 1 Protected : Forward Vision Vehicle Object Track 1 Point of Interest Lateral Acceleration Authenticated";
BA_ "SignalType" SG_ 233 FCODPB1P_FVVOTk1MStsAuth "ENM";
BA_ "SignalLongName" SG_ 233 FCODPB1P_FVVOTk1MStsAuth "Front Camera Object Detection and Processing Burst 1 Protected : Forward Vision Vehicle Object Track 1 Measurement Status Authenticated";
BA_ "SignalType" SG_ 233 FCODPB1P_FVVOTk1LnAsmtAuth "ENM";
BA_ "SignalLongName" SG_ 233 FCODPB1P_FVVOTk1LnAsmtAuth "Front Camera Object Detection and Processing Burst 1 Protected : Forward Vision Vehicle Object Track 1 Lane Assignment Authenticated";
BA_ "SignalLongName" SG_ 233 FCODPB1P_FVVOTk1PoILgAAuth "Front Camera Object Detection and Processing Burst 1 Protected : Forward Vision Vehicle Object Track 1 Point of Interest Longitudinal Acceleration Authenticated";
BA_ "SignalLongName" SG_ 233 FCODPB1P_FVVOTk1PoILgPsAuth "Front Camera Object Detection and Processing Burst 1 Protected : Forward Vision Vehicle Object Track 1 Point of Interest Longitudinal Position Authenticated";
BA_ "SignalLongName" SG_ 233 FCODPB1P_FVVOTk1PoILgPsCAuth "Front Camera Object Detection and Processing Burst 1 Protected : Forward Vision Vehicle Object Track 1 Point of Interest Longitudinal Position Covariance Authenticated";
BA_ "SignalLongName" SG_ 233 FCODPB1P_FVVOTk1PoILgVAuth "Front Camera Object Detection and Processing Burst 1 Protected : Forward Vision Vehicle Object Track 1 Point of Interest Longitudinal Velocity Authenticated";
BA_ "SignalLongName" SG_ 233 FCODPB1P_FVVOTk1PoILgVCAuth "Front Camera Object Detection and Processing Burst 1 Protected : Forward Vision Vehicle Object Track 1 Point of Interest Longitudinal Velocity Covariance Authenticated";
BA_ "SignalLongName" SG_ 233 FCODPB1P_FVVOTk1PoILPsAuth "Front Camera Object Detection and Processing Burst 1 Protected : Forward Vision Vehicle Object Track 1 Point of Interest Lateral Position Authenticated";
BA_ "SignalLongName" SG_ 233 FCODPB1P_FVVOTk1PoILPsCAuth "Front Camera Object Detection and Processing Burst 1 Protected : Forward Vision Vehicle Object Track 1 Point of Interest Lateral Position Covariance Authenticated";
BA_ "SignalLongName" SG_ 233 FCODPB1P_FVVOTk1PoILVAuth "Front Camera Object Detection and Processing Burst 1 Protected : Forward Vision Vehicle Object Track 1 Point of Interest Lateral Velocity Authenticated";
BA_ "SignalLongName" SG_ 233 FCODPB1P_FVVOTk1PoILVCAuth "Front Camera Object Detection and Processing Burst 1 Protected : Forward Vision Vehicle Object Track 1 Point of Interest Lateral Velocity Covariance Authenticated";
BA_ "SignalLongName" SG_ 233 FCODPB1P_FVVOTk1PoIWAuth "Front Camera Object Detection and Processing Burst 1 Protected : Forward Vision Vehicle Object Track 1 Point of Interest Width Authenticated";
BA_ "SignalType" SG_ 233 FCODPB1P_FVVOTk1TypCnfdAuth "ENM";
BA_ "SignalLongName" SG_ 233 FCODPB1P_FVVOTk1TypCnfdAuth "Front Camera Object Detection and Processing Burst 1 Protected : Forward Vision Vehicle Object Track 1 Type Confidence Authenticated";
BA_ "SignalType" SG_ 233 FCODPB1P_FVVOTk1TypAuth "ENM";
BA_ "SignalLongName" SG_ 233 FCODPB1P_FVVOTk1TypAuth "Front Camera Object Detection and Processing Burst 1 Protected : Forward Vision Vehicle Object Track 1 Type Authenticated";
BA_ "SignalType" SG_ 233 FCODPB1P_FVVOTk1TSLgtStsAuth "ENM";
BA_ "SignalLongName" SG_ 233 FCODPB1P_FVVOTk1TSLgtStsAuth "Front Camera Object Detection and Processing Burst 1 Protected : Forward Vision Vehicle Object Track 1 Turn Signal Light Status Authenticated";
BA_ "SignalLongName" SG_ 233 FCODPB1P_FVVOTk10VehLnCrsTmAuth "Front Camera Object Detection and Processing Burst 1 Protected : Forward Vision Vehicle Object Track 10 Vehicle Lane Cross Time Authenticated";
BA_ "SignalLongName" SG_ 233 FCODPB1P_ARC "Front Camera Object Detection and Processing Burst 1 Protected : Alive Rolling Count";
BA_ "SignalLongName" SG_ 233 FCODPB1P_FVVOTk1VehLnCrsTmAuth "Front Camera Object Detection and Processing Burst 1 Protected : Forward Vision Vehicle Object Track 1 Vehicle Lane Cross Time Authenticated";
BA_ "SignalLongName" SG_ 233 FCODPB1P_FVVOTk2VehLnCrsTmAuth "Front Camera Object Detection and Processing Burst 1 Protected : Forward Vision Vehicle Object Track 2 Vehicle Lane Cross Time Authenticated";
BA_ "SignalLongName" SG_ 233 FCODPB1P_FVVOTk3VehLnCrsTmAuth "Front Camera Object Detection and Processing Burst 1 Protected : Forward Vision Vehicle Object Track 3 Vehicle Lane Cross Time Authenticated";
BA_ "SignalLongName" SG_ 233 FCODPB1P_FVVOTk4VehLnCrsTmAuth "Front Camera Object Detection and Processing Burst 1 Protected : Forward Vision Vehicle Object Track 4 Vehicle Lane Cross Time Authenticated";
BA_ "SignalLongName" SG_ 233 FCODPB1P_FVVOTk5VehLnCrsTmAuth "Front Camera Object Detection and Processing Burst 1 Protected : Forward Vision Vehicle Object Track 5 Vehicle Lane Cross Time Authenticated";
BA_ "SignalLongName" SG_ 233 FCODPB1P_FVVOTk6VehLnCrsTmAuth "Front Camera Object Detection and Processing Burst 1 Protected : Forward Vision Vehicle Object Track 6 Vehicle Lane Cross Time Authenticated";
BA_ "SignalLongName" SG_ 233 FCODPB1P_FVVOTk7VehLnCrsTmAuth "Front Camera Object Detection and Processing Burst 1 Protected : Forward Vision Vehicle Object Track 7 Vehicle Lane Cross Time Authenticated";
BA_ "SignalLongName" SG_ 233 FCODPB1P_FVVOTk8VehLnCrsTmAuth "Front Camera Object Detection and Processing Burst 1 Protected : Forward Vision Vehicle Object Track 8 Vehicle Lane Cross Time Authenticated";
BA_ "SignalLongName" SG_ 233 FCODPB1P_FVVOTk9VehLnCrsTmAuth "Front Camera Object Detection and Processing Burst 1 Protected : Forward Vision Vehicle Object Track 9 Vehicle Lane Cross Time Authenticated";
BA_ "SignalType" SG_ 233 FrwdVsnPedtrnObjTk1DatIntegCkd "ENM";
BA_ "SignalLongName" SG_ 233 FrwdVsnPedtrnObjTk1DatIntegCkd "Front Camera Object Detection and Processing Burst 1 Protected : Forward Vision Pedestrian Object Track 1 Data Integrity Checked";
BA_ "SignalType" SG_ 233 FrwdVsnLnBdryTk1DatIntegCkd "ENM";
BA_ "SignalLongName" SG_ 233 FrwdVsnLnBdryTk1DatIntegCkd "Front Camera Object Detection and Processing Burst 1 Protected : Forward Vision Lane Boundary Track 1 Data Integrity Checked";
BA_ "SignalLongName" SG_ 233 FCODPB1P_Filler "Front Camera Object Detection and Processing Burst 1 Protected : Filler";
BA_ "SignalType" SG_ 233 FrwdVsnVehObjTk1DatIntegCkd "ENM";
BA_ "SignalLongName" SG_ 233 FrwdVsnVehObjTk1DatIntegCkd "Front Camera Object Detection and Processing Burst 1 Protected : Forward Vision Vehicle Object Track 1 Data Integrity Checked";
BA_ "SignalLongName" SG_ 240 FCODPB15P_CnstrObj10LngDistAuth "Front Camera Object Detection and Processing Burst 15 Protected : Construction Object 10 Longitudinal Distance Authenticated";
BA_ "SignalLongName" SG_ 240 FCODPB15P_BrstID "Front Camera Object Detection and Processing Burst 15 Protected : Burst ID";
BA_ "SignalLongName" SG_ 240 FCODPB15P_CnstrObj11LngDistAuth "Front Camera Object Detection and Processing Burst 15 Protected : Construction Object 11 Longitudinal Distance Authenticated";
BA_ "SignalLongName" SG_ 240 FCODPB15P_CnstrObj12LngDistAuth "Front Camera Object Detection and Processing Burst 15 Protected : Construction Object 12 Longitudinal Distance Authenticated";
BA_ "SignalLongName" SG_ 240 FCODPB15P_CnstrObj13LngDistAuth "Front Camera Object Detection and Processing Burst 15 Protected : Construction Object 13 Longitudinal Distance Authenticated";
BA_ "SignalLongName" SG_ 240 FCODPB15P_CnstrObj14LngDistAuth "Front Camera Object Detection and Processing Burst 15 Protected : Construction Object 14 Longitudinal Distance Authenticated";
BA_ "SignalLongName" SG_ 240 FCODPB15P_CnstrObj15LngDistAuth "Front Camera Object Detection and Processing Burst 15 Protected : Construction Object 15 Longitudinal Distance Authenticated";
BA_ "SignalLongName" SG_ 240 FCODPB15P_CnstrObj1LngDistAuth "Front Camera Object Detection and Processing Burst 15 Protected : Construction Object 1 Longitudinal Distance Authenticated";
BA_ "SignalLongName" SG_ 240 FCODPB15P_CnstrObj2LngDistAuth "Front Camera Object Detection and Processing Burst 15 Protected : Construction Object 2 Longitudinal Distance Authenticated";
BA_ "SignalLongName" SG_ 240 FCODPB15P_CnstrObj3LngDistAuth "Front Camera Object Detection and Processing Burst 15 Protected : Construction Object 3 Longitudinal Distance Authenticated";
BA_ "SignalLongName" SG_ 240 FCODPB15P_CnstrObj4LngDistAuth "Front Camera Object Detection and Processing Burst 15 Protected : Construction Object 4 Longitudinal Distance Authenticated";
BA_ "SignalLongName" SG_ 240 FCODPB15P_CnstrObj5LngDistAuth "Front Camera Object Detection and Processing Burst 15 Protected : Construction Object 5 Longitudinal Distance Authenticated";
BA_ "SignalLongName" SG_ 240 FCODPB15P_CnstrObj6LngDistAuth "Front Camera Object Detection and Processing Burst 15 Protected : Construction Object 6 Longitudinal Distance Authenticated";
BA_ "SignalLongName" SG_ 240 FCODPB15P_CnstrObj7LngDistAuth "Front Camera Object Detection and Processing Burst 15 Protected : Construction Object 7 Longitudinal Distance Authenticated";
BA_ "SignalLongName" SG_ 240 FCODPB15P_CnstrObj8LngDistAuth "Front Camera Object Detection and Processing Burst 15 Protected : Construction Object 8 Longitudinal Distance Authenticated";
BA_ "SignalLongName" SG_ 240 FCODPB15P_CnstrObj9LngDistAuth "Front Camera Object Detection and Processing Burst 15 Protected : Construction Object 9 Longitudinal Distance Authenticated";
BA_ "SignalLongName" SG_ 240 FCODPB15P_Filler "Front Camera Object Detection and Processing Burst 15 Protected : Filler";
BA_ "SignalLongName" SG_ 718 GPSC_PPSLat "Global Positioning System Coordinates : Precise Positioning System Latitude";
BA_ "SignalLongName" SG_ 718 GPSC_PPSLong "Global Positioning System Coordinates : Precise Positioning System Longitude";
BA_ "SignalType" SG_ 718 GPSC_PPSLat_Inv "ENM";
BA_ "SignalLongName" SG_ 718 GPSC_PPSLat_Inv "Global Positioning System Coordinates : Precise Positioning System Latitude Invalid";
BA_ "SignalType" SG_ 718 GPSC_PPSLong_Inv "ENM";
BA_ "SignalLongName" SG_ 718 GPSC_PPSLong_Inv "Global Positioning System Coordinates : Precise Positioning System Longitude Invalid";
BA_ "SignalType" SG_ 2147745810 HDLM_CAN8_ClscCANHrtBtActv "ENM";
BA_ "SignalLongName" SG_ 2147745810 HDLM_CAN8_ClscCANHrtBtActv "HDLM CAN 8 Classic CAN Heart Beat Active";
BA_ "SignalLongName" SG_ 914 HstVehPathParms_PCSM "Host Vehicle Path Parameters Protected Counter Sync Message";
BA_ "SignalLongName" SG_ 87 HVPPP_MAC "Host Vehicle Path Parameters Protected : MAC";
BA_ "SignalLongName" SG_ 87 HVPPP_FCnt "Host Vehicle Path Parameters Protected : Freshness Counter";
BA_ "SignalLongName" SG_ 87 HVPPP_HstVehLatVelAuth "Host Vehicle Path Parameters Protected : Host Vehicle Lateral Velocity Authenticated";
BA_ "SignalType" SG_ 87 HVPPP_FrwdVsnModeCmdAuth "ENM";
BA_ "SignalLongName" SG_ 87 HVPPP_FrwdVsnModeCmdAuth "Host Vehicle Path Parameters Protected : Forward Vision Mode Command Authenticated";
BA_ "SignalLongName" SG_ 87 HVPPP_HstVehLngVelAuth "Host Vehicle Path Parameters Protected : Host Vehicle Longitudinal Velocity Authenticated";
BA_ "SignalType" SG_ 87 HVPPP_HstVehLatVelAuth_Inv "ENM";
BA_ "SignalLongName" SG_ 87 HVPPP_HstVehLatVelAuth_Inv "Host Vehicle Path Parameters Protected : Host Vehicle Lateral Velocity Authenticated Invalid";
BA_ "SignalLongName" SG_ 87 HVPPP_HstVehPathCrvAuth "Host Vehicle Path Parameters Protected : Host Vehicle Path Curvature Authenticated";
BA_ "SignalType" SG_ 87 HVPPP_HstVehLngVelAuth_Inv "ENM";
BA_ "SignalLongName" SG_ 87 HVPPP_HstVehLngVelAuth_Inv "Host Vehicle Path Parameters Protected : Host Vehicle Longitudinal Velocity Authenticated Invalid";
BA_ "SignalLongName" SG_ 87 HVPPP_HstVehPathCrvDrvtAuth "Host Vehicle Path Parameters Protected : Host Vehicle Path Curvature Derivative Authenticated";
BA_ "SignalType" SG_ 87 HVPPP_HstVehPathModeAuth "ENM";
BA_ "SignalLongName" SG_ 87 HVPPP_HstVehPathModeAuth "Host Vehicle Path Parameters Protected : Host Vehicle Path Mode Authenticated";
BA_ "SignalLongName" SG_ 87 HVPPP_HstVehSdslAngAuth "Host Vehicle Path Parameters Protected : Host Vehicle Sideslip Angle Authenticated";
BA_ "SignalLongName" SG_ 87 HVPPP_HstVehTrnCntrLatOfstAuth "Host Vehicle Path Parameters Protected : Host Vehicle Turn Center Lateral Offset Authenticated";
BA_ "SignalLongName" SG_ 87 HVPPP_HstVehTrnCntrLngOfstAuth "Host Vehicle Path Parameters Protected : Host Vehicle Turn Center Longitudinal Offset Authenticated";
BA_ "SignalLongName" SG_ 87 HVPPP_HstVehVelAuth "Host Vehicle Path Parameters Protected : Host Vehicle Velocity Authenticated";
BA_ "SignalType" SG_ 87 HVPPP_HstVehTrvlDirAuth "ENM";
BA_ "SignalLongName" SG_ 87 HVPPP_HstVehTrvlDirAuth "Host Vehicle Path Parameters Protected : Host Vehicle Travel Direction Authenticated";
BA_ "SignalLongName" SG_ 87 HVPPP_HstVehYawRateAuth "Host Vehicle Path Parameters Protected : Host Vehicle Yaw Rate Authenticated";
BA_ "SignalType" SG_ 87 HVPPP_HstVehVelAuth_Inv "ENM";
BA_ "SignalLongName" SG_ 87 HVPPP_HstVehVelAuth_Inv "Host Vehicle Path Parameters Protected : Host Vehicle Velocity Authenticated Invalid";
BA_ "SignalType" SG_ 87 HVPPP_LngRngRadarModeCmdAuth "ENM";
BA_ "SignalLongName" SG_ 87 HVPPP_LngRngRadarModeCmdAuth "Host Vehicle Path Parameters Protected : Long Range Radar Mode Command Authenticated";
BA_ "SignalType" SG_ 87 HVPPP_HstVehYawRateAuth_Inv "ENM";
BA_ "SignalLongName" SG_ 87 HVPPP_HstVehYawRateAuth_Inv "Host Vehicle Path Parameters Protected : Host Vehicle Yaw Rate Authenticated Invalid";
BA_ "SignalLongName" SG_ 87 HVPPP_ObjSnsrTmSyncMstrClckAuth "Host Vehicle Path Parameters Protected : Object Sensor Time Sync Master Clock Authenticated";
BA_ "SignalLongName" SG_ 87 HVPPP_ARC "Host Vehicle Path Parameters Protected : Alive Rolling Count";
BA_ "SignalType" SG_ 87 HVPPP_ShrtRngRadarModeCmdAuth "ENM";
BA_ "SignalLongName" SG_ 87 HVPPP_ShrtRngRadarModeCmdAuth "Host Vehicle Path Parameters Protected : Short Range Radar Mode Command Authenticated";
BA_ "SignalType" SG_ 87 HVPPP_ObjsRetndRrwdSnsrsAuth "ENM";
BA_ "SignalLongName" SG_ 87 HVPPP_ObjsRetndRrwdSnsrsAuth "Host Vehicle Path Parameters Protected : Objects Returned from Rearward Sensors Authenticated";
BA_ "SignalType" SG_ 87 HVPPP_ObjsRetndFrwdSnsrsAuth "ENM";
BA_ "SignalLongName" SG_ 87 HVPPP_ObjsRetndFrwdSnsrsAuth "Host Vehicle Path Parameters Protected : Objects Returned from Forward Sensors Authenticated";
BA_ "SignalLongName" SG_ 87 HstVehRideHghtOfst "Host Vehicle Path Parameters Protected : Host Vehicle Ride Height Offset";
BA_ "SignalType" SG_ 87 DrvrMonSysModeCmd "ENM";
BA_ "SignalLongName" SG_ 87 DrvrMonSysModeCmd "Host Vehicle Path Parameters Protected : Driver Monitoring System Mode Command";
BA_ "SignalType" SG_ 87 LnFllwgFtrStatAuth "ENM";
BA_ "SignalLongName" SG_ 87 LnFllwgFtrStatAuth "Host Vehicle Path Parameters Protected : Lane Following Feature State Authenticated";
BA_ "SignalType" SG_ 87 HstVehRideHghtOfst_Inv "ENM";
BA_ "SignalLongName" SG_ 87 HstVehRideHghtOfst_Inv "Host Vehicle Path Parameters Protected : Host Vehicle Ride Height Offset Invalid";
BA_ "SignalLongName" SG_ 87 HstVehFrtRdWhlAng "Host Vehicle Path Parameters Protected : Host Vehicle Front Road Wheel Angle";
BA_ "SignalType" SG_ 87 HstVehRideHghtOfstSts "ENM";
BA_ "SignalLongName" SG_ 87 HstVehRideHghtOfstSts "Host Vehicle Path Parameters Protected : Host Vehicle Ride Height Offset Status";
BA_ "SignalLongName" SG_ 87 HVPPP_Filler "Host Vehicle Path Parameters Protected : Filler";
BA_ "SignalType" SG_ 87 GeofncngRstrctdZnStsGtd "ENM";
BA_ "SignalLongName" SG_ 87 GeofncngRstrctdZnStsGtd "Host Vehicle Path Parameters Protected : Geofencing Restricted Zone Status Gated";
BA_ "SignalType" SG_ 87 HstVehFrtRdWhlAng_Inv "ENM";
BA_ "SignalLongName" SG_ 87 HstVehFrtRdWhlAng_Inv "Host Vehicle Path Parameters Protected : Host Vehicle Front Road Wheel Angle Invalid";
BA_ "SignalLongName" SG_ 87 HVPPP_FillerExtnd "Host Vehicle Path Parameters Protected : Filler Extended";
BA_ "SignalLongName" SG_ 687 HstVehPthParms_BrstGrp1_PCSM "Host Vehicle Path Parameters Burst Group Protected Counter Sync Message";
BA_ "SignalLongName" SG_ 109 HVPPBG1P_MAC "Host Vehicle Path Parameters Burst Group 1 Protected : MAC";
BA_ "SignalLongName" SG_ 109 HVPPBG1P_FCnt "Host Vehicle Path Parameters Burst Group 1 Protected : Freshness Counter";
BA_ "SignalLongName" SG_ 109 HVPPBG1P_HstVehLatVelAuth "Host Vehicle Path Parameters Burst Group 1 Protected : Host Vehicle Lateral Velocity Authenticated";
BA_ "SignalLongName" SG_ 109 HVPPBG1P_BrstID "Host Vehicle Path Parameters Burst Group 1 Protected : Burst ID";
BA_ "SignalLongName" SG_ 109 HVPPBG1P_HstVehLngVelAuth "Host Vehicle Path Parameters Burst Group 1 Protected : Host Vehicle Longitudinal Velocity Authenticated";
BA_ "SignalLongName" SG_ 109 HVPPBG1P_ARC "Host Vehicle Path Parameters Burst Group 1 Protected : Alive Rolling Count";
BA_ "SignalLongName" SG_ 38 HVPPBG2P_HstVehYawRateAuth "Host Vehicle Path Parameters Burst Group 2 Protected : Host Vehicle Yaw Rate Authenticated";
BA_ "SignalType" SG_ 38 HVPPBG2P_HstVehTrvlDirAuth "ENM";
BA_ "SignalLongName" SG_ 38 HVPPBG2P_HstVehTrvlDirAuth "Host Vehicle Path Parameters Burst Group 2 Protected : Host Vehicle Travel Direction Authenticated";
BA_ "SignalLongName" SG_ 38 HVPPBG2P_BrstID "Host Vehicle Path Parameters Burst Group 2 Protected : Burst ID";
BA_ "SignalLongName" SG_ 38 HVPPBG2P_HstVehRideHghtOfst "Host Vehicle Path Parameters Burst Group 2 Protected : Host Vehicle Ride Height Offset";
BA_ "SignalLongName" SG_ 38 HVPPBG2P_Filler "Host Vehicle Path Parameters Burst Group 2 Protected : Filler";
BA_ "SignalType" SG_ 38 HVPPBG2P_HstVehRideHghtOfstSts "ENM";
BA_ "SignalLongName" SG_ 38 HVPPBG2P_HstVehRideHghtOfstSts "Host Vehicle Path Parameters Burst Group 2 Protected : Host Vehicle Ride Height Offset Status";
BA_ "SignalType" SG_ 38 HVPPBG2P_HstVehRideHghtOfst_Inv "ENM";
BA_ "SignalLongName" SG_ 38 HVPPBG2P_HstVehRideHghtOfst_Inv "Host Vehicle Path Parameters Burst Group 2 Protected : Host Vehicle Ride Height Offset Invalid";
BA_ "SignalLongName" SG_ 38 HVPPBG2P_FillerExtnd "Host Vehicle Path Parameters Burst Group 2 Protected : Filler Extended";
BA_ "SignalType" SG_ 1419 SBZAlrtCstAvlFlg7 "ENM";
BA_ "SignalLongName" SG_ 1419 SBZAlrtCstAvlFlg7 "Side Blind Zone Alert Customization Availability Flag 7";
BA_ "SignalType" SG_ 1419 SBZAlrtCstAvlFlg6 "ENM";
BA_ "SignalLongName" SG_ 1419 SBZAlrtCstAvlFlg6 "Side Blind Zone Alert Customization Availability Flag 6";
BA_ "SignalType" SG_ 1419 SBZAlrtCstAvlFlg5 "ENM";
BA_ "SignalLongName" SG_ 1419 SBZAlrtCstAvlFlg5 "Side Blind Zone Alert Customization Availability Flag 5";
BA_ "SignalType" SG_ 1419 SBZAlrtCstAvlFlg4 "ENM";
BA_ "SignalLongName" SG_ 1419 SBZAlrtCstAvlFlg4 "Side Blind Zone Alert Customization Availability Flag 4";
BA_ "SignalType" SG_ 1419 SBZAlrtCstAvlFlg3 "ENM";
BA_ "SignalLongName" SG_ 1419 SBZAlrtCstAvlFlg3 "Side Blind Zone Alert Customization Availability Flag 3";
BA_ "SignalType" SG_ 1419 SBZAlrtCstAvlFlg2 "ENM";
BA_ "SignalLongName" SG_ 1419 SBZAlrtCstAvlFlg2 "Side Blind Zone Alert Customization Availability Flag 2";
BA_ "SignalType" SG_ 1419 SBZAlrtCstAvlFlg1 "ENM";
BA_ "SignalLongName" SG_ 1419 SBZAlrtCstAvlFlg1 "Side Blind Zone Alert Customization Availability Flag 1";
BA_ "SignalType" SG_ 1419 LnChgAlrtLmtdTrlrIndOn "ENM";
BA_ "SignalLongName" SG_ 1419 LnChgAlrtLmtdTrlrIndOn "Lane Change Alert Limited by Trailer Indication On";
BA_ "SignalType" SG_ 1419 ServSdDtcSysIndOn "ENM";
BA_ "SignalLongName" SG_ 1419 ServSdDtcSysIndOn "Service Side Detection System Indication On";
BA_ "SignalType" SG_ 1419 SdDtcTempUnvIndOn "ENM";
BA_ "SignalLongName" SG_ 1419 SdDtcTempUnvIndOn "Side Detection Temporarily Unavailable Indication On";
BA_ "SignalType" SG_ 1419 SBZAlrtOffIndOn "ENM";
BA_ "SignalLongName" SG_ 1419 SBZAlrtOffIndOn "Side Blind Zone Alert Off Indication On";
BA_ "SignalType" SG_ 1419 SBZAlrtCstStAvl "ENM";
BA_ "SignalLongName" SG_ 1419 SBZAlrtCstStAvl "Side Blind Zone Alert Customization Setting Available";
BA_ "SignalType" SG_ 1408 TrffcLgtAsstWrnChmEvntStat "ENM";
BA_ "SignalLongName" SG_ 1408 TrffcLgtAsstWrnChmEvntStat "Traffic Light Assist Warning Chime Event State";
BA_ "SignalType" SG_ 1408 TrffcLgtAsstCstCurrSetVal "ENM";
BA_ "SignalLongName" SG_ 1408 TrffcLgtAsstCstCurrSetVal "Traffic Light Assist Customization Current Setting Value";
BA_ "SignalType" SG_ 1408 GlrFrHgBmRspTypCstCurSetVal "ENM";
BA_ "SignalLongName" SG_ 1408 GlrFrHgBmRspTypCstCurSetVal "Glare Free High Beam Response Type Customization Current Setting Value";
BA_ "SignalType" SG_ 1408 GlrFrHgBmRspTypCstAvlFlg7 "ENM";
BA_ "SignalLongName" SG_ 1408 GlrFrHgBmRspTypCstAvlFlg7 "Glare Free High Beam Response Type Customization Availability Flag7";
BA_ "SignalType" SG_ 1408 GlrFrHgBmRspTypCstAvlFlg6 "ENM";
BA_ "SignalLongName" SG_ 1408 GlrFrHgBmRspTypCstAvlFlg6 "Glare Free High Beam Response Type Customization Availability Flag6";
BA_ "SignalType" SG_ 1408 GlrFrHgBmRspTypCstAvlFlg5 "ENM";
BA_ "SignalLongName" SG_ 1408 GlrFrHgBmRspTypCstAvlFlg5 "Glare Free High Beam Response Type Customization Availability Flag5";
BA_ "SignalType" SG_ 1408 GlrFrHgBmRspTypCstAvlFlg4 "ENM";
BA_ "SignalLongName" SG_ 1408 GlrFrHgBmRspTypCstAvlFlg4 "Glare Free High Beam Response Type Customization Availability Flag4";
BA_ "SignalType" SG_ 1408 GlrFrHgBmRspTypCstAvlFlg3 "ENM";
BA_ "SignalLongName" SG_ 1408 GlrFrHgBmRspTypCstAvlFlg3 "Glare Free High Beam Response Type Customization Availability Flag3";
BA_ "SignalType" SG_ 1408 GlrFrHgBmRspTypCstAvlFlg2 "ENM";
BA_ "SignalLongName" SG_ 1408 GlrFrHgBmRspTypCstAvlFlg2 "Glare Free High Beam Response Type Customization Availability Flag2";
BA_ "SignalType" SG_ 1408 GlrFrHgBmRspTypCstAvlFlg1 "ENM";
BA_ "SignalLongName" SG_ 1408 GlrFrHgBmRspTypCstAvlFlg1 "Glare Free High Beam Response Type Customization Availability Flag1";
BA_ "SignalType" SG_ 1408 AutoHgBmCtrlIO "ENM";
BA_ "SignalLongName" SG_ 1408 AutoHgBmCtrlIO "Auto High Beam Control Indication On";
BA_ "SignalType" SG_ 1408 TrffcLgtAsstCstAvlFlg7 "ENM";
BA_ "SignalLongName" SG_ 1408 TrffcLgtAsstCstAvlFlg7 "Traffic Light Assist Customization Availability Flag 7";
BA_ "SignalType" SG_ 1408 TrffcLgtAsstCstAvlFlg6 "ENM";
BA_ "SignalLongName" SG_ 1408 TrffcLgtAsstCstAvlFlg6 "Traffic Light Assist Customization Availability Flag 6";
BA_ "SignalType" SG_ 1408 TrffcLgtAsstCstAvlFlg5 "ENM";
BA_ "SignalLongName" SG_ 1408 TrffcLgtAsstCstAvlFlg5 "Traffic Light Assist Customization Availability Flag 5";
BA_ "SignalType" SG_ 1408 TrffcLgtAsstCstAvlFlg4 "ENM";
BA_ "SignalLongName" SG_ 1408 TrffcLgtAsstCstAvlFlg4 "Traffic Light Assist Customization Availability Flag 4";
BA_ "SignalType" SG_ 1408 TrffcLgtAsstCstAvlFlg3 "ENM";
BA_ "SignalLongName" SG_ 1408 TrffcLgtAsstCstAvlFlg3 "Traffic Light Assist Customization Availability Flag 3";
BA_ "SignalType" SG_ 1408 TrffcLgtAsstCstAvlFlg2 "ENM";
BA_ "SignalLongName" SG_ 1408 TrffcLgtAsstCstAvlFlg2 "Traffic Light Assist Customization Availability Flag 2";
BA_ "SignalType" SG_ 1408 TrffcLgtAsstCstAvlFlg1 "ENM";
BA_ "SignalLongName" SG_ 1408 TrffcLgtAsstCstAvlFlg1 "Traffic Light Assist Customization Availability Flag 1";
BA_ "SignalType" SG_ 1408 GlrFrHgBmRspTypCstStAvl "ENM";
BA_ "SignalLongName" SG_ 1408 GlrFrHgBmRspTypCstStAvl "Glare Free High Beam Response Type Customization Setting Available";
BA_ "SignalType" SG_ 1408 TrffcLgtAsstCstSetAval "ENM";
BA_ "SignalLongName" SG_ 1408 TrffcLgtAsstCstSetAval "Traffic Light Assist Customization Setting Available";
BA_ "SignalLongName" SG_ 1423 TSMCurrSpdLim "Traffic Sign Memory Current Speed Limit";
BA_ "SignalType" SG_ 1423 TSMEurDispSgn2Mn "ENM";
BA_ "SignalLongName" SG_ 1423 TSMEurDispSgn2Mn "Traffic Sign Memory Europe Display Europe Sign 2 Main";
BA_ "SignalType" SG_ 1423 TSMEurDispSgn1Mn "ENM";
BA_ "SignalLongName" SG_ 1423 TSMEurDispSgn1Mn "Traffic Sign Memory Europe Display Sign 1 Main";
BA_ "SignalType" SG_ 1423 TSMUSAndCADispSgn1Mn "ENM";
BA_ "SignalLongName" SG_ 1423 TSMUSAndCADispSgn1Mn "Traffic Sign Memory US and Canada Display Sign 1 Main";
BA_ "SignalType" SG_ 1423 TSMUSAndCADispSgn2Mn "ENM";
BA_ "SignalLongName" SG_ 1423 TSMUSAndCADispSgn2Mn "Traffic Sign Memory US and Canada Display Sign 2 Main";
BA_ "SignalType" SG_ 1423 TSMEurDispSgn2AddOn "ENM";
BA_ "SignalLongName" SG_ 1423 TSMEurDispSgn2AddOn "Traffic Sign Memory Display Sign 2 Add-On";
BA_ "SignalType" SG_ 1423 TSMEurDispSgn1AddOn "ENM";
BA_ "SignalLongName" SG_ 1423 TSMEurDispSgn1AddOn "Traffic Sign Memory Europe Display Sign 1 Add-On";
BA_ "SignalType" SG_ 1423 FrwdVsFlDtcnIndOn "ENM";
BA_ "SignalLongName" SG_ 1423 FrwdVsFlDtcnIndOn "Front Vision Failure Detection Indication On";
BA_ "SignalType" SG_ 1423 FrwdVsAdvWthrIndOn "ENM";
BA_ "SignalLongName" SG_ 1423 FrwdVsAdvWthrIndOn "Front Vision Adverse Weather Indication On";
BA_ "SignalType" SG_ 1423 TSMUSAndCADispSgn2AddOn "ENM";
BA_ "SignalLongName" SG_ 1423 TSMUSAndCADispSgn2AddOn "Traffic Sign Memory US and Canada Display Sign 2 Add On";
BA_ "SignalType" SG_ 1423 TSMUSAndCADispSgn1AddOn "ENM";
BA_ "SignalLongName" SG_ 1423 TSMUSAndCADispSgn1AddOn "Traffic Sign Memory US and Canada Display Sign 1 Add On";
BA_ "SignalType" SG_ 1423 TrffcLgtAsstHUDWrnIndOn "ENM";
BA_ "SignalLongName" SG_ 1423 TrffcLgtAsstHUDWrnIndOn "Traffic Light Assist Heads up Display Warning Indication On";
BA_ "SignalType" SG_ 1423 TrffcLgtAsstClstrWrnIndOn "ENM";
BA_ "SignalLongName" SG_ 1423 TrffcLgtAsstClstrWrnIndOn "Traffic Light Assist Cluster Warning Indication On";
BA_ "SignalType" SG_ 1423 TSMSgnNtfnIndOn "ENM";
BA_ "SignalLongName" SG_ 1423 TSMSgnNtfnIndOn "Traffic Sign Memory Sign Notification Indication On";
BA_ "SignalType" SG_ 1423 TSMPDAMnSgnFlshgReq "ENM";
BA_ "SignalLongName" SG_ 1423 TSMPDAMnSgnFlshgReq "Traffic Sign Memory PDA Main Sign Flashing Request";
BA_ "SignalType" SG_ 1423 TSMNoEntryIndOn "ENM";
BA_ "SignalLongName" SG_ 1423 TSMNoEntryIndOn "Traffic Sign Memory No Entry Indication On";
BA_ "SignalType" SG_ 1423 TSMIcePsblIndOn "ENM";
BA_ "SignalLongName" SG_ 1423 TSMIcePsblIndOn "Traffic Sign Memory Ice Possible Indication On";
BA_ "SignalType" SG_ 1423 TSMAddTrfSgnAvIndOn "ENM";
BA_ "SignalLongName" SG_ 1423 TSMAddTrfSgnAvIndOn "Traffic Sign Memory Additional Traffic Signs Available Indication On";
BA_ "SignalType" SG_ 1423 FrwdVsFllBlckIndOn "ENM";
BA_ "SignalLongName" SG_ 1423 FrwdVsFllBlckIndOn "Front Vision Full Blockage Indication On";
BA_ "SignalType" SG_ 1423 TrffcLgtAsstRLADWrnIndOn "ENM";
BA_ "SignalLongName" SG_ 1423 TrffcLgtAsstRLADWrnIndOn "Traffic Light Assist Reflective Light Auxiliary Display Warning Indication On";
BA_ "SignalType" SG_ 1420 SBZALCAVisIndStatLt "ENM";
BA_ "SignalLongName" SG_ 1420 SBZALCAVisIndStatLt "SBZA - LCA Visual Indication State Left";
BA_ "SignalType" SG_ 1421 SBZALCAVisIndStatRt "ENM";
BA_ "SignalLongName" SG_ 1421 SBZALCAVisIndStatRt "SBZA - LCA Visual Indication State Right";
BA_ "SignalLongName" SG_ 1409 TLAHSR_HptcStRqstSeqNmb "Traffic Light Assist Haptic Seat Request : Traffic Light Assist Haptic Seat Request Sequence Number";
BA_ "SignalLongName" SG_ 1409 TLAHSR_HptcStRqstPls "Traffic Light Assist Haptic Seat Request : Traffic Light Assist Haptic Seat Request Pulses";
BA_ "SignalType" SG_ 1418 AutoHgBmActReq "ENM";
BA_ "SignalLongName" SG_ 1418 AutoHgBmActReq "Auto High Beam Activation Request";
BA_ "SignalLongName" SG_ 681 LtLnChgThrtAprchSpd "Left Lane Change Threat Approach Speed";
BA_ "SignalType" SG_ 681 LtFstAprchgVehObjDtd "ENM";
BA_ "SignalLongName" SG_ 681 LtFstAprchgVehObjDtd "Left Fast Approaching Vehicle Object Detected";
BA_ "SignalType" SG_ 1410 RrCrsTrfcAlrtLftIndCtrl "ENM";
BA_ "SignalLongName" SG_ 1410 RrCrsTrfcAlrtLftIndCtrl "Rear Cross Traffic Alert Left Indication Control";
BA_ "SignalType" SG_ 1410 RrCrsTrfcAlrtCstCrStVal "ENM";
BA_ "SignalLongName" SG_ 1410 RrCrsTrfcAlrtCstCrStVal "Rear Cross Traffic Alert Customization Current Setting Value";
BA_ "SignalType" SG_ 1410 LnChgAlrtCstCrStVal "ENM";
BA_ "SignalLongName" SG_ 1410 LnChgAlrtCstCrStVal "Lane Change Alert Customization Current Setting Value";
BA_ "SignalType" SG_ 1428 LtSdVehObjDtd "ENM";
BA_ "SignalLongName" SG_ 1428 LtSdVehObjDtd "Left Side Vehicle Object Detected";
BA_ "SignalType" SG_ 1428 SBZALCAOvrllOplSts "ENM";
BA_ "SignalLongName" SG_ 1428 SBZALCAOvrllOplSts "Side Blind Zone Alert Lane Change Alert Overall Operational Status";
BA_ "SignalLongName" SG_ 192 RCTBAD_BrkgCtlAccel "Rear Cross Traffic Braking Automatic Data : Braking Control Acceleration";
BA_ "SignalType" SG_ 192 RCTBAD_BrkgReqd "ENM";
BA_ "SignalLongName" SG_ 192 RCTBAD_BrkgReqd "Rear Cross Traffic Braking Automatic Data : Braking Requested";
BA_ "SignalType" SG_ 192 RCTBAD_BrkgReqTyp "ENM";
BA_ "SignalLongName" SG_ 192 RCTBAD_BrkgReqTyp "Rear Cross Traffic Braking Automatic Data : Braking Request Type";
BA_ "SignalType" SG_ 1411 SBZAlrtCstCrStVal "ENM";
BA_ "SignalLongName" SG_ 1411 SBZAlrtCstCrStVal "Side Blind Zone Alert Customization Current Setting Value";
BA_ "SignalType" SG_ 1411 ByclDtnCstCurrSetVal "ENM";
BA_ "SignalLongName" SG_ 1411 ByclDtnCstCurrSetVal "Bicycle Detection Customization Current Setting Value";
BA_ "SignalType" SG_ 1411 ByclDtnArbdIndStat "ENM";
BA_ "SignalLongName" SG_ 1411 ByclDtnArbdIndStat "Bicycle Detection Arbitrated Indication State";
BA_ "SignalType" SG_ 1411 ByclDtnCstAvlFlg1 "ENM";
BA_ "SignalLongName" SG_ 1411 ByclDtnCstAvlFlg1 "Bicycle Detection Customization Availability Flag 1";
BA_ "SignalType" SG_ 1411 RrCrsTrfcAlrtLtSdChmEvntStat "ENM";
BA_ "SignalLongName" SG_ 1411 RrCrsTrfcAlrtLtSdChmEvntStat "Rear Cross Traffic Alert Left Side Chime Event State";
BA_ "SignalType" SG_ 1411 ByclDtnArbdLvl2ChmEvntStat "ENM";
BA_ "SignalLongName" SG_ 1411 ByclDtnArbdLvl2ChmEvntStat "Bicycle Detection Arbitrated Level 2 Chime Event State";
BA_ "SignalType" SG_ 1411 ByclDtnArbdLvl1ChmEvntStat "ENM";
BA_ "SignalLongName" SG_ 1411 ByclDtnArbdLvl1ChmEvntStat "Bicycle Detection Arbitrated Level 1 Chime Event State";
BA_ "SignalType" SG_ 1411 LnChgAlrtCstAvlFlg1 "ENM";
BA_ "SignalLongName" SG_ 1411 LnChgAlrtCstAvlFlg1 "Lane Change Alert Customization Availability Flag 1";
BA_ "SignalType" SG_ 1411 ByclDtnCstSetAval "ENM";
BA_ "SignalLongName" SG_ 1411 ByclDtnCstSetAval "Bicycle Detection Customization Setting Available";
BA_ "SignalType" SG_ 1411 ByclDtnCstAvlFlg7 "ENM";
BA_ "SignalLongName" SG_ 1411 ByclDtnCstAvlFlg7 "Bicycle Detection Customization Availability Flag 7";
BA_ "SignalType" SG_ 1411 ByclDtnCstAvlFlg6 "ENM";
BA_ "SignalLongName" SG_ 1411 ByclDtnCstAvlFlg6 "Bicycle Detection Customization Availability Flag 6";
BA_ "SignalType" SG_ 1411 ByclDtnCstAvlFlg5 "ENM";
BA_ "SignalLongName" SG_ 1411 ByclDtnCstAvlFlg5 "Bicycle Detection Customization Availability Flag 5";
BA_ "SignalType" SG_ 1411 ByclDtnCstAvlFlg4 "ENM";
BA_ "SignalLongName" SG_ 1411 ByclDtnCstAvlFlg4 "Bicycle Detection Customization Availability Flag 4";
BA_ "SignalType" SG_ 1411 ByclDtnCstAvlFlg3 "ENM";
BA_ "SignalLongName" SG_ 1411 ByclDtnCstAvlFlg3 "Bicycle Detection Customization Availability Flag 3";
BA_ "SignalType" SG_ 1411 ByclDtnCstAvlFlg2 "ENM";
BA_ "SignalLongName" SG_ 1411 ByclDtnCstAvlFlg2 "Bicycle Detection Customization Availability Flag 2";
BA_ "SignalType" SG_ 1411 LnChgAlrtSysOffIndOn "ENM";
BA_ "SignalLongName" SG_ 1411 LnChgAlrtSysOffIndOn "Lane Change Alert System Off Indication On";
BA_ "SignalType" SG_ 1411 LnChgAlrtCstStAvl "ENM";
BA_ "SignalLongName" SG_ 1411 LnChgAlrtCstStAvl "Lane Change Alert Customization Setting Available";
BA_ "SignalType" SG_ 1411 LnChgAlrtCstAvlFlg7 "ENM";
BA_ "SignalLongName" SG_ 1411 LnChgAlrtCstAvlFlg7 "Lane Change Alert Customization Availability Flag 7";
BA_ "SignalType" SG_ 1411 LnChgAlrtCstAvlFlg6 "ENM";
BA_ "SignalLongName" SG_ 1411 LnChgAlrtCstAvlFlg6 "Lane Change Alert Customization Availability Flag 6";
BA_ "SignalType" SG_ 1411 LnChgAlrtCstAvlFlg5 "ENM";
BA_ "SignalLongName" SG_ 1411 LnChgAlrtCstAvlFlg5 "Lane Change Alert Customization Availability Flag 5";
BA_ "SignalType" SG_ 1411 LnChgAlrtCstAvlFlg4 "ENM";
BA_ "SignalLongName" SG_ 1411 LnChgAlrtCstAvlFlg4 "Lane Change Alert Customization Availability Flag 4";
BA_ "SignalType" SG_ 1411 LnChgAlrtCstAvlFlg3 "ENM";
BA_ "SignalLongName" SG_ 1411 LnChgAlrtCstAvlFlg3 "Lane Change Alert Customization Availability Flag 3";
BA_ "SignalType" SG_ 1411 LnChgAlrtCstAvlFlg2 "ENM";
BA_ "SignalLongName" SG_ 1411 LnChgAlrtCstAvlFlg2 "Lane Change Alert Customization Availability Flag 2";
BA_ "SignalType" SG_ 1411 RrCrsTrfcAlrtCstStAvl "ENM";
BA_ "SignalLongName" SG_ 1411 RrCrsTrfcAlrtCstStAvl "Rear Cross Traffic Alert Customization Setting Available";
BA_ "SignalType" SG_ 1411 RrCrsTrfcAlrtCstAvlFlg7 "ENM";
BA_ "SignalLongName" SG_ 1411 RrCrsTrfcAlrtCstAvlFlg7 "Rear Cross Traffic Alert Customization Availability Flag 7";
BA_ "SignalType" SG_ 1411 RrCrsTrfcAlrtCstAvlFlg6 "ENM";
BA_ "SignalLongName" SG_ 1411 RrCrsTrfcAlrtCstAvlFlg6 "Rear Cross Traffic Alert Customization Availability Flag 6";
BA_ "SignalType" SG_ 1411 RrCrsTrfcAlrtCstAvlFlg5 "ENM";
BA_ "SignalLongName" SG_ 1411 RrCrsTrfcAlrtCstAvlFlg5 "Rear Cross Traffic Alert Customization Availability Flag 5";
BA_ "SignalType" SG_ 1411 RrCrsTrfcAlrtCstAvlFlg4 "ENM";
BA_ "SignalLongName" SG_ 1411 RrCrsTrfcAlrtCstAvlFlg4 "Rear Cross Traffic Alert Customization Availability Flag 4";
BA_ "SignalType" SG_ 1411 RrCrsTrfcAlrtCstAvlFlg3 "ENM";
BA_ "SignalLongName" SG_ 1411 RrCrsTrfcAlrtCstAvlFlg3 "Rear Cross Traffic Alert Customization Availability Flag 3";
BA_ "SignalType" SG_ 1411 RrCrsTrfcAlrtCstAvlFlg2 "ENM";
BA_ "SignalLongName" SG_ 1411 RrCrsTrfcAlrtCstAvlFlg2 "Rear Cross Traffic Alert Customization Availability Flag 2";
BA_ "SignalType" SG_ 1411 RrCrsTrfcAlrtCstAvlFlg1 "ENM";
BA_ "SignalLongName" SG_ 1411 RrCrsTrfcAlrtCstAvlFlg1 "Rear Cross Traffic Alert Customization Availability Flag 1";
BA_ "SignalType" SG_ 1411 RrCrsTrfcBrkgAutoBrkgRelIndOn "ENM";
BA_ "SignalLongName" SG_ 1411 RrCrsTrfcBrkgAutoBrkgRelIndOn "Rear Cross Traffic Braking Autonomous Braking Release Indication On";
BA_ "SignalType" SG_ 1411 RrCrsTrfcAutoBrkgOffIndOn "ENM";
BA_ "SignalLongName" SG_ 1411 RrCrsTrfcAutoBrkgOffIndOn "Rear Cross Traffic Auto Braking Off Indication On";
BA_ "SignalType" SG_ 1411 RrCrsTrfcAlrtOffIndOn "ENM";
BA_ "SignalLongName" SG_ 1411 RrCrsTrfcAlrtOffIndOn "Rear Cross Traffic Alert System Off Indication On";
BA_ "SignalLongName" SG_ 719 RtLnChgThrtAprchSpd "Right Lane Change Threat Approach Speed";
BA_ "SignalType" SG_ 719 RtFstAprchgVehObjDtd "ENM";
BA_ "SignalLongName" SG_ 719 RtFstAprchgVehObjDtd "Right Fast Approaching Vehicle Object Detected";
BA_ "SignalType" SG_ 1413 RtSdVehObjDtd "ENM";
BA_ "SignalLongName" SG_ 1413 RtSdVehObjDtd "Right Side Vehicle Object Detected";
BA_ "SignalType" SG_ 1413 RrCrsTrfcAlrtRtSdChmEvntStat "ENM";
BA_ "SignalLongName" SG_ 1413 RrCrsTrfcAlrtRtSdChmEvntStat "Rear Cross Traffic Alert Right Side Chime Event State";
BA_ "SignalType" SG_ 1413 RrCrsTrfcAlrtRgIndCtrl "ENM";
BA_ "SignalLongName" SG_ 1413 RrCrsTrfcAlrtRgIndCtrl "Rear Cross Traffic Alert Right Indication Control";
BA_ "SignalLongName" SG_ 162 PAOG1_ObjID1 "Park Assist Objects Group 1 : Object ID 1";
BA_ "SignalLongName" SG_ 162 PAOG1_ID1 "Park Assist Objects Group 1 : ID 1";
BA_ "SignalType" SG_ 162 PAOG1_Hght1 "ENM";
BA_ "SignalLongName" SG_ 162 PAOG1_Hght1 "Park Assist Objects Group 1 : Height 1";
BA_ "SignalType" SG_ 162 PAOG1_Cnfd1 "ENM";
BA_ "SignalLongName" SG_ 162 PAOG1_Cnfd1 "Park Assist Objects Group 1 : Confidence 1";
BA_ "SignalLongName" SG_ 162 PAOG1_PstnP1_X1 "Park Assist Objects Group 1 : Position P1_X 1";
BA_ "SignalLongName" SG_ 162 PAOG1_PstnP1_Y1 "Park Assist Objects Group 1 : Position P1_Y 1";
BA_ "SignalLongName" SG_ 162 PAOG1_PstnP2_X1 "Park Assist Objects Group 1 : Position P2_X 1";
BA_ "SignalLongName" SG_ 162 PAOG1_PstnP2_Y1 "Park Assist Objects Group 1 : Position P2_Y 1";
BA_ "SignalLongName" SG_ 162 PAOG1_Tol1 "Park Assist Objects Group 1 : Tolerance 1";
BA_ "SignalType" SG_ 162 PAOG1_Typ1 "ENM";
BA_ "SignalLongName" SG_ 162 PAOG1_Typ1 "Park Assist Objects Group 1 : Type 1";
BA_ "SignalLongName" SG_ 536 PAOG2_ObjID2 "Park Assist Objects Group 2 : Object ID 2";
BA_ "SignalLongName" SG_ 536 PAOG2_ID2 "Park Assist Objects Group 2 : ID 2";
BA_ "SignalType" SG_ 536 PAOG2_Hght2 "ENM";
BA_ "SignalLongName" SG_ 536 PAOG2_Hght2 "Park Assist Objects Group 2 : Height 2";
BA_ "SignalType" SG_ 536 PAOG2_Cnfd2 "ENM";
BA_ "SignalLongName" SG_ 536 PAOG2_Cnfd2 "Park Assist Objects Group 2 : Confidence 2";
BA_ "SignalLongName" SG_ 536 PAOG2_PstnP1_X2 "Park Assist Objects Group 2 : Position P1_X 2";
BA_ "SignalLongName" SG_ 536 PAOG2_PstnP1_Y2 "Park Assist Objects Group 2 : Position P1_Y 2";
BA_ "SignalLongName" SG_ 536 PAOG2_PstnP2_X2 "Park Assist Objects Group 2 : Position P2_X 2";
BA_ "SignalLongName" SG_ 536 PAOG2_PstnP2_Y2 "Park Assist Objects Group 2 : Position P2_Y 2";
BA_ "SignalLongName" SG_ 536 PAOG2_Tol2 "Park Assist Objects Group 2 : Tolerance 2";
BA_ "SignalType" SG_ 536 PAOG2_Typ2 "ENM";
BA_ "SignalLongName" SG_ 536 PAOG2_Typ2 "Park Assist Objects Group 2 : Type 2";
BA_ "SignalLongName" SG_ 523 PAOG3_ObjID3 "Park Assist Objects Group 3 : Object ID 3";
BA_ "SignalLongName" SG_ 523 PAOG3_ID3 "Park Assist Objects Group 3 : ID 3";
BA_ "SignalType" SG_ 523 PAOG3_Hght3 "ENM";
BA_ "SignalLongName" SG_ 523 PAOG3_Hght3 "Park Assist Objects Group 3 : Height 3";
BA_ "SignalType" SG_ 523 PAOG3_Cnfd3 "ENM";
BA_ "SignalLongName" SG_ 523 PAOG3_Cnfd3 "Park Assist Objects Group 3 : Confidence 3";
BA_ "SignalLongName" SG_ 523 PAOG3_PstnP1_X3 "Park Assist Objects Group 3 : Position P1_X 3";
BA_ "SignalLongName" SG_ 523 PAOG3_PstnP1_Y3 "Park Assist Objects Group 3 : Position P1_Y 3";
BA_ "SignalLongName" SG_ 523 PAOG3_PstnP2_X3 "Park Assist Objects Group 3 : Position P2_X 3";
BA_ "SignalLongName" SG_ 523 PAOG3_PstnP2_Y3 "Park Assist Objects Group 3 : Position P2_Y 3";
BA_ "SignalLongName" SG_ 523 PAOG3_Tol3 "Park Assist Objects Group 3 : Tolerance 3";
BA_ "SignalType" SG_ 523 PAOG3_Typ3 "ENM";
BA_ "SignalLongName" SG_ 523 PAOG3_Typ3 "Park Assist Objects Group 3 : Type 3";
BA_ "SignalLongName" SG_ 657 LRRODP_BrstGrp1_PCSM "Long Range Radar Object Detection and Processing Burst 1 Protected Counter Sync Message";
BA_ "SignalLongName" SG_ 241 LRRODPB2P_POTk2IDAuth "Long Range Radar Object Detection and Processing Burst 2 Protected : Pedestrian Object Track 2 ID Authenticated";
BA_ "SignalType" SG_ 241 LRRODPB2P_POTk2DynPrpAuth "ENM";
BA_ "SignalLongName" SG_ 241 LRRODPB2P_POTk2DynPrpAuth "Long Range Radar Object Detection and Processing Burst 2 Protected : Pedestrian Object Track 2 Dynamic Property Authenticated";
BA_ "SignalType" SG_ 241 LRRODPB2P_POTk2CnfdStsAuth "ENM";
BA_ "SignalLongName" SG_ 241 LRRODPB2P_POTk2CnfdStsAuth "Long Range Radar Object Detection and Processing Burst 2 Protected : Pedestrian Object Track 2 Confidence Status Authenticated";
BA_ "SignalLongName" SG_ 241 LRRODPB2P_BrstID "Long Range Radar Object Detection and Processing Burst 2 Protected : Burst ID";
BA_ "SignalLongName" SG_ 241 LRRODPB2P_POTk2InPthPotAuth "Long Range Radar Object Detection and Processing Burst 2 Protected : Pedestrian Object Track 2 In Path Potential Authenticated";
BA_ "SignalLongName" SG_ 241 LRRODPB2P_POTk2PoILAAuth "Long Range Radar Object Detection and Processing Burst 2 Protected : Pedestrian Object Track 2 Point of Interest Lateral Acceleration Authenticated";
BA_ "SignalType" SG_ 241 LRRODPB2P_POTk2MStsAuth "ENM";
BA_ "SignalLongName" SG_ 241 LRRODPB2P_POTk2MStsAuth "Long Range Radar Object Detection and Processing Burst 2 Protected : Pedestrian Object Track 2 Measurement Status Authenticated";
BA_ "SignalLongName" SG_ 241 LRRODPB2P_POTk2PoILgAAuth "Long Range Radar Object Detection and Processing Burst 2 Protected : Pedestrian Object Track 2 Point of Interest Longitudinal Acceleration Authenticated";
BA_ "SignalLongName" SG_ 241 LRRODPB2P_POTk2PoILgPsAuth "Long Range Radar Object Detection and Processing Burst 2 Protected : Pedestrian Object Track 2 Point of Interest Longitudinal Position Authenticated";
BA_ "SignalLongName" SG_ 241 LRRODPB2P_POTk2PoILgVAuth "Long Range Radar Object Detection and Processing Burst 2 Protected : Pedestrian Object Track 2 Point of Interest Longitudinal Velocity Authenticated";
BA_ "SignalLongName" SG_ 241 LRRODPB2P_POTk2PoILPsAuth "Long Range Radar Object Detection and Processing Burst 2 Protected : Pedestrian Object Track 2 Point of Interest Lateral Position Authenticated";
BA_ "SignalLongName" SG_ 241 LRRODPB2P_POTk2PoILVAuth "Long Range Radar Object Detection and Processing Burst 2 Protected : Pedestrian Object Track 2 Point of Interest Lateral Velocity Authenticated";
BA_ "SignalLongName" SG_ 241 LRRODPB2P_VOTk3CICOPotAuth "Long Range Radar Object Detection and Processing Burst 2 Protected : Vehicle Object Track 3 Cut In Cut Out Potential Authenticated";
BA_ "SignalType" SG_ 241 LRRODPB2P_POTk2TypCnfdAuth "ENM";
BA_ "SignalLongName" SG_ 241 LRRODPB2P_POTk2TypCnfdAuth "Long Range Radar Object Detection and Processing Burst 2 Protected : Pedestrian Object Track 2 Type Confidence Authenticated";
BA_ "SignalType" SG_ 241 LRRODPB2P_POTk2TypAuth "ENM";
BA_ "SignalLongName" SG_ 241 LRRODPB2P_POTk2TypAuth "Long Range Radar Object Detection and Processing Burst 2 Protected : Pedestrian Object Track 2 Type Authenticated";
BA_ "SignalType" SG_ 241 LRRODPB2P_VOTk3DynPrpStsAuth "ENM";
BA_ "SignalLongName" SG_ 241 LRRODPB2P_VOTk3DynPrpStsAuth "Long Range Radar Object Detection and Processing Burst 2 Protected : Vehicle Object Track 3 Dynamic Property Status Authenticated";
BA_ "SignalType" SG_ 241 LRRODPB2P_VOTk3DynPrpAuth "ENM";
BA_ "SignalLongName" SG_ 241 LRRODPB2P_VOTk3DynPrpAuth "Long Range Radar Object Detection and Processing Burst 2 Protected : Vehicle Object Track 3 Dynamic Property Authenticated";
BA_ "SignalType" SG_ 241 LRRODPB2P_VOTk3CnfdStsAuth "ENM";
BA_ "SignalLongName" SG_ 241 LRRODPB2P_VOTk3CnfdStsAuth "Long Range Radar Object Detection and Processing Burst 2 Protected : Vehicle Object Track 3 Confidence Status Authenticated";
BA_ "SignalType" SG_ 241 LRRODPB2P_VOTk3MStsAuth "ENM";
BA_ "SignalLongName" SG_ 241 LRRODPB2P_VOTk3MStsAuth "Long Range Radar Object Detection and Processing Burst 2 Protected : Vehicle Object Track 3 Measurement Status Authenticated";
BA_ "SignalLongName" SG_ 241 LRRODPB2P_VOTk3IDAuth "Long Range Radar Object Detection and Processing Burst 2 Protected : Vehicle Object Track 3 ID Authenticated";
BA_ "SignalLongName" SG_ 241 LRRODPB2P_VOTk3PoILAAuth "Long Range Radar Object Detection and Processing Burst 2 Protected : Vehicle Object Track 3 Point of Interest Lateral Acceleration Authenticated";
BA_ "SignalLongName" SG_ 241 LRRODPB2P_VOTk3PoILgAAuth "Long Range Radar Object Detection and Processing Burst 2 Protected : Vehicle Object Track 3 Point of Interest Longitudinal Acceleration Authenticated";
BA_ "SignalLongName" SG_ 241 LRRODPB2P_VOTk3PoILgPsAuth "Long Range Radar Object Detection and Processing Burst 2 Protected : Vehicle Object Track 3 Point of Interest Longitudinal Position Authenticated";
BA_ "SignalLongName" SG_ 241 LRRODPB2P_VOTk3PoILgPsCAuth "Long Range Radar Object Detection and Processing Burst 2 Protected : Vehicle Object Track 3 Point of Interest Longitudinal Position Covariance Authenticated";
BA_ "SignalLongName" SG_ 241 LRRODPB2P_VOTk3PoILgthAuth "Long Range Radar Object Detection and Processing Burst 2 Protected : Vehicle Object Track 3 Point of Interest Length Authenticated";
BA_ "SignalLongName" SG_ 241 LRRODPB2P_VOTk3PoILgVAuth "Long Range Radar Object Detection and Processing Burst 2 Protected : Vehicle Object Track 3 Point of Interest Longitudinal Velocity Authenticated";
BA_ "SignalLongName" SG_ 241 LRRODPB2P_VOTk3PoILgVCAuth "Long Range Radar Object Detection and Processing Burst 2 Protected : Vehicle Object Track 3 Point of Interest Longitudinal Velocity Covariance Authenticated";
BA_ "SignalLongName" SG_ 241 LRRODPB2P_VOTk3PoILPsAuth "Long Range Radar Object Detection and Processing Burst 2 Protected : Vehicle Object Track 3 Point of Interest Lateral Position Authenticated";
BA_ "SignalLongName" SG_ 241 LRRODPB2P_VOTk3PoILPsCAuth "Long Range Radar Object Detection and Processing Burst 2 Protected : Vehicle Object Track 3 Point of Interest Lateral Position Covariance Authenticated";
BA_ "SignalLongName" SG_ 241 LRRODPB2P_VOTk3PoILVAuth "Long Range Radar Object Detection and Processing Burst 2 Protected : Vehicle Object Track 3 Point of Interest Lateral Velocity Authenticated";
BA_ "SignalLongName" SG_ 241 LRRODPB2P_VOTk3PoILVCAuth "Long Range Radar Object Detection and Processing Burst 2 Protected : Vehicle Object Track 3 Point of Interest Lateral Velocity Covariance Authenticated";
BA_ "SignalLongName" SG_ 241 LRRODPB2P_VOTk4CICOPotAuth "Long Range Radar Object Detection and Processing Burst 2 Protected : Vehicle Object Track 4 Cut In Cut Out Potential Authenticated";
BA_ "SignalType" SG_ 241 LRRODPB2P_VOTk3TypCnfdAuth "ENM";
BA_ "SignalLongName" SG_ 241 LRRODPB2P_VOTk3TypCnfdAuth "Long Range Radar Object Detection and Processing Burst 2 Protected : Vehicle Object Track 3 Type Confidence Authenticated";
BA_ "SignalLongName" SG_ 241 LRRODPB2P_VOTk4IDAuth "Long Range Radar Object Detection and Processing Burst 2 Protected : Vehicle Object Track 4 ID Authenticated";
BA_ "SignalType" SG_ 241 LRRODPB2P_VOTk4DynPrpStsAuth "ENM";
BA_ "SignalLongName" SG_ 241 LRRODPB2P_VOTk4DynPrpStsAuth "Long Range Radar Object Detection and Processing Burst 2 Protected : Vehicle Object Track 4 Dynamic Property Status Authenticated";
BA_ "SignalType" SG_ 241 LRRODPB2P_VOTk4DynPrpAuth "ENM";
BA_ "SignalLongName" SG_ 241 LRRODPB2P_VOTk4DynPrpAuth "Long Range Radar Object Detection and Processing Burst 2 Protected : Vehicle Object Track 4 Dynamic Property Authenticated";
BA_ "SignalType" SG_ 241 LRRODPB2P_VOTk4CnfdStsAuth "ENM";
BA_ "SignalLongName" SG_ 241 LRRODPB2P_VOTk4CnfdStsAuth "Long Range Radar Object Detection and Processing Burst 2 Protected : Vehicle Object Track 4 Confidence Status Authenticated";
BA_ "SignalLongName" SG_ 241 LRRODPB2P_VOTk4PoILAAuth "Long Range Radar Object Detection and Processing Burst 2 Protected : Vehicle Object Track 4 Point of Interest Lateral Acceleration Authenticated";
BA_ "SignalType" SG_ 241 LRRODPB2P_VOTk4MStsAuth "ENM";
BA_ "SignalLongName" SG_ 241 LRRODPB2P_VOTk4MStsAuth "Long Range Radar Object Detection and Processing Burst 2 Protected : Vehicle Object Track 4 Measurement Status Authenticated";
BA_ "SignalLongName" SG_ 241 LRRODPB2P_VOTk4PoILgAAuth "Long Range Radar Object Detection and Processing Burst 2 Protected : Vehicle Object Track 4 Point of Interest Longitudinal Acceleration Authenticated";
BA_ "SignalLongName" SG_ 241 LRRODPB2P_VOTk4PoILgPsAuth "Long Range Radar Object Detection and Processing Burst 2 Protected : Vehicle Object Track 4 Point of Interest Longitudinal Position Authenticated";
BA_ "SignalLongName" SG_ 241 LRRODPB2P_VOTk4PoILgPsCAuth "Long Range Radar Object Detection and Processing Burst 2 Protected : Vehicle Object Track 4 Point of Interest Longitudinal Position Covariance Authenticated";
BA_ "SignalLongName" SG_ 241 LRRODPB2P_VOTk4PoILgthAuth "Long Range Radar Object Detection and Processing Burst 2 Protected : Vehicle Object Track 4 Point of Interest Length Authenticated";
BA_ "SignalLongName" SG_ 241 LRRODPB2P_VOTk4PoILgVAuth "Long Range Radar Object Detection and Processing Burst 2 Protected : Vehicle Object Track 4 Point of Interest Longitudinal Velocity Authenticated";
BA_ "SignalLongName" SG_ 241 LRRODPB2P_VOTk4PoILgVCAuth "Long Range Radar Object Detection and Processing Burst 2 Protected : Vehicle Object Track 4 Point of Interest Longitudinal Velocity Covariance Authenticated";
BA_ "SignalLongName" SG_ 241 LRRODPB2P_VOTk4PoILPsAuth "Long Range Radar Object Detection and Processing Burst 2 Protected : Vehicle Object Track 4 Point of Interest Lateral Position Authenticated";
BA_ "SignalLongName" SG_ 241 LRRODPB2P_VOTk4PoILPsCAuth "Long Range Radar Object Detection and Processing Burst 2 Protected : Vehicle Object Track 4 Point of Interest Lateral Position Covariance Authenticated";
BA_ "SignalLongName" SG_ 241 LRRODPB2P_VOTk4PoILVAuth "Long Range Radar Object Detection and Processing Burst 2 Protected : Vehicle Object Track 4 Point of Interest Lateral Velocity Authenticated";
BA_ "SignalLongName" SG_ 241 LRRODPB2P_VOTk4PoILVCAuth "Long Range Radar Object Detection and Processing Burst 2 Protected : Vehicle Object Track 4 Point of Interest Lateral Velocity Covariance Authenticated";
BA_ "SignalType" SG_ 241 LRRODPB2P_VOTk4TypCnfdAuth "ENM";
BA_ "SignalLongName" SG_ 241 LRRODPB2P_VOTk4TypCnfdAuth "Long Range Radar Object Detection and Processing Burst 2 Protected : Vehicle Object Track 4 Type Confidence Authenticated";
BA_ "SignalType" SG_ 241 LRRODPB2P_VOTk5CnfdStsAuth "ENM";
BA_ "SignalLongName" SG_ 241 LRRODPB2P_VOTk5CnfdStsAuth "Long Range Radar Object Detection and Processing Burst 2 Protected : Vehicle Object Track 5 Confidence Status Authenticated";
BA_ "SignalLongName" SG_ 241 LRRODPB2P_VOTk5CICOPotAuth "Long Range Radar Object Detection and Processing Burst 2 Protected : Vehicle Object Track 5 Cut In Cut Out Potential Authenticated";
BA_ "SignalLongName" SG_ 241 LRRODPB2P_VOTk5IDAuth "Long Range Radar Object Detection and Processing Burst 2 Protected : Vehicle Object Track 5 ID Authenticated";
BA_ "SignalType" SG_ 241 LRRODPB2P_VOTk5DynPrpStsAuth "ENM";
BA_ "SignalLongName" SG_ 241 LRRODPB2P_VOTk5DynPrpStsAuth "Long Range Radar Object Detection and Processing Burst 2 Protected : Vehicle Object Track 5 Dynamic Property Status Authenticated";
BA_ "SignalType" SG_ 241 LRRODPB2P_VOTk5DynPrpAuth "ENM";
BA_ "SignalLongName" SG_ 241 LRRODPB2P_VOTk5DynPrpAuth "Long Range Radar Object Detection and Processing Burst 2 Protected : Vehicle Object Track 5 Dynamic Property Authenticated";
BA_ "SignalLongName" SG_ 241 LRRODPB2P_VOTk5LgthdthAuth "Long Range Radar Object Detection and Processing Burst 2 Protected : Vehicle Object Track 5 Point of Interest Length Authenticated";
BA_ "SignalType" SG_ 241 LRRODPB2P_VOTk5MStsAuth "ENM";
BA_ "SignalLongName" SG_ 241 LRRODPB2P_VOTk5MStsAuth "Long Range Radar Object Detection and Processing Burst 2 Protected : Vehicle Object Track 5 Measurement Status Authenticated";
BA_ "SignalLongName" SG_ 241 LRRODPB2P_VOTk5PoILAAuth "Long Range Radar Object Detection and Processing Burst 2 Protected : Vehicle Object Track 5 Point of Interest Lateral Acceleration Authenticated";
BA_ "SignalLongName" SG_ 241 LRRODPB2P_VOTk5PoILgAAuth "Long Range Radar Object Detection and Processing Burst 2 Protected : Vehicle Object Track 5 Point of Interest Longitudinal Acceleration Authenticated";
BA_ "SignalLongName" SG_ 241 LRRODPB2P_VOTk5PoILgPsAuth "Long Range Radar Object Detection and Processing Burst 2 Protected : Vehicle Object Track 5 Point of Interest Longitudinal Position Authenticated";
BA_ "SignalLongName" SG_ 241 LRRODPB2P_VOTk5PoILgPsCAuth "Long Range Radar Object Detection and Processing Burst 2 Protected : Vehicle Object Track 5 Point of Interest Longitudinal Position Covariance Authenticated";
BA_ "SignalLongName" SG_ 241 LRRODPB2P_VOTk5PoILgVAuth "Long Range Radar Object Detection and Processing Burst 2 Protected : Vehicle Object Track 5 Point of Interest Longitudinal Velocity Authenticated";
BA_ "SignalLongName" SG_ 241 LRRODPB2P_VOTk5PoILgVCAuth "Long Range Radar Object Detection and Processing Burst 2 Protected : Vehicle Object Track 5 Point of Interest Longitudinal Velocity Covariance Authenticated";
BA_ "SignalLongName" SG_ 241 LRRODPB2P_VOTk5PoILPsAuth "Long Range Radar Object Detection and Processing Burst 2 Protected : Vehicle Object Track 5 Point of Interest Lateral Position Authenticated";
BA_ "SignalLongName" SG_ 241 LRRODPB2P_VOTk5PoILPsCAuth "Long Range Radar Object Detection and Processing Burst 2 Protected : Vehicle Object Track 5 Point of Interest Lateral Position Covariance Authenticated";
BA_ "SignalLongName" SG_ 241 LRRODPB2P_VOTk5PoILVAuth "Long Range Radar Object Detection and Processing Burst 2 Protected : Vehicle Object Track 5 Point of Interest Lateral Velocity Authenticated";
BA_ "SignalLongName" SG_ 241 LRRODPB2P_VOTk5PoILVCAuth "Long Range Radar Object Detection and Processing Burst 2 Protected : Vehicle Object Track 5 Point of Interest Lateral Velocity Covariance Authenticated";
BA_ "SignalLongName" SG_ 241 LRRODPB2P_Filler "Long Range Radar Object Detection and Processing Burst 2 Protected : Filler";
BA_ "SignalType" SG_ 241 LRRODPB2P_VOTk5TypCnfdAuth "ENM";
BA_ "SignalLongName" SG_ 241 LRRODPB2P_VOTk5TypCnfdAuth "Long Range Radar Object Detection and Processing Burst 2 Protected : Vehicle Object Track 5 Type Confidence Authenticated";
VAL_ 219 FCODPB8P_FVLBTk8ClrAuth 0 "UNKNOWN" 1 "WHITE" 2 "YELLOW/ORANGE" 3 "OTHER" ;
VAL_ 219 FCODPB8P_FVLBTk8PstnTypAuth 0 "Unknown" 1 "Host Left Lane" 2 "Host Right Lane" 3 "Next Left Lane" 4 "Next Right Lane" 5 "Second Next Left Lane" 6 "Second Next Right Lane" 7 "Third Next Left Lane" 8 "Third Next Right Lane" 9 "Fourth Next Left Lane" 10 "Fourth Next Right Lane" 11 "Fifth Next Left Lane" 12 "Fifth Next Right Lane" ;
VAL_ 219 FCODPB8P_FVLBTk8TypAuth 0 "UNDECIDED" 1 "SOLID" 2 "DASHED" 3 "ROAD EDGE" 4 "DOUBLE LINE" 5 "BOTTS DOTS" 6 "VIRTUAL" 7 "TRIPLE LINE" ;
VAL_ 219 FCODPB8P_FVLBTk8QltyAuth 0 "VERY LOW QUALITY" 1 "LOW QUALITY" 2 "PREDICTION" 3 "HIGH QUALITY" ;
VAL_ 219 FCODPB8P_FVVOTk8BrkLgtStsAuth 0 "UNKNOWN" 1 "OFF" 2 "ON" 3 "FLASHING" ;
VAL_ 219 FCODPB8P_FVVOTk8DynPrpAuth 0 "Has Never Moved" 1 "Has Moved But Currently Stopped" 2 "Moving In Same Direction As Host" 3 "Moving In Opposite Direction As Host" 4 "Crossing From Left To Right" 5 "Crossing From Right To Left" 6 "Unknown" ;
VAL_ 219 FCODPB8P_FVVOTk8CnfdStsAuth 0 "Highly Speculative" 1 "Speculative" 2 "Confident" 3 "Highly Confident" ;
VAL_ 219 FCODPB8P_FVVOTk8DynPrpStsAuth 0 "Stopped" 1 "Not Stopped" ;
VAL_ 219 FCODPB8P_FVVOTk8MStsAuth 0 "No Object" 1 "New Object" 2 "Latent Track Not Detected this Cycle" 3 "Measured this Cycle" ;
VAL_ 219 FCODPB8P_FVVOTk8LnAsmtAuth 0 "UNKNOWN" 1 "HOST LANE" 2 "RIGHT LANE" 3 "LEFT LANE" 4 "2nd RIGHT LANE" 5 "2nd LEFT LANE" ;
VAL_ 219 FCODPB8P_FVVOTk9BrkLgtStsAuth 0 "UNKNOWN" 1 "OFF" 2 "ON" 3 "FLASHING" ;
VAL_ 219 FCODPB8P_FVVOTk8TypCnfdAuth 0 "Highly Speculative" 1 "Speculative" 2 "Confident" 3 "Highly Confident" ;
VAL_ 219 FCODPB8P_FVVOTk8TypAuth 0 "Unknown" 1 "Motorcycle" 2 "Vehicle" 3 "Truck" ;
VAL_ 219 FCODPB8P_FVVOTk8TSLgtStsAuth 0 "UNKNOWN" 1 "OFF" 2 "LEFT" 3 "RIGHT" 4 "BOTH" ;
VAL_ 219 FCODPB8P_FVVOTk9CnfdStsAuth 0 "Highly Speculative" 1 "Speculative" 2 "Confident" 3 "Highly Confident" ;
VAL_ 219 FCODPB8P_FVVOTk9DynPrpStsAuth 0 "Stopped" 1 "Not Stopped" ;
VAL_ 219 FCODPB8P_FVVOTk9DynPrpAuth 0 "Has Never Moved" 1 "Has Moved But Currently Stopped" 2 "Moving In Same Direction As Host" 3 "Moving In Opposite Direction As Host" 4 "Crossing From Left To Right" 5 "Crossing From Right To Left" 6 "Unknown" ;
VAL_ 219 FCODPB8P_FVVOTk9MStsAuth 0 "No Object" 1 "New Object" 2 "Latent Track Not Detected this Cycle" 3 "Measured this Cycle" ;
VAL_ 219 FCODPB8P_FVVOTk9LnAsmtAuth 0 "UNKNOWN" 1 "HOST LANE" 2 "RIGHT LANE" 3 "LEFT LANE" 4 "2nd RIGHT LANE" 5 "2nd LEFT LANE" ;
VAL_ 219 FCODPB8P_FVVOTk9TypAuth 0 "Unknown" 1 "Motorcycle" 2 "Vehicle" 3 "Truck" ;
VAL_ 219 FCODPB8P_FVVOTk9TSLgtStsAuth 0 "UNKNOWN" 1 "OFF" 2 "LEFT" 3 "RIGHT" 4 "BOTH" ;
VAL_ 219 FrwdVsnVehObjTk8DatIntegCkd 0 "Unknown" 1 "Pass" 2 "Fail" ;
VAL_ 219 FrwdVsnLnBdryTk8DatIntegCkd 0 "Unknown" 1 "Pass" 2 "Fail" ;
VAL_ 219 FCODPB8P_FVVOTk9TypCnfdAuth 0 "Highly Speculative" 1 "Speculative" 2 "Confident" 3 "Highly Confident" ;
VAL_ 237 FCODPB9P_FVCIPthVehAlrtNwAuth 0 "FALSE" 1 "TRUE" ;
VAL_ 237 FCODPB9P_FVCIPthVehAhdNwAuth 0 "FALSE" 1 "TRUE" ;
VAL_ 237 FCODPB9P_FrwdDistIndDgrdAuth 0 "FALSE" 1 "TRUE" ;
VAL_ 237 FCODPB9P_FrwdClsnAlrtDgrdAuth 0 "FALSE" 1 "TRUE" ;
VAL_ 237 FCODPB9P_ClsnImntBrkgDgrdAuth 0 "FALSE" 1 "TRUE" ;
VAL_ 237 FCODPB9P_AdpCruzCtlDgrdAuth 0 "FALSE" 1 "TRUE" ;
VAL_ 237 FCODPB9P_FVHTPNtfyNwAuth 0 "FALSE" 1 "TRUE" ;
VAL_ 237 FCODPB9P_FVHTPBrkNwAuth 0 "FALSE" 1 "TRUE" ;
VAL_ 237 FCODPB9P_FVHTPAlrtNwAuth 0 "FALSE" 1 "TRUE" ;
VAL_ 237 FCODPB9P_FVCIPthVehBrkNwAuth 0 "FALSE" 1 "TRUE" ;
VAL_ 237 FCODPB9P_FVLFTk1TypAuth 0 "Lane Fusion" 1 "HPP Left" 2 "HPP Center" 3 "HPP Right" ;
VAL_ 237 FCODPB9P_FVLFTk2TypAuth 0 "Lane Fusion" 1 "HPP Left" 2 "HPP Center" 3 "HPP Right" ;
VAL_ 237 FCODPB9P_FVLFTk3TypAuth 0 "Lane Fusion" 1 "HPP Left" 2 "HPP Center" 3 "HPP Right" ;
VAL_ 237 FCODPB9P_PedtrnClsnBrkgDgrdAuth 0 "FALSE" 1 "TRUE" ;
VAL_ 237 FCODPB9P_PedtrnClsnAlrtDgrdAuth 0 "FALSE" 1 "TRUE" ;
VAL_ 237 FCODPB9P_LnKeepAsstDgrdAuth 0 "FALSE" 1 "TRUE" ;
VAL_ 237 FCODPB9P_LnCntrDgrdAuth 0 "FALSE" 1 "TRUE" ;
VAL_ 237 FCODPB9P_IntsctClsnMtgnDgrdAuth 0 "FALSE" 1 "TRUE" ;
VAL_ 237 FCODPB9P_FVLFTk4TypAuth 0 "Lane Fusion" 1 "HPP Left" 2 "HPP Center" 3 "HPP Right" ;
VAL_ 237 FrwdVsnVehObjTk9DatIntegCkd 0 "Unknown" 1 "Pass" 2 "Fail" ;
VAL_ 237 FrwdVsnLnBdryTk9DatIntegCkd 0 "Unknown" 1 "Pass" 2 "Fail" ;
VAL_ 237 FCODPB9P_FVHTPPrfllNwAuth 0 "FALSE" 1 "TRUE" ;
VAL_ 237 FCODPB9P_FVCIPthVehPrfllNwAuth 0 "FALSE" 1 "TRUE" ;
VAL_ 237 FCODPB9P_PedtrnNtfnDgrdAuth 0 "FALSE" 1 "TRUE" ;
VAL_ 218 FCODPB10P_FVVOTk10PoI1PsVisAuth 0 "Unknown" 1 "Visible" 2 "Projected" ;
VAL_ 218 FCODPB10P_FVVOTk10PoI2PsVisAuth 0 "Unknown" 1 "Visible" 2 "Projected" ;
VAL_ 218 FCODPB10P_FVVOTk1PoI1PsVisAuth 0 "Unknown" 1 "Visible" 2 "Projected" ;
VAL_ 218 FCODPB10P_FVVOTk10PoI3PsVisAuth 0 "Unknown" 1 "Visible" 2 "Projected" ;
VAL_ 218 FCODPB10P_FVVOTk1PoI2PsVisAuth 0 "Unknown" 1 "Visible" 2 "Projected" ;
VAL_ 218 FCODPB10P_FVVOTk2PoI1PsVisAuth 0 "Unknown" 1 "Visible" 2 "Projected" ;
VAL_ 218 FCODPB10P_FVVOTk1PoI3PsVisAuth 0 "Unknown" 1 "Visible" 2 "Projected" ;
VAL_ 218 FCODPB10P_FVVOTk2PoI2PsVisAuth 0 "Unknown" 1 "Visible" 2 "Projected" ;
VAL_ 218 FCODPB10P_FVVOTk3PoI1PsVisAuth 0 "Unknown" 1 "Visible" 2 "Projected" ;
VAL_ 218 FCODPB10P_FVVOTk2PoI3PsVisAuth 0 "Unknown" 1 "Visible" 2 "Projected" ;
VAL_ 218 FCODPB10P_FVVOTk3PoI2PsVisAuth 0 "Unknown" 1 "Visible" 2 "Projected" ;
VAL_ 218 FCODPB10P_FVVOTk4PoI1PsVisAuth 0 "Unknown" 1 "Visible" 2 "Projected" ;
VAL_ 218 FCODPB10P_FVVOTk3PoI3PsVisAuth 0 "Unknown" 1 "Visible" 2 "Projected" ;
VAL_ 218 FCODPB10P_FVVOTk4PoI2PsVisAuth 0 "Unknown" 1 "Visible" 2 "Projected" ;
VAL_ 218 FCODPB10P_FVVOTk5PoI1PsVisAuth 0 "Unknown" 1 "Visible" 2 "Projected" ;
VAL_ 218 FCODPB10P_FVVOTk4PoI3PsVisAuth 0 "Unknown" 1 "Visible" 2 "Projected" ;
VAL_ 218 FCODPB10P_FVVOTk5PoI2PsVisAuth 0 "Unknown" 1 "Visible" 2 "Projected" ;
VAL_ 218 FCODPB10P_FVVOTk6PoI1PsVisAuth 0 "Unknown" 1 "Visible" 2 "Projected" ;
VAL_ 218 FCODPB10P_FVVOTk5PoI3PsVisAuth 0 "Unknown" 1 "Visible" 2 "Projected" ;
VAL_ 218 FCODPB10P_FVVOTk6PoI2PsVisAuth 0 "Unknown" 1 "Visible" 2 "Projected" ;
VAL_ 218 FCODPB10P_FVVOTk7PoI1PsVisAuth 0 "Unknown" 1 "Visible" 2 "Projected" ;
VAL_ 218 FCODPB10P_FVVOTk6PoI3PsVisAuth 0 "Unknown" 1 "Visible" 2 "Projected" ;
VAL_ 218 FCODPB10P_FVVOTk7PoI2PsVisAuth 0 "Unknown" 1 "Visible" 2 "Projected" ;
VAL_ 218 FCODPB10P_FVVOTk8PoI1PsVisAuth 0 "Unknown" 1 "Visible" 2 "Projected" ;
VAL_ 218 FCODPB10P_FVVOTk7PoI3PsVisAuth 0 "Unknown" 1 "Visible" 2 "Projected" ;
VAL_ 218 FCODPB10P_FVVOTk8PoI2PsVisAuth 0 "Unknown" 1 "Visible" 2 "Projected" ;
VAL_ 218 FCODPB10P_FVVOTk9PoI1PsVisAuth 0 "Unknown" 1 "Visible" 2 "Projected" ;
VAL_ 218 FCODPB10P_FVVOTk8PoI3PsVisAuth 0 "Unknown" 1 "Visible" 2 "Projected" ;
VAL_ 218 FCODPB10P_FVVOTk9PoI2PsVisAuth 0 "Unknown" 1 "Visible" 2 "Projected" ;
VAL_ 218 FrwdVsnVehObjTk10DatIntegCkd 0 "Unknown" 1 "Pass" 2 "Fail" ;
VAL_ 218 FrwdVsnLnBdryTk10DatIntegCkd 0 "Unknown" 1 "Pass" 2 "Fail" ;
VAL_ 218 FCODPB10P_FVVOTk9PoI3PsVisAuth 0 "Unknown" 1 "Visible" 2 "Projected" ;
VAL_ 233 FCODPB1P_FVLBTk1ClrAuth 0 "UNKNOWN" 1 "WHITE" 2 "YELLOW/ORANGE" 3 "OTHER" ;
VAL_ 233 FCODPB1P_FVLBTk1PstnTypAuth 0 "Unknown" 1 "Host Left Lane" 2 "Host Right Lane" 3 "Next Left Lane" 4 "Next Right Lane" 5 "Second Next Left Lane" 6 "Second Next Right Lane" 7 "Third Next Left Lane" 8 "Third Next Right Lane" 9 "Fourth Next Left Lane" 10 "Fourth Next Right Lane" 11 "Fifth Next Left Lane" 12 "Fifth Next Right Lane" ;
VAL_ 233 FCODPB1P_FVLBTk1TypAuth 0 "UNDECIDED" 1 "SOLID" 2 "DASHED" 3 "ROAD EDGE" 4 "DOUBLE LINE" 5 "BOTTS DOTS" 6 "VIRTUAL" 7 "TRIPLE LINE" ;
VAL_ 233 FCODPB1P_FVLBTk1QltyAuth 0 "VERY LOW QUALITY" 1 "LOW QUALITY" 2 "PREDICTION" 3 "HIGH QUALITY" ;
VAL_ 233 FCODPB1P_FVPOTk1DynPrpAuth 0 "Has Never Moved" 1 "Has Moved But Currently Stopped" 2 "Moving In Same Direction As Host" 3 "Moving In Opposite Direction As Host" 4 "Crossing Path" ;
VAL_ 233 FCODPB1P_FVPOTk1CnfdStsAuth 0 "Highly Speculative" 1 "Speculative" 2 "Confident" 3 "Highly Confident" ;
VAL_ 233 FCODPB1P_FVPOTk1MStsAuth 0 "No Object" 1 "New Object" 2 "Latent Track Not Detected this Cycle" 3 "Measured this Cycle" ;
VAL_ 233 FCODPB1P_FVVOTk1BrkLgtStsAuth 0 "UNKNOWN" 1 "OFF" 2 "ON" 3 "FLASHING" ;
VAL_ 233 FCODPB1P_FVPOTk1TypCnfdAuth 0 "Highly Speculative" 1 "Speculative" 2 "Confident" 3 "Highly Confident" ;
VAL_ 233 FCODPB1P_FVPOTk1TypAuth 0 "Unknown" 1 "Pedestrian" 2 "Bicycle" ;
VAL_ 233 FCODPB1P_FVVOTk1DynPrpAuth 0 "Has Never Moved" 1 "Has Moved But Currently Stopped" 2 "Moving In Same Direction As Host" 3 "Moving In Opposite Direction As Host" 4 "Crossing From Left To Right" 5 "Crossing From Right To Left" 6 "Unknown" ;
VAL_ 233 FCODPB1P_FVVOTk1CnfdStsAuth 0 "Highly Speculative" 1 "Speculative" 2 "Confident" 3 "Highly Confident" ;
VAL_ 233 FCODPB1P_FVVOTk1DynPrpStsAuth 0 "Stopped" 1 "Not Stopped" ;
VAL_ 233 FCODPB1P_FVVOTk1MStsAuth 0 "No Object" 1 "New Object" 2 "Latent Track Not Detected this Cycle" 3 "Measured this Cycle" ;
VAL_ 233 FCODPB1P_FVVOTk1LnAsmtAuth 0 "UNKNOWN" 1 "HOST LANE" 2 "RIGHT LANE" 3 "LEFT LANE" 4 "2nd RIGHT LANE" 5 "2nd LEFT LANE" ;
VAL_ 233 FCODPB1P_FVVOTk1TypCnfdAuth 0 "Highly Speculative" 1 "Speculative" 2 "Confident" 3 "Highly Confident" ;
VAL_ 233 FCODPB1P_FVVOTk1TypAuth 0 "Unknown" 1 "Motorcycle" 2 "Vehicle" 3 "Truck" ;
VAL_ 233 FCODPB1P_FVVOTk1TSLgtStsAuth 0 "UNKNOWN" 1 "OFF" 2 "LEFT" 3 "RIGHT" 4 "BOTH" ;
VAL_ 233 FrwdVsnPedtrnObjTk1DatIntegCkd 0 "Unknown" 1 "Pass" 2 "Fail" ;
VAL_ 233 FrwdVsnLnBdryTk1DatIntegCkd 0 "Unknown" 1 "Pass" 2 "Fail" ;
VAL_ 233 FrwdVsnVehObjTk1DatIntegCkd 0 "Unknown" 1 "Pass" 2 "Fail" ;
VAL_ 718 GPSC_PPSLat_Inv 0 "FALSE" 1 "TRUE" ;
VAL_ 718 GPSC_PPSLong_Inv 0 "FALSE" 1 "TRUE" ;
VAL_ 2147745810 HDLM_CAN8_ClscCANHrtBtActv 0 "FALSE" 1 "TRUE" ;
VAL_ 87 HVPPP_FrwdVsnModeCmdAuth 0 "Not Reporting Object Data" 1 "Reporting Object Data" ;
VAL_ 87 HVPPP_HstVehLatVelAuth_Inv 0 "FALSE" 1 "TRUE" ;
VAL_ 87 HVPPP_HstVehLngVelAuth_Inv 0 "FALSE" 1 "TRUE" ;
VAL_ 87 HVPPP_HstVehPathModeAuth 0 "Disabled" 1 "Low Speed" 2 "High Speed" ;
VAL_ 87 HVPPP_HstVehTrvlDirAuth 0 "Unknown" 1 "Forward or Stopped on a Forward Gear" 2 "Reversed or Stopped in a Reverse Gear" 3 "Other" ;
VAL_ 87 HVPPP_HstVehVelAuth_Inv 0 "FALSE" 1 "TRUE" ;
VAL_ 87 HVPPP_LngRngRadarModeCmdAuth 0 "Not Radiating" 1 "Not Reporting Object Data" 2 "Reporting" ;
VAL_ 87 HVPPP_HstVehYawRateAuth_Inv 0 "FALSE" 1 "TRUE" ;
VAL_ 87 HVPPP_ShrtRngRadarModeCmdAuth 0 "Not Radiating" 1 "Not Reporting Object Data" 2 "Reporting Object Data" ;
VAL_ 87 HVPPP_ObjsRetndRrwdSnsrsAuth 0 "Unknown" 1 "Objects Reported" 2 "No Objects Reported" ;
VAL_ 87 HVPPP_ObjsRetndFrwdSnsrsAuth 0 "Unknown" 1 "Objects Reported" 2 "No Objects Reported" ;
VAL_ 87 DrvrMonSysModeCmd 0 "Not Radiating" 1 "Not Reporting Object Data" 2 "Reporting Object Data" ;
VAL_ 87 LnFllwgFtrStatAuth 0 "Off" 1 "Unavailable" 2 "Disabled" 3 "Enabled" 4 "Active" 5 "Cautionary" 6 "Override" 7 "Degraded" 8 "No Return" 9 "Ended" 10 "Non-Responsive Driver" ;
VAL_ 87 HstVehRideHghtOfst_Inv 0 "FALSE" 1 "TRUE" ;
VAL_ 87 HstVehRideHghtOfstSts 0 "In Range" 1 "Out of Range" ;
VAL_ 87 GeofncngRstrctdZnStsGtd 0 "Unknown" 1 "Restricted" 2 "Unrestricted" ;
VAL_ 87 HstVehFrtRdWhlAng_Inv 0 "FALSE" 1 "TRUE" ;
VAL_ 38 HVPPBG2P_HstVehTrvlDirAuth 0 "Unknown" 1 "Forward or Stopped on a Forward Gear" 2 "Reversed or Stopped in a Reverse Gear" 3 "Other" ;
VAL_ 38 HVPPBG2P_HstVehRideHghtOfstSts 0 "In Range" 1 "Out of Range" ;
VAL_ 38 HVPPBG2P_HstVehRideHghtOfst_Inv 0 "FALSE" 1 "TRUE" ;
VAL_ 1419 SBZAlrtCstAvlFlg7 0 "FALSE" 1 "TRUE" ;
VAL_ 1419 SBZAlrtCstAvlFlg6 0 "FALSE" 1 "TRUE" ;
VAL_ 1419 SBZAlrtCstAvlFlg5 0 "FALSE" 1 "TRUE" ;
VAL_ 1419 SBZAlrtCstAvlFlg4 0 "FALSE" 1 "TRUE" ;
VAL_ 1419 SBZAlrtCstAvlFlg3 0 "FALSE" 1 "TRUE" ;
VAL_ 1419 SBZAlrtCstAvlFlg2 0 "FALSE" 1 "TRUE" ;
VAL_ 1419 SBZAlrtCstAvlFlg1 0 "FALSE" 1 "TRUE" ;
VAL_ 1419 LnChgAlrtLmtdTrlrIndOn 0 "FALSE" 1 "TRUE" ;
VAL_ 1419 ServSdDtcSysIndOn 0 "FALSE" 1 "TRUE" ;
VAL_ 1419 SdDtcTempUnvIndOn 0 "FALSE" 1 "TRUE" ;
VAL_ 1419 SBZAlrtOffIndOn 0 "FALSE" 1 "TRUE" ;
VAL_ 1419 SBZAlrtCstStAvl 0 "FALSE" 1 "TRUE" ;
VAL_ 1408 TrffcLgtAsstWrnChmEvntStat 0 "NO_ACTION" 1 "ACTIVE" 2 "CANCEL_CHIME" 3 "RESERVED_1" ;
VAL_ 1408 TrffcLgtAsstCstCurrSetVal 0 "SETTING_UNKNOWN" 1 "OFF" 2 "ALERT" 3 "RESERVED_3" 4 "RESERVED_4" 5 "RESERVED_5" 6 "RESERVED_6" 7 "RESERVED_7" ;
VAL_ 1408 GlrFrHgBmRspTypCstCurSetVal 0 "SETTING_UNKNOWN" 1 "AUTOMATIC_HIGH_BEAM" 2 "GLARE_FREE_HIGH_BEAM" 3 "RESERVED_3" 4 "\?? RESERVED_4" 5 "RESERVED_5" 6 "RESERVED_6" 7 "RESERVED_7" ;
VAL_ 1408 GlrFrHgBmRspTypCstAvlFlg7 0 "FALSE" 1 "TRUE" ;
VAL_ 1408 GlrFrHgBmRspTypCstAvlFlg6 0 "FALSE" 1 "TRUE" ;
VAL_ 1408 GlrFrHgBmRspTypCstAvlFlg5 0 "FALSE" 1 "TRUE" ;
VAL_ 1408 GlrFrHgBmRspTypCstAvlFlg4 0 "FALSE" 1 "TRUE" ;
VAL_ 1408 GlrFrHgBmRspTypCstAvlFlg3 0 "FALSE" 1 "TRUE" ;
VAL_ 1408 GlrFrHgBmRspTypCstAvlFlg2 0 "FALSE" 1 "TRUE" ;
VAL_ 1408 GlrFrHgBmRspTypCstAvlFlg1 0 "FALSE" 1 "TRUE" ;
VAL_ 1408 AutoHgBmCtrlIO 0 "FALSE" 1 "TRUE" ;
VAL_ 1408 TrffcLgtAsstCstAvlFlg7 0 "FALSE" 1 "TRUE" ;
VAL_ 1408 TrffcLgtAsstCstAvlFlg6 0 "FALSE" 1 "TRUE" ;
VAL_ 1408 TrffcLgtAsstCstAvlFlg5 0 "FALSE" 1 "TRUE" ;
VAL_ 1408 TrffcLgtAsstCstAvlFlg4 0 "FALSE" 1 "TRUE" ;
VAL_ 1408 TrffcLgtAsstCstAvlFlg3 0 "FALSE" 1 "TRUE" ;
VAL_ 1408 TrffcLgtAsstCstAvlFlg2 0 "FALSE" 1 "TRUE" ;
VAL_ 1408 TrffcLgtAsstCstAvlFlg1 0 "FALSE" 1 "TRUE" ;
VAL_ 1408 GlrFrHgBmRspTypCstStAvl 0 "FALSE" 1 "TRUE" ;
VAL_ 1408 TrffcLgtAsstCstSetAval 0 "FALSE" 1 "TRUE" ;
VAL_ 1423 TSMEurDispSgn2Mn 0 "UnKnown" 1 "No Sign Detected" 2 "End of Speed Limit" 3 "End of All Restrictions" 4 "Begin of Motorway" 5 "End of Motorway" 6 "Begin of Expressway" 7 "End of Expressway" 8 "Begin of Play Street Zone" 9 "End of Play Street Zone" 10 "Begin of Passing Restriction" 11 "End of Passing Restriction" 12 "No Entry" 13 "Begin of City Limits" 14 "End of City Limits" 15 "Speed Limit 5" 16 "Speed Limit 10" 17 "Speed Limit 15" 18 "Speed Limit 20" 19 "Speed Limit 25" 20 "Speed Limit 30" 21 "Speed Limit 35" 22 "Speed Limit 40" 23 "Speed Limit 45" 24 "Speed Limit 50" 25 "Speed Limit 55" 26 "Speed Limit 60" 27 "Speed Limit 65" 28 "Speed Limit 70" 29 "Speed Limit 75" 30 "Speed Limit 80" 31 "Speed Limit 85" 32 "Speed Limit 90" 33 "Speed Limit 95" 34 "Speed Limit 100" 35 "Speed Limit 105" 36 "Speed Limit 110" 37 "Speed Limit 115" 38 "Speed Limit 120" 39 "Speed Limit 125" 40 "Speed Limit 130" 41 "Speed Limit 135" 42 "Speed Limit 140" 43 "Speed Limit 145" 44 "Speed Limit 150" 45 "Speed Limit 155" 46 "Speed Limit 160" 47 "Speed Limit 165" 48 "Speed Limit 170" 49 "Speed Limit 175" 50 "Speed Limit 180" 51 "Speed Limit 185" 52 "Speed Limit 190" 53 "Speed Limit 195" 54 "Speed Limit 200" ;
VAL_ 1423 TSMEurDispSgn1Mn 0 "UnKnown" 1 "No Sign Detected" 2 "End of Speed Limit" 3 "End of All Restrictions" 4 "Begin of Motorway" 5 "End of Motorway" 6 "Begin of Expressway" 7 "End of Expressway" 8 "Begin of Play Street Zone" 9 "End of Play Street Zone" 10 "Begin of Passing Restriction" 11 "End of Passing Restriction" 12 "No Entry" 13 "Begin of City Limits" 14 "End of City Limits" 15 "Speed Limit 5" 16 "Speed Limit 10" 17 "Speed Limit 15" 18 "Speed Limit 20" 19 "Speed Limit 25" 20 "Speed Limit 30" 21 "Speed Limit 35" 22 "Speed Limit 40" 23 "Speed Limit 45" 24 "Speed Limit 50" 25 "Speed Limit 55" 26 "Speed Limit 60" 27 "Speed Limit 65" 28 "Speed Limit 70" 29 "Speed Limit 75" 30 "Speed Limit 80" 31 "Speed Limit 85" 32 "Speed Limit 90" 33 "Speed Limit 95" 34 "Speed Limit 100" 35 "Speed Limit 105" 36 "Speed Limit 110" 37 "Speed Limit 115" 38 "Speed Limit 120" 39 "Speed Limit 125" 40 "Speed Limit 130" 41 "Speed Limit 135" 42 "Speed Limit 140" 43 "Speed Limit 145" 44 "Speed Limit 150" 45 "Speed Limit 155" 46 "Speed Limit 160" 47 "Speed Limit 165" 48 "Speed Limit 170" 49 "Speed Limit 175" 50 "Speed Limit 180" 51 "Speed Limit 185" 52 "Speed Limit 190" 53 "Speed Limit 195" 54 "Speed Limit 200" ;
VAL_ 1423 TSMUSAndCADispSgn1Mn 0 "UnKnown" 1 "No Sign Detected" 2 "Begin of Passing Restriction US" 3 "End of Passing Restriction US" 4 "Begin of Passing Restriction Canada" 5 "End of Passing Restriction Canada" 6 "Speed Limit 5" 7 "Speed Limit 10" 8 "Speed Limit 15" 9 "Speed Limit 20" 10 "Speed Limit 25" 11 "Speed Limit 30" 12 "Speed Limit 35" 13 "Speed Limit 40" 14 "Speed Limit 45" 15 "Speed Limit 50" 16 "Speed Limit 55" 17 "Speed Limit 60" 18 "Speed Limit 65" 19 "Speed Limit 70" 20 "Speed Limit 75" 21 "Speed Limit 80" 22 "Speed Limit 85" 23 "Speed Limit 90" 24 "Speed Limit 95" 25 "Speed Limit 100" 26 "Speed Limit 105" 27 "Speed Limit 110" 28 "Speed Limit 115" 29 "Speed Limit 120" 30 "Speed Limit 125" 31 "Speed Limit 130" 32 "Speed Limit 135" 33 "Speed Limit 140" 34 "Speed Limit 145" 35 "Speed Limit 150" 36 "Speed Limit 155" 37 "Speed Limit 160" 38 "Speed Limit 165" 39 "Speed Limit 170" 40 "Speed Limit 175" 41 "Speed Limit 180" 42 "Speed Limit 185" 43 "Speed Limit 190" 44 "Speed Limit 195" 45 "Speed Limit 200" ;
VAL_ 1423 TSMUSAndCADispSgn2Mn 0 "UnKnown" 1 "No Sign Detected" 2 "Begin of Passing Restriction US" 3 "End of Passing Restriction US" 4 "Begin of Passing Restriction Canada" 5 "End of Passing Restriction Canada" 6 "Speed Limit 5" 7 "Speed Limit 10" 8 "Speed Limit 15" 9 "Speed Limit 20" 10 "Speed Limit 25" 11 "Speed Limit 30" 12 "Speed Limit 35" 13 "Speed Limit 40" 14 "Speed Limit 45" 15 "Speed Limit 50" 16 "Speed Limit 55" 17 "Speed Limit 60" 18 "Speed Limit 65" 19 "Speed Limit 70" 20 "Speed Limit 75" 21 "Speed Limit 80" 22 "Speed Limit 85" 23 "Speed Limit 90" 24 "Speed Limit 95" 25 "Speed Limit 100" 26 "Speed Limit 105" 27 "Speed Limit 110" 28 "Speed Limit 115" 29 "Speed Limit 120" 30 "Speed Limit 125" 31 "Speed Limit 130" 32 "Speed Limit 135" 33 "Speed Limit 140" 34 "Speed Limit 145" 35 "Speed Limit 150" 36 "Speed Limit 155" 37 "Speed Limit 160" 38 "Speed Limit 165" 39 "Speed Limit 170" 40 "Speed Limit 175" 41 "Speed Limit 180" 42 "Speed Limit 185" 43 "Speed Limit 190" 44 "Speed Limit 195" 45 "Speed Limit 200" ;
VAL_ 1423 TSMEurDispSgn2AddOn 0 "UnKnown" 1 "None" 2 "Supp Sign Generic" 3 "Rain" 4 "Snow" 5 "Snow Rain" 6 "Rain Cloud" 7 "Fog" 8 "Time" 9 "Wet Conditions" 10 "Trailer" 11 "Tractor Passable" 12 "Arrow Left" 13 "Arrow Right" 14 "Distance Arrow" 15 "School" ;
VAL_ 1423 TSMEurDispSgn1AddOn 0 "UnKnown" 1 "None" 2 "Supp Sign Generic" 3 "Rain" 4 "Snow" 5 "Snow Rain" 6 "Rain Cloud" 7 "Fog" 8 "Time" 9 "Wet Conditions" 10 "Trailer" 11 "Tractor Passable" 12 "Arrow Left" 13 "Arrow Right" 14 "Distance Arrow" 15 "School" ;
VAL_ 1423 FrwdVsFlDtcnIndOn 0 "FALSE" 1 "TRUE" ;
VAL_ 1423 FrwdVsAdvWthrIndOn 0 "FALSE" 1 "TRUE" ;
VAL_ 1423 TSMUSAndCADispSgn2AddOn 0 "None" 1 "Supp Sign Generic" 2 "School" 3 "School When Flashing" 4 "End of Speed Limit" 5 "Where Workers Present" ;
VAL_ 1423 TSMUSAndCADispSgn1AddOn 0 "None" 1 "Supp Sign Generic" 2 "School" 3 "School When Flashing" 4 "End of Speed Limit" 5 "Where Workers Present" ;
VAL_ 1423 TrffcLgtAsstHUDWrnIndOn 0 "FALSE" 1 "TRUE" ;
VAL_ 1423 TrffcLgtAsstClstrWrnIndOn 0 "FALSE" 1 "TRUE" ;
VAL_ 1423 TSMSgnNtfnIndOn 0 "FALSE" 1 "TRUE" ;
VAL_ 1423 TSMPDAMnSgnFlshgReq 0 "FALSE" 1 "TRUE" ;
VAL_ 1423 TSMNoEntryIndOn 0 "FALSE" 1 "TRUE" ;
VAL_ 1423 TSMIcePsblIndOn 0 "FALSE" 1 "TRUE" ;
VAL_ 1423 TSMAddTrfSgnAvIndOn 0 "FALSE" 1 "TRUE" ;
VAL_ 1423 FrwdVsFllBlckIndOn 0 "FALSE" 1 "TRUE" ;
VAL_ 1423 TrffcLgtAsstRLADWrnIndOn 0 "FALSE" 1 "TRUE" ;
VAL_ 1420 SBZALCAVisIndStatLt 0 "FLASHING" 1 "SOLID" 2 "OFF" ;
VAL_ 1421 SBZALCAVisIndStatRt 0 "FLASHING" 1 "SOLID" 2 "OFF" ;
VAL_ 1418 AutoHgBmActReq 0 "FALSE" 1 "TRUE" ;
VAL_ 681 LtFstAprchgVehObjDtd 0 "FALSE" 1 "TRUE" ;
VAL_ 1410 RrCrsTrfcAlrtLftIndCtrl 0 "ON" 1 "OFF" 2 "FLASH" ;
VAL_ 1410 RrCrsTrfcAlrtCstCrStVal 0 "SETTING_UNKNOWN" 1 "OFF" 2 "ALERT" 3 "ALERT and BRAKE" 4 "RESERVED_4" 5 "RESERVED_5" 6 "RESERVED_6" 7 "RESERVED_7" ;
VAL_ 1410 LnChgAlrtCstCrStVal 0 "SETTING_UNKNOWN" 1 "OFF" 2 "ON" 3 "RESERVED_3" 4 "RESERVED_4" 5 "RESERVED_5" 6 "RESERVED_6" 7 "RESERVED_7" ;
VAL_ 1428 LtSdVehObjDtd 0 "FALSE" 1 "TRUE" ;
VAL_ 1428 SBZALCAOvrllOplSts 0 "NORMAL OPERATION" 1 "NEEDS SERVICE" 2 "TEMPORARY UNAVAILABLE" ;
VAL_ 192 RCTBAD_BrkgReqd 0 "FALSE" 1 "TRUE" ;
VAL_ 192 RCTBAD_BrkgReqTyp 0 "None" 1 "Hold" ;
VAL_ 1411 SBZAlrtCstCrStVal 0 "SETTING_UNKNOWN" 1 "OFF" 2 "ON" 3 "RESERVED_3" 4 "RESERVED_4" 5 "RESERVED_5" 6 "RESERVED_6" 7 "RESERVED_7" ;
VAL_ 1411 ByclDtnCstCurrSetVal 0 "Setting Unknown" 1 "Off" 2 "Alert" ;
VAL_ 1411 ByclDtnArbdIndStat 0 "No Indication" 1 "Off" 2 "Right Level 1" 3 "Left Level 1" 4 "Right Level 2" 5 "Left Level 2" 6 "Left and Right Level 1" 7 "Left and Right Level 2" ;
VAL_ 1411 ByclDtnCstAvlFlg1 0 "FALSE" 1 "TRUE" ;
VAL_ 1411 RrCrsTrfcAlrtLtSdChmEvntStat 0 "NO_ACTION" 1 "ACTIVE" 2 "CANCEL_CHIME" ;
VAL_ 1411 ByclDtnArbdLvl2ChmEvntStat 0 "No Action" 1 "Active" 2 "Cancel Chime" ;
VAL_ 1411 ByclDtnArbdLvl1ChmEvntStat 0 "No Action" 1 "Active" 2 "Cancel Chime" ;
VAL_ 1411 LnChgAlrtCstAvlFlg1 0 "FALSE" 1 "TRUE" ;
VAL_ 1411 ByclDtnCstSetAval 0 "FALSE" 1 "TRUE" ;
VAL_ 1411 ByclDtnCstAvlFlg7 0 "FALSE" 1 "TRUE" ;
VAL_ 1411 ByclDtnCstAvlFlg6 0 "FALSE" 1 "TRUE" ;
VAL_ 1411 ByclDtnCstAvlFlg5 0 "FALSE" 1 "TRUE" ;
VAL_ 1411 ByclDtnCstAvlFlg4 0 "FALSE" 1 "TRUE" ;
VAL_ 1411 ByclDtnCstAvlFlg3 0 "FALSE" 1 "TRUE" ;
VAL_ 1411 ByclDtnCstAvlFlg2 0 "FALSE" 1 "TRUE" ;
VAL_ 1411 LnChgAlrtSysOffIndOn 0 "FALSE" 1 "TRUE" ;
VAL_ 1411 LnChgAlrtCstStAvl 0 "FALSE" 1 "TRUE" ;
VAL_ 1411 LnChgAlrtCstAvlFlg7 0 "FALSE" 1 "TRUE" ;
VAL_ 1411 LnChgAlrtCstAvlFlg6 0 "FALSE" 1 "TRUE" ;
VAL_ 1411 LnChgAlrtCstAvlFlg5 0 "FALSE" 1 "TRUE" ;
VAL_ 1411 LnChgAlrtCstAvlFlg4 0 "FALSE" 1 "TRUE" ;
VAL_ 1411 LnChgAlrtCstAvlFlg3 0 "FALSE" 1 "TRUE" ;
VAL_ 1411 LnChgAlrtCstAvlFlg2 0 "FALSE" 1 "TRUE" ;
VAL_ 1411 RrCrsTrfcAlrtCstStAvl 0 "FALSE" 1 "TRUE" ;
VAL_ 1411 RrCrsTrfcAlrtCstAvlFlg7 0 "FALSE" 1 "TRUE" ;
VAL_ 1411 RrCrsTrfcAlrtCstAvlFlg6 0 "FALSE" 1 "TRUE" ;
VAL_ 1411 RrCrsTrfcAlrtCstAvlFlg5 0 "FALSE" 1 "TRUE" ;
VAL_ 1411 RrCrsTrfcAlrtCstAvlFlg4 0 "FALSE" 1 "TRUE" ;
VAL_ 1411 RrCrsTrfcAlrtCstAvlFlg3 0 "FALSE" 1 "TRUE" ;
VAL_ 1411 RrCrsTrfcAlrtCstAvlFlg2 0 "FALSE" 1 "TRUE" ;
VAL_ 1411 RrCrsTrfcAlrtCstAvlFlg1 0 "FALSE" 1 "TRUE" ;
VAL_ 1411 RrCrsTrfcBrkgAutoBrkgRelIndOn 0 "FALSE" 1 "TRUE" ;
VAL_ 1411 RrCrsTrfcAutoBrkgOffIndOn 0 "FALSE" 1 "TRUE" ;
VAL_ 1411 RrCrsTrfcAlrtOffIndOn 0 "FALSE" 1 "TRUE" ;
VAL_ 719 RtFstAprchgVehObjDtd 0 "FALSE" 1 "TRUE" ;
VAL_ 1413 RtSdVehObjDtd 0 "FALSE" 1 "TRUE" ;
VAL_ 1413 RrCrsTrfcAlrtRtSdChmEvntStat 0 "NO_ACTION" 1 "ACTIVE" 2 "CANCEL_CHIME" ;
VAL_ 1413 RrCrsTrfcAlrtRgIndCtrl 0 "ON" 1 "OFF" 2 "FLASH" ;
VAL_ 162 PAOG1_Hght1 0 "Unknown" 1 "Traversable" 2 "High Object" 3 "Low Object" ;
VAL_ 162 PAOG1_Cnfd1 0 "Highly Speculative" 1 "Speculative" 2 "Confident" 3 "Highly Confident" ;
VAL_ 162 PAOG1_Typ1 0 "NoObject" 1 "Straight_0Corner" 2 "Straight_1Corner" 3 "Straight_2Corners" 4 "Point" 5 "Curbstone" 6 "Blind Area" ;
VAL_ 536 PAOG2_Hght2 0 "Unknown" 1 "Traversable" 2 "High Object" 3 "Low Object" ;
VAL_ 536 PAOG2_Cnfd2 0 "Highly Speculative" 1 "Speculative" 2 "Confident" 3 "Highly Confident" ;
VAL_ 536 PAOG2_Typ2 0 "NoObject" 1 "Straight_0Corner" 2 "Straight_1Corner" 3 "Straight_2Corners" 4 "Point" 5 "Curbstone" 6 "Blind Area" ;
VAL_ 523 PAOG3_Hght3 0 "Unknown" 1 "Traversable" 2 "High Object" 3 "Low Object" ;
VAL_ 523 PAOG3_Cnfd3 0 "Highly Speculative" 1 "Speculative" 2 "Confident" 3 "Highly Confident" ;
VAL_ 523 PAOG3_Typ3 0 "NoObject" 1 "Straight_0Corner" 2 "Straight_1Corner" 3 "Straight_2Corners" 4 "Point" 5 "Curbstone" 6 "Blind Area" ;
VAL_ 241 LRRODPB2P_POTk2DynPrpAuth 0 "Has Never Moved" 1 "Has Moved But Currently Stopped" 2 "Moving In Same Direction As Host" 3 "Moving In Opposite Direction As Host" 4 "Crossing Path" ;
VAL_ 241 LRRODPB2P_POTk2CnfdStsAuth 0 "Highly Speculative" 1 "Speculative" 2 "Confident" 3 "Highly Confident" ;
VAL_ 241 LRRODPB2P_POTk2MStsAuth 0 "No Object" 1 "New Object" 2 "Latent Track Not Detected this Cycle" 3 "Measured this Cycle" ;
VAL_ 241 LRRODPB2P_POTk2TypCnfdAuth 0 "Highly Speculative" 1 "Speculative" 2 "Confident" 3 "Highly Confident" ;
VAL_ 241 LRRODPB2P_POTk2TypAuth 0 "Unknown" 1 "Pedestrian" 2 "Bicycle" ;
VAL_ 241 LRRODPB2P_VOTk3DynPrpStsAuth 0 "Stopped" 1 "Not Stopped" ;
VAL_ 241 LRRODPB2P_VOTk3DynPrpAuth 0 "Has Never Moved" 1 "Moving In Same Direction As Host" 2 "Moving In Opposite Direction As Host" 3 "Crossing From Left To Right" 4 "Crossing From Right To Left" ;
VAL_ 241 LRRODPB2P_VOTk3CnfdStsAuth 0 "Highly Speculative" 1 "Speculative" 2 "Confident" 3 "Highly Confident" ;
VAL_ 241 LRRODPB2P_VOTk3MStsAuth 0 "No Object" 1 "New Object" 2 "Latent Track Not Detected this Cycle" 3 "Measured this Cycle" ;
VAL_ 241 LRRODPB2P_VOTk3TypCnfdAuth 0 "Highly Speculative" 1 "Speculative" 2 "Confident" 3 "Highly Confident" ;
VAL_ 241 LRRODPB2P_VOTk4DynPrpStsAuth 0 "Stopped" 1 "Not Stopped" ;
VAL_ 241 LRRODPB2P_VOTk4DynPrpAuth 0 "Has Never Moved" 1 "Moving In Same Direction As Host" 2 "Moving In Opposite Direction As Host" 3 "Crossing From Left To Right" 4 "Crossing From Right To Left" ;
VAL_ 241 LRRODPB2P_VOTk4CnfdStsAuth 0 "Highly Speculative" 1 "Speculative" 2 "Confident" 3 "Highly Confident" ;
VAL_ 241 LRRODPB2P_VOTk4MStsAuth 0 "No Object" 1 "New Object" 2 "Latent Track Not Detected this Cycle" 3 "Measured this Cycle" ;
VAL_ 241 LRRODPB2P_VOTk4TypCnfdAuth 0 "Highly Speculative" 1 "Speculative" 2 "Confident" 3 "Highly Confident" ;
VAL_ 241 LRRODPB2P_VOTk5CnfdStsAuth 0 "Highly Speculative" 1 "Speculative" 2 "Confident" 3 "Highly Confident" ;
VAL_ 241 LRRODPB2P_VOTk5DynPrpStsAuth 0 "Stopped" 1 "Not Stopped" ;
VAL_ 241 LRRODPB2P_VOTk5DynPrpAuth 0 "Has Never Moved" 1 "Moving In Same Direction As Host" 2 "Moving In Opposite Direction As Host" 3 "Crossing From Left To Right" 4 "Crossing From Right To Left" ;
VAL_ 241 LRRODPB2P_VOTk5MStsAuth 0 "No Object" 1 "New Object" 2 "Latent Track Not Detected this Cycle" 3 "Measured this Cycle" ;
VAL_ 241 LRRODPB2P_VOTk5TypCnfdAuth 0 "Highly Speculative" 1 "Speculative" 2 "Confident" 3 "Highly Confident" ;
